VERSION "HNNBNNNYNNNNNNNNNNNNNNNNNNNNNNNNNNNNNNNNNN/4/%%%/4/'%**4NNN///"

NS_ :

BS_:

BU_: BAP_Tester Gateway_Max Getriebe_DQ Motor_konv Parksperre Schaltbetaetigung

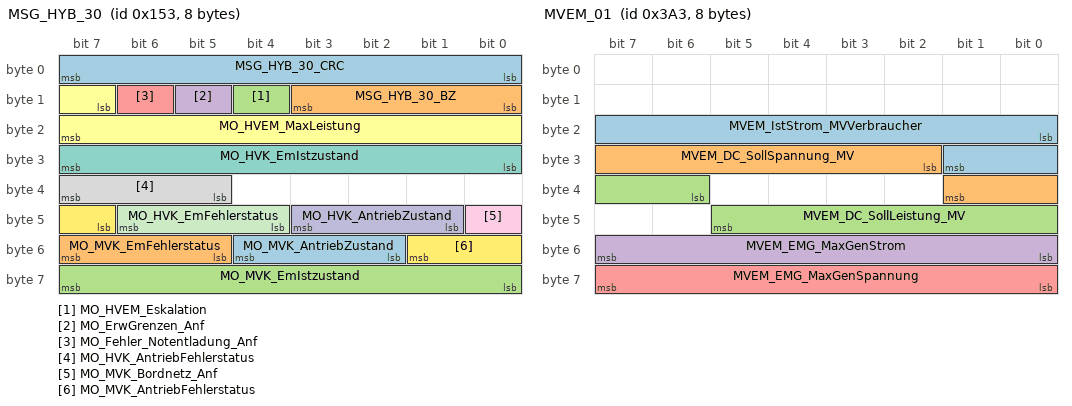
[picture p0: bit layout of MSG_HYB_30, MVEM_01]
BO_ 339 MSG_HYB_30: 8 Motor_konv
 SG_ MSG_HYB_30_CRC : 0|8@1+ (1,0) [0|255] ""  Gateway_Max
 SG_ MSG_HYB_30_BZ : 8|4@1+ (1,0) [0|15] ""  Gateway_Max
 SG_ MO_HVEM_Eskalation : 12|1@1+ (1.0,0.0) [0.0|1] ""  Gateway_Max
 SG_ MO_ErwGrenzen_Anf : 13|1@1+ (1.0,0.0) [0.0|1] ""  Gateway_Max
 SG_ MO_Fehler_Notentladung_Anf : 14|1@1+ (1.0,0.0) [0.0|1] ""  Gateway_Max
 SG_ MO_HVEM_MaxLeistung : 15|9@1+ (50,0) [0|25450] "Unit_Watt"  Gateway_Max
 SG_ MO_HVK_EmIstzustand : 24|8@1+ (1.0,0.0) [0.0|255] ""  Gateway_Max
 SG_ MO_HVK_AntriebFehlerstatus : 37|3@1+ (1.0,0.0) [0.0|7] ""  Gateway_Max
 SG_ MO_MVK_Bordnetz_Anf : 40|1@1+ (1.0,0.0) [0.0|1] ""  Gateway_Max
 SG_ MO_HVK_AntriebZustand : 41|3@1+ (1.0,0.0) [0.0|7] ""  Gateway_Max
 SG_ MO_HVK_EmFehlerstatus : 44|3@1+ (1.0,0.0) [0.0|7] ""  Gateway_Max
 SG_ MO_MVK_AntriebFehlerstatus : 47|3@1+ (1.0,0.0) [0.0|7] ""  Gateway_Max
 SG_ MO_MVK_AntriebZustand : 50|3@1+ (1.0,0.0) [0.0|7] ""  Gateway_Max
 SG_ MO_MVK_EmFehlerstatus : 53|3@1+ (1.0,0.0) [0.0|7] ""  Gateway_Max
 SG_ MO_MVK_EmIstzustand : 56|8@1+ (1.0,0.0) [0.0|255] ""  Gateway_Max

BO_ 931 MVEM_01: 8 Gateway_Max
 SG_ MVEM_IstStrom_MVVerbraucher : 16|10@1+ (1,-511) [-511|510] "Unit_Amper"  Motor_konv
 SG_ MVEM_DC_SollSpannung_MV : 26|8@1+ (0.25,0) [0.00|63.25] "Unit_Volt"  Vector__XXX
 SG_ MVEM_DC_SollLeistung_MV : 38|8@1+ (25,-6325) [-6325|0] "Unit_Watt"  Vector__XXX
 SG_ MVEM_EMG_MaxGenStrom : 48|8@1+ (2,0) [0|506] "Unit_Amper"  Vector__XXX
 SG_ MVEM_EMG_MaxGenSpannung : 56|8@1+ (0.25,0) [0.00|63.25] "Unit_Volt"  Vector__XXX

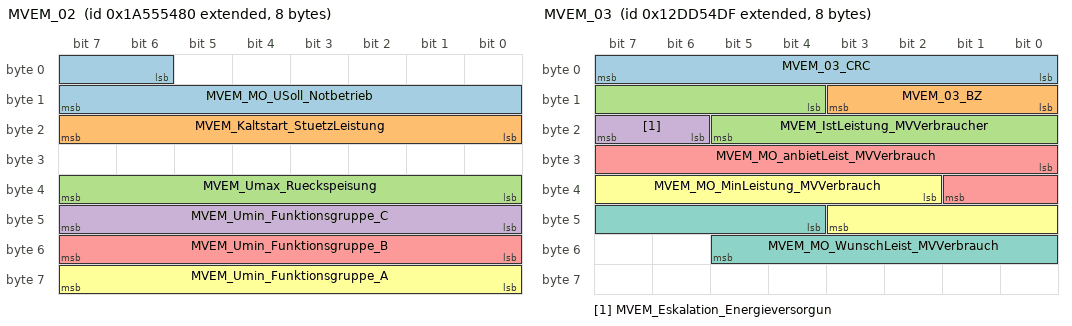
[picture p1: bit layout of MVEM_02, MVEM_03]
BO_ 2589283456 MVEM_02: 8 Gateway_Max
 SG_ MVEM_MO_USoll_Notbetrieb : 6|10@1+ (0.0625,0) [0.0000|63.8125] "Unit_Volt"  Motor_konv
 SG_ MVEM_Kaltstart_StuetzLeistung : 16|8@1+ (20,0) [0|5060] "Unit_Watt"  Vector__XXX
 SG_ MVEM_Umax_Rueckspeisung : 32|8@1+ (0.25,0) [0.00|63.25] "Unit_Volt"  Vector__XXX
 SG_ MVEM_Umin_Funktionsgruppe_C : 40|8@1+ (0.25,0) [0.00|63.25] "Unit_Volt"  Vector__XXX
 SG_ MVEM_Umin_Funktionsgruppe_B : 48|8@1+ (0.25,0) [0.00|63.25] "Unit_Volt"  Vector__XXX
 SG_ MVEM_Umin_Funktionsgruppe_A : 56|8@1+ (0.25,0) [0.00|63.25] "Unit_Volt"  Vector__XXX

BO_ 2463978719 MVEM_03: 8 Gateway_Max
 SG_ MVEM_03_CRC : 0|8@1+ (1,0) [0|255] ""  Motor_konv
 SG_ MVEM_03_BZ : 8|4@1+ (1,0) [0|15] ""  Motor_konv
 SG_ MVEM_IstLeistung_MVVerbraucher : 12|10@1+ (50,-10500) [-10500|40500] "Unit_Watt"  Motor_konv
 SG_ MVEM_Eskalation_Energieversorgun : 22|2@1+ (1.0,0.0) [0.0|3] ""  Motor_konv
 SG_ MVEM_MO_anbietLeist_MVVerbrauch : 24|10@1+ (50,-10500) [-10500|40500] "Unit_Watt"  Vector__XXX
 SG_ MVEM_MO_MinLeistung_MVVerbrauch : 34|10@1+ (50,-10500) [-10500|40500] "Unit_Watt"  Vector__XXX
 SG_ MVEM_MO_WunschLeist_MVVerbrauch : 44|10@1+ (50,-10500) [-10500|40500] "Unit_Watt"  Vector__XXX

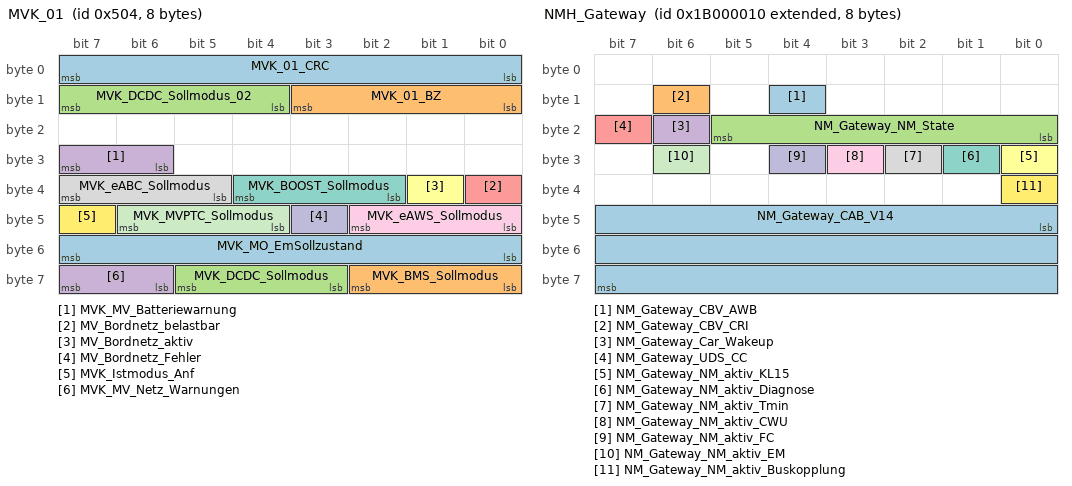
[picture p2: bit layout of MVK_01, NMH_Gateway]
BO_ 1284 MVK_01: 8 Gateway_Max
 SG_ MVK_01_CRC : 0|8@1+ (1,0) [0|255] ""  Vector__XXX
 SG_ MVK_01_BZ : 8|4@1+ (1,0) [0|15] ""  Vector__XXX
 SG_ MVK_DCDC_Sollmodus_02 : 12|4@1+ (1.0,0.0) [0.0|15] ""  Vector__XXX
 SG_ MVK_MV_Batteriewarnung : 30|2@1+ (1.0,0.0) [0.0|3] ""  Vector__XXX
 SG_ MV_Bordnetz_belastbar : 32|1@1+ (1.0,0.0) [0.0|1] ""  Vector__XXX
 SG_ MV_Bordnetz_aktiv : 33|1@1+ (1.0,0.0) [0.0|1] ""  Vector__XXX
 SG_ MVK_BOOST_Sollmodus : 34|3@1+ (1.0,0.0) [0.0|7] ""  Vector__XXX
 SG_ MVK_eABC_Sollmodus : 37|3@1+ (1.0,0.0) [0.0|7] ""  Vector__XXX
 SG_ MVK_eAWS_Sollmodus : 40|3@1+ (1.0,0.0) [0.0|7] ""  Vector__XXX
 SG_ MV_Bordnetz_Fehler : 43|1@1+ (1.0,0.0) [0.0|1] ""  Vector__XXX
 SG_ MVK_MVPTC_Sollmodus : 44|3@1+ (1.0,0.0) [0.0|7] ""  Vector__XXX
 SG_ MVK_Istmodus_Anf : 47|1@1+ (1.0,0.0) [0.0|1] ""  Vector__XXX
 SG_ MVK_MO_EmSollzustand : 48|8@1+ (1.0,0.0) [0.0|255] ""  Motor_konv
 SG_ MVK_BMS_Sollmodus : 56|3@1+ (1.0,0.0) [0.0|7] ""  Vector__XXX
 SG_ MVK_DCDC_Sollmodus : 59|3@1+ (1.0,0.0) [0.0|7] ""  Vector__XXX
 SG_ MVK_MV_Netz_Warnungen : 62|2@1+ (1.0,0.0) [0.0|3] ""  Vector__XXX

BO_ 2600468496 NMH_Gateway: 8 Gateway_Max
 SG_ NM_Gateway_CBV_AWB : 12|1@1+ (1.0,0.0) [0.0|1] ""  Vector__XXX
 SG_ NM_Gateway_CBV_CRI : 14|1@1+ (1.0,0.0) [0.0|1] ""  Vector__XXX
 SG_ NM_Gateway_NM_State : 16|6@1+ (1.0,0.0) [0.0|63] ""  Getriebe_DQ,Motor_konv,Parksperre,Schaltbetaetigung
 SG_ NM_Gateway_Car_Wakeup : 22|1@1+ (1.0,0.0) [0.0|1] ""  Vector__XXX
 SG_ NM_Gateway_UDS_CC : 23|1@1+ (1.0,0.0) [0.0|1] ""  Vector__XXX
 SG_ NM_Gateway_NM_aktiv_KL15 : 24|1@1+ (1.0,0.0) [0.0|1] ""  Vector__XXX
 SG_ NM_Gateway_NM_aktiv_Diagnose : 25|1@1+ (1.0,0.0) [0.0|1] ""  Vector__XXX
 SG_ NM_Gateway_NM_aktiv_Tmin : 26|1@1+ (1.0,0.0) [0.0|1] ""  Vector__XXX
 SG_ NM_Gateway_NM_aktiv_CWU : 27|1@1+ (1.0,0.0) [0.0|1] ""  Vector__XXX
 SG_ NM_Gateway_NM_aktiv_FC : 28|1@1+ (1.0,0.0) [0.0|1] ""  Vector__XXX
 SG_ NM_Gateway_NM_aktiv_EM : 30|1@1+ (1.0,0.0) [0.0|1] ""  Vector__XXX
 SG_ NM_Gateway_NM_aktiv_Buskopplung : 32|1@1+ (1.0,0.0) [0.0|1] ""  Vector__XXX
 SG_ NM_Gateway_CAB_V14 : 40|24@1+ (1.0,0.0) [0.0|16777215] ""  Vector__XXX

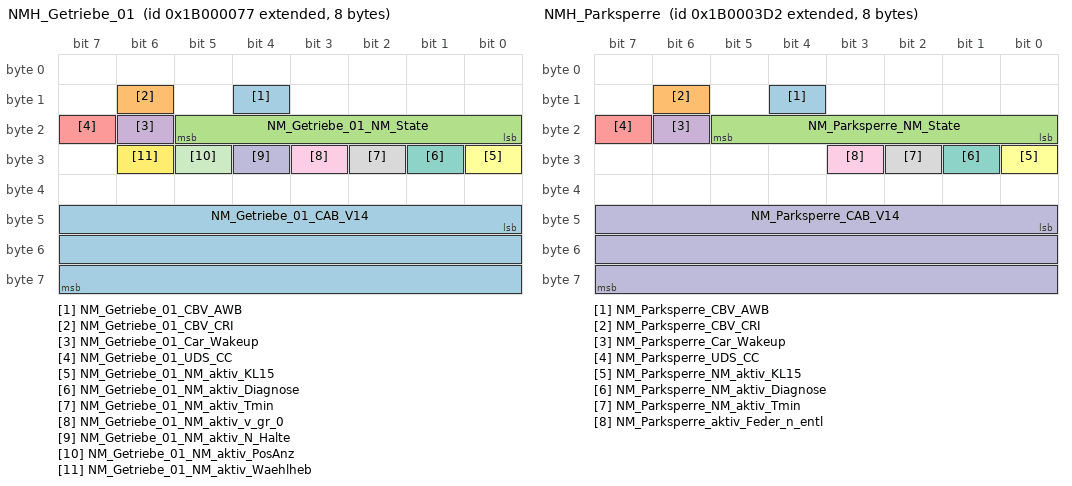
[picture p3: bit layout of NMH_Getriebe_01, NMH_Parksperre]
BO_ 2600468599 NMH_Getriebe_01: 8 Getriebe_DQ
 SG_ NM_Getriebe_01_CBV_AWB : 12|1@1+ (1.0,0.0) [0.0|1] ""  Gateway_Max
 SG_ NM_Getriebe_01_CBV_CRI : 14|1@1+ (1.0,0.0) [0.0|1] ""  Gateway_Max
 SG_ NM_Getriebe_01_NM_State : 16|6@1+ (1.0,0.0) [0.0|63] ""  Motor_konv,Parksperre,Schaltbetaetigung
 SG_ NM_Getriebe_01_Car_Wakeup : 22|1@1+ (1.0,0.0) [0.0|1] ""  Gateway_Max
 SG_ NM_Getriebe_01_UDS_CC : 23|1@1+ (1.0,0.0) [0.0|1] ""  Vector__XXX
 SG_ NM_Getriebe_01_NM_aktiv_KL15 : 24|1@1+ (1.0,0.0) [0.0|1] ""  Vector__XXX
 SG_ NM_Getriebe_01_NM_aktiv_Diagnose : 25|1@1+ (1.0,0.0) [0.0|1] ""  Vector__XXX
 SG_ NM_Getriebe_01_NM_aktiv_Tmin : 26|1@1+ (1.0,0.0) [0.0|1] ""  Vector__XXX
 SG_ NM_Getriebe_01_NM_aktiv_v_gr_0 : 27|1@1+ (1.0,0.0) [0.0|1] ""  Vector__XXX
 SG_ NM_Getriebe_01_NM_aktiv_N_Halte : 28|1@1+ (1.0,0.0) [0.0|1] ""  Vector__XXX
 SG_ NM_Getriebe_01_NM_aktiv_PosAnz : 29|1@1+ (1.0,0.0) [0.0|1] ""  Vector__XXX
 SG_ NM_Getriebe_01_NM_aktiv_Waehlheb : 30|1@1+ (1.0,0.0) [0.0|1] ""  Vector__XXX
 SG_ NM_Getriebe_01_CAB_V14 : 40|24@1+ (1.0,0.0) [0.0|16777215] ""  Gateway_Max

BO_ 2600468598 NMH_MO_01: 8 Motor_konv
 SG_ NM_MO_01_CBV_AWB : 12|1@1+ (1.0,0.0) [0.0|1] ""  Gateway_Max
 SG_ NM_MO_01_CBV_CRI : 14|1@1+ (1.0,0.0) [0.0|1] ""  Gateway_Max
 SG_ NM_MO_01_NM_State : 16|6@1+ (1.0,0.0) [0.0|63] ""  Getriebe_DQ,Parksperre,Schaltbetaetigung
 SG_ NM_MO_01_Car_Wakeup : 22|1@1+ (1.0,0.0) [0.0|1] ""  Gateway_Max
 SG_ NM_MO_01_UDS_CC : 23|1@1+ (1.0,0.0) [0.0|1] ""  Vector__XXX
 SG_ NM_MO_01_NM_aktiv_KL15 : 24|1@1+ (1.0,0.0) [0.0|1] ""  Vector__XXX
 SG_ NM_MO_01_NM_aktiv_Diagnose : 25|1@1+ (1.0,0.0) [0.0|1] ""  Vector__XXX
 SG_ NM_MO_01_NM_aktiv_Tmin : 26|1@1+ (1.0,0.0) [0.0|1] ""  Vector__XXX
 SG_ NM_MO_01_NM_aktiv_Betankung : 27|1@1+ (1.0,0.0) [0.0|1] ""  Vector__XXX
 SG_ NM_MO_01_NM_aktiv_Oelstandsmes : 28|1@1+ (1.0,0.0) [0.0|1] ""  Vector__XXX
 SG_ NM_MO_01_NM_aktiv_Waehlhebel : 30|1@1+ (1.0,0.0) [0.0|1] ""  Vector__XXX
 SG_ NM_MO_01_NM_aktiv_NOx_PM_SensDia : 32|1@1+ (1.0,0.0) [0.0|1] ""  Vector__XXX
 SG_ NM_MO_01_NM_aktiv_Anf_RSG : 34|1@1+ (1.0,0.0) [0.0|1] ""  Vector__XXX
 SG_ NM_MO_01_NM_aktiv_HV_Abschaltung : 35|1@1+ (1.0,0.0) [0.0|1] ""  Vector__XXX
 SG_ NM_MO_01_NM_aktiv_EKP_Vorlauf : 36|1@1+ (1.0,0.0) [0.0|1] ""  Vector__XXX
 SG_ NM_MO_01_NM_aktiv_STH_Betrieb : 37|1@1+ (1.0,0.0) [0.0|1] ""  Vector__XXX
 SG_ NM_MO_01_NM_aktiv_Hochvolt : 38|1@1+ (1.0,0.0) [0.0|1] ""  Vector__XXX
 SG_ NM_MO_01_NM_aktiv_AnzKLuefter : 39|1@1+ (1.0,0.0) [0.0|1] ""  Vector__XXX
 SG_ NM_MO_01_CAB_V14 : 40|24@1+ (1.0,0.0) [0.0|16777215] ""  Gateway_Max

BO_ 2600469458 NMH_Parksperre: 8 Parksperre
 SG_ NM_Parksperre_CBV_AWB : 12|1@1+ (1.0,0.0) [0.0|1] ""  Gateway_Max
 SG_ NM_Parksperre_CBV_CRI : 14|1@1+ (1.0,0.0) [0.0|1] ""  Gateway_Max
 SG_ NM_Parksperre_NM_State : 16|6@1+ (1.0,0.0) [0.0|63] ""  Getriebe_DQ,Motor_konv,Schaltbetaetigung
 SG_ NM_Parksperre_Car_Wakeup : 22|1@1+ (1.0,0.0) [0.0|1] ""  Gateway_Max
 SG_ NM_Parksperre_UDS_CC : 23|1@1+ (1.0,0.0) [0.0|1] ""  Vector__XXX
 SG_ NM_Parksperre_NM_aktiv_KL15 : 24|1@1+ (1.0,0.0) [0.0|1] ""  Vector__XXX
 SG_ NM_Parksperre_NM_aktiv_Diagnose : 25|1@1+ (1.0,0.0) [0.0|1] ""  Vector__XXX
 SG_ NM_Parksperre_NM_aktiv_Tmin : 26|1@1+ (1.0,0.0) [0.0|1] ""  Vector__XXX
 SG_ NM_Parksperre_aktiv_Feder_n_entl : 27|1@1+ (1.0,0.0) [0.0|1] ""  Vector__XXX
 SG_ NM_Parksperre_CAB_V14 : 40|24@1+ (1.0,0.0) [0.0|16777215] ""  Gateway_Max

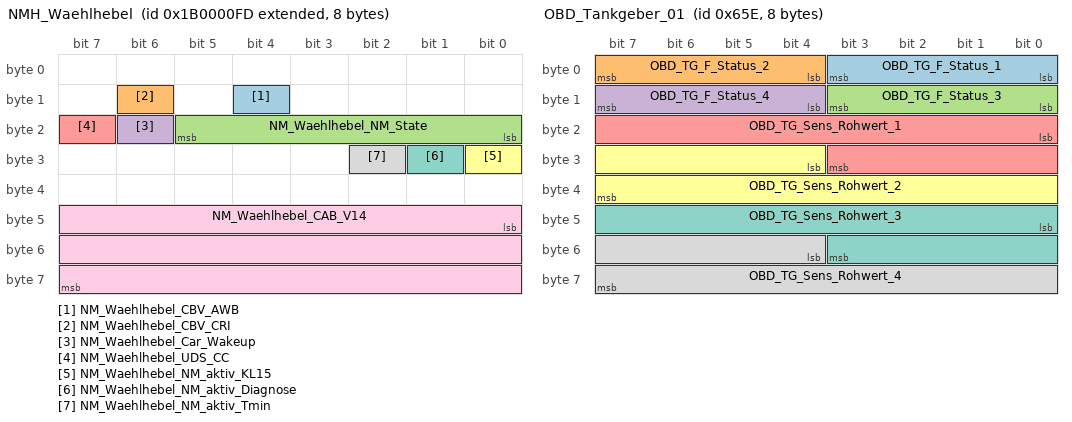
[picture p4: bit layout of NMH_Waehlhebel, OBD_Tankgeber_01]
BO_ 2600468733 NMH_Waehlhebel: 8 Schaltbetaetigung
 SG_ NM_Waehlhebel_CBV_AWB : 12|1@1+ (1.0,0.0) [0.0|1] ""  Gateway_Max
 SG_ NM_Waehlhebel_CBV_CRI : 14|1@1+ (1.0,0.0) [0.0|1] ""  Gateway_Max
 SG_ NM_Waehlhebel_NM_State : 16|6@1+ (1.0,0.0) [0.0|63] ""  Getriebe_DQ,Motor_konv,Parksperre
 SG_ NM_Waehlhebel_Car_Wakeup : 22|1@1+ (1.0,0.0) [0.0|1] ""  Gateway_Max
 SG_ NM_Waehlhebel_UDS_CC : 23|1@1+ (1.0,0.0) [0.0|1] ""  Vector__XXX
 SG_ NM_Waehlhebel_NM_aktiv_KL15 : 24|1@1+ (1.0,0.0) [0.0|1] ""  Vector__XXX
 SG_ NM_Waehlhebel_NM_aktiv_Diagnose : 25|1@1+ (1.0,0.0) [0.0|1] ""  Vector__XXX
 SG_ NM_Waehlhebel_NM_aktiv_Tmin : 26|1@1+ (1.0,0.0) [0.0|1] ""  Vector__XXX
 SG_ NM_Waehlhebel_CAB_V14 : 40|24@1+ (1.0,0.0) [0.0|16777215] ""  Gateway_Max

BO_ 1630 OBD_Tankgeber_01: 8 Gateway_Max
 SG_ OBD_TG_F_Status_1 : 0|4@1+ (1.0,0.0) [0.0|15] ""  Motor_konv
 SG_ OBD_TG_F_Status_2 : 4|4@1+ (1.0,0.0) [0.0|15] ""  Motor_konv
 SG_ OBD_TG_F_Status_3 : 8|4@1+ (1.0,0.0) [0.0|15] ""  Motor_konv
 SG_ OBD_TG_F_Status_4 : 12|4@1+ (1.0,0.0) [0.0|15] ""  Motor_konv
 SG_ OBD_TG_Sens_Rohwert_1 : 16|12@1+ (0.5,0) [0.0|2047.5] "Unit_Ohm"  Motor_konv
 SG_ OBD_TG_Sens_Rohwert_2 : 28|12@1+ (0.5,0) [0.0|2047.5] "Unit_Ohm"  Motor_konv
 SG_ OBD_TG_Sens_Rohwert_3 : 40|12@1+ (0.5,0) [0.0|2047.5] "Unit_Ohm"  Motor_konv
 SG_ OBD_TG_Sens_Rohwert_4 : 52|12@1+ (0.5,0) [0.0|2047.5] "Unit_Ohm"  Motor_konv

BO_ 2621440636 OBDC_EMotor_01_Req_FD: 64 Gateway_Max
 SG_ OBDC_EMotor_01_Req_FD_Data : 0|512@1+ (1.0,0.0) [0.0|13407807929942597099574024998205846127479365820592393377723561443721764030073546976801874298166903427690031858186486050853753882811946569946433649006084095] ""  Vector__XXX

BO_ 2621571708 OBDC_EMotor_01_Resp_FD: 64 Vector__XXX
 SG_ OBDC_EMotor_01_Resp_FD_Data : 0|512@1+ (1.0,0.0) [0.0|13407807929942597099574024998205846127479365820592393377723561443721764030073546976801874298166903427690031858186486050853753882811946569946433649006084095] ""  Gateway_Max

BO_ 2621440696 OBDC_EMotor_02_Req_FD: 64 Gateway_Max
 SG_ OBDC_EMotor_02_Req_FD_Data : 0|512@1+ (1.0,0.0) [0.0|13407807929942597099574024998205846127479365820592393377723561443721764030073546976801874298166903427690031858186486050853753882811946569946433649006084095] ""  Vector__XXX

BO_ 2621571768 OBDC_EMotor_02_Resp_FD: 64 Vector__XXX
 SG_ OBDC_EMotor_02_Resp_FD_Data : 0|512@1+ (1.0,0.0) [0.0|13407807929942597099574024998205846127479365820592393377723561443721764030073546976801874298166903427690031858186486050853753882811946569946433649006084095] ""  Gateway_Max

BO_ 2549940736 OBDC_Funktionaler_Req_All: 8 Gateway_Max
 SG_ OBDC_Funktionaler_Req_All_Data : 0|64@1+ (1.0,0.0) [0.0|18446744073709551615] ""  Vector__XXX

BO_ 2621506048 OBDC_Funktionaler_Req_All_FD: 64 Gateway_Max
 SG_ OBDC_Funktion_Req_All_FD_Data : 0|512@1+ (1.0,0.0) [0.0|13407807929942597099574024998205846127479365820592393377723561443721764030073546976801874298166903427690031858186486050853753882811946569946433649006084095] ""  Getriebe_DQ,Motor_konv

BO_ 2621440631 OBDC_Getriebe_01_Req_FD: 64 Gateway_Max
 SG_ OBDC_Getriebe_01_Req_FD_Data : 0|512@1+ (1.0,0.0) [0.0|13407807929942597099574024998205846127479365820592393377723561443721764030073546976801874298166903427690031858186486050853753882811946569946433649006084095] ""  Getriebe_DQ

BO_ 2621571703 OBDC_Getriebe_01_Resp_FD: 64 Getriebe_DQ
 SG_ OBDC_Getriebe_01_Resp_FD_Data : 0|512@1+ (1.0,0.0) [0.0|13407807929942597099574024998205846127479365820592393377723561443721764030073546976801874298166903427690031858186486050853753882811946569946433649006084095] ""  Gateway_Max

BO_ 2621702713 OBDC_LCU_SMH_Req_FD: 64 Gateway_Max
 SG_ OBDC_LCU_SMH_Req_FD_Data : 0|512@1+ (1.0,0.0) [0.0|13407807929942597099574024998205846127479365820592393377723561443721764030073546976801874298166903427690031858186486050853753882811946569946433649006084095] ""  Vector__XXX

BO_ 2621833785 OBDC_LCU_SMH_Resp_FD: 64 Vector__XXX
 SG_ OBDC_LCU_SMH_Resp_FD_Data : 0|512@1+ (1.0,0.0) [0.0|13407807929942597099574024998205846127479365820592393377723561443721764030073546976801874298166903427690031858186486050853753882811946569946433649006084095] ""  Gateway_Max

BO_ 2621440630 OBDC_MO_01_Req_FD: 64 Gateway_Max
 SG_ OBDC_MO_01_Req_FD_Data : 0|512@1+ (1.0,0.0) [0.0|13407807929942597099574024998205846127479365820592393377723561443721764030073546976801874298166903427690031858186486050853753882811946569946433649006084095] ""  Motor_konv

BO_ 2621571702 OBDC_MO_01_Resp_FD: 64 Motor_konv
 SG_ OBDC_MO_01_Resp_FD_Data : 0|512@1+ (1.0,0.0) [0.0|13407807929942597099574024998205846127479365820592393377723561443721764030073546976801874298166903427690031858186486050853753882811946569946433649006084095] ""  Gateway_Max

BO_ 2621440645 OBDC_RSG_Req_FD: 64 Gateway_Max
 SG_ OBDC_RSG_Req_FD_Data : 0|512@1+ (1.0,0.0) [0.0|13407807929942597099574024998205846127479365820592393377723561443721764030073546976801874298166903427690031858186486050853753882811946569946433649006084095] ""  Vector__XXX

BO_ 2621571717 OBDC_RSG_Resp_FD: 64 Vector__XXX
 SG_ OBDC_RSG_Resp_FD_Data : 0|512@1+ (1.0,0.0) [0.0|13407807929942597099574024998205846127479365820592393377723561443721764030073546976801874298166903427690031858186486050853753882811946569946433649006084095] ""  Gateway_Max

BO_ 2549875300 OBDC_Soundaktor2_Req: 8 Gateway_Max
 SG_ OBDC_Soundaktor2_Req_Data : 0|64@1+ (1.0,0.0) [0.0|18446744073709551615] ""  Vector__XXX

BO_ 2550006372 OBDC_Soundaktor2_Resp: 8 Vector__XXX
 SG_ OBDC_Soundaktor2_Resp_Data : 0|64@1+ (1.0,0.0) [0.0|18446744073709551615] ""  Gateway_Max

BO_ 2549875228 OBDC_Soundaktor_Req: 8 Gateway_Max
 SG_ OBDC_Soundaktor_Req_Data : 0|64@1+ (1.0,0.0) [0.0|18446744073709551615] ""  Vector__XXX

BO_ 2550006300 OBDC_Soundaktor_Resp: 8 Vector__XXX
 SG_ OBDC_Soundaktor_Resp_Data : 0|64@1+ (1.0,0.0) [0.0|18446744073709551615] ""  Gateway_Max

BO_ 2549903629 OBDC_SSN_eBooster_Req: 8 Gateway_Max
 SG_ OBDC_SSN_eBooster_Req_Data : 0|64@1+ (1.0,0.0) [0.0|18446744073709551615] ""  Vector__XXX

BO_ 2550034701 OBDC_SSN_eBooster_Resp: 8 Vector__XXX
 SG_ OBDC_SSN_eBooster_Resp_Data : 0|64@1+ (1.0,0.0) [0.0|18446744073709551615] ""  Gateway_Max

BO_ 2549903684 OBDC_SSN_EKAT_Req: 8 Gateway_Max
 SG_ OBDC_SSN_EKAT_Req_Data : 0|64@1+ (1.0,0.0) [0.0|18446744073709551615] ""  Vector__XXX

BO_ 2550034756 OBDC_SSN_EKAT_Resp: 8 Vector__XXX
 SG_ OBDC_SSN_EKAT_Resp_Data : 0|64@1+ (1.0,0.0) [0.0|18446744073709551615] ""  Gateway_Max

BO_ 2549903608 OBDC_SSN_MTFP_Req: 8 Gateway_Max
 SG_ OBDC_SSN_MTFP_Req_Data : 0|64@1+ (1.0,0.0) [0.0|18446744073709551615] ""  Vector__XXX

BO_ 2550034680 OBDC_SSN_MTFP_Resp: 8 Vector__XXX
 SG_ OBDC_SSN_MTFP_Resp_Data : 0|64@1+ (1.0,0.0) [0.0|18446744073709551615] ""  Gateway_Max

BO_ 2621468994 OBDC_SSN_Parksperre_Req_FD: 64 Gateway_Max
 SG_ OBDC_SSN_Parksperre_Req_FD_Data : 0|512@1+ (1.0,0.0) [0.0|13407807929942597099574024998205846127479365820592393377723561443721764030073546976801874298166903427690031858186486050853753882811946569946433649006084095] ""  Parksperre

BO_ 2621600066 OBDC_SSN_Parksperre_Resp_FD: 64 Parksperre
 SG_ OBDC_SSN_Parksperre_Resp_FD_Data : 0|512@1+ (1.0,0.0) [0.0|13407807929942597099574024998205846127479365820592393377723561443721764030073546976801874298166903427690031858186486050853753882811946569946433649006084095] ""  Gateway_Max

BO_ 2564502513 OBDx_allOBD_Req: 8 Gateway_Max
 SG_ OBDx_allOBD_Req_Data : 0|64@1+ (1.0,0.0) [0.0|18446744073709551615] ""  Getriebe_DQ,Motor_konv

BO_ 2564424433 OBDx_Getriebe_01_Req: 8 Gateway_Max
 SG_ OBDx_Getriebe_01_Req_Data : 0|64@1+ (1.0,0.0) [0.0|18446744073709551615] ""  Getriebe_DQ

BO_ 2564485378 OBDx_Getriebe_01_Resp: 8 Getriebe_DQ
 SG_ OBDx_Getriebe_01_Resp_Data : 0|64@1+ (1.0,0.0) [0.0|18446744073709551615] ""  Gateway_Max

BO_ 2564429809 OBDx_LCU_SMH_Req: 8 Gateway_Max
 SG_ OBDx_LCU_SMH_Req_Data : 0|64@1+ (1.0,0.0) [0.0|18446744073709551615] ""  Vector__XXX

BO_ 2564485399 OBDx_LCU_SMH_Resp: 8 Vector__XXX
 SG_ OBDx_LCU_SMH_Resp_Data : 0|64@1+ (1.0,0.0) [0.0|18446744073709551615] ""  Gateway_Max

BO_ 2564425457 OBDx_LE1_Req: 8 Gateway_Max
 SG_ OBDx_LE1_Req_Data : 0|64@1+ (1.0,0.0) [0.0|18446744073709551615] ""  Vector__XXX

BO_ 2564485382 OBDx_LE1_Resp: 8 Vector__XXX
 SG_ OBDx_LE1_Resp_Data : 0|64@1+ (1.0,0.0) [0.0|18446744073709551615] ""  Gateway_Max

BO_ 2564425713 OBDx_LE2_Req: 8 Gateway_Max
 SG_ OBDx_LE2_Req_Data : 0|64@1+ (1.0,0.0) [0.0|18446744073709551615] ""  Vector__XXX

BO_ 2564485383 OBDx_LE2_Resp: 8 Vector__XXX
 SG_ OBDx_LE2_Resp_Data : 0|64@1+ (1.0,0.0) [0.0|18446744073709551615] ""  Gateway_Max

BO_ 2564424177 OBDx_MO_01_Req: 8 Gateway_Max
 SG_ OBDx_MO_01_Req_Data : 0|64@1+ (1.0,0.0) [0.0|18446744073709551615] ""  Motor_konv

BO_ 2564485377 OBDx_MO_01_Resp: 8 Motor_konv
 SG_ OBDx_MO_01_Resp_Data : 0|64@1+ (1.0,0.0) [0.0|18446744073709551615] ""  Gateway_Max

BO_ 2564428017 OBDx_RSG_Req: 8 Gateway_Max
 SG_ OBDx_RSG_Req_Data : 0|64@1+ (1.0,0.0) [0.0|18446744073709551615] ""  Vector__XXX

BO_ 2564485392 OBDx_RSG_Resp: 8 Vector__XXX
 SG_ OBDx_RSG_Resp_Data : 0|64@1+ (1.0,0.0) [0.0|18446744073709551615] ""  Gateway_Max

BO_ 2463978776 OBG_01: 64 Gateway_Max
 SG_ OBG_01_CRC : 0|8@1+ (1,0) [0|255] ""  Vector__XXX
 SG_ OBG_01_BZ : 8|4@1+ (1,0) [0|15] ""  Vector__XXX
 SG_ HVLE_IstSpannung_HV : 12|10@1+ (1,0) [0|1021] "Unit_Volt"  Vector__XXX
 SG_ HVLE_Ist_Wirkungsgrad : 22|7@1+ (1,0) [0|100] "Unit_PerCent"  Vector__XXX
 SG_ HVLE_Netzfrequenz_EVU : 29|9@1+ (0.1,40) [40.0|80.0] "Unit_Hertz"  Vector__XXX
 SG_ HVLE_Energiemenge_Laden : 38|14@1+ (40,0) [0|654800] "Unit_WattHour"  Vector__XXX
 SG_ HVLE_I_istAC_Netz_L1 : 52|9@1+ (0.1,0) [0.0|50.8] "Unit_Amper"  Vector__XXX
 SG_ HVLE_I_istAC_Netz_L2 : 61|9@1+ (0.1,0) [0.0|50.8] "Unit_Amper"  Vector__XXX
 SG_ HVLE_I_istAC_Netz_L3 : 70|9@1+ (0.1,0) [0.0|50.8] "Unit_Amper"  Vector__XXX
 SG_ HVLE_U_istAC_Netz_L1 : 79|9@1+ (1,0) [0|508] "Unit_Volt"  Vector__XXX
 SG_ HVLE_U_istAC_Netz_L2 : 88|9@1+ (1,0) [0|508] "Unit_Volt"  Vector__XXX
 SG_ HVLE_U_istAC_Netz_L3 : 97|9@1+ (1,0) [0|508] "Unit_Volt"  Vector__XXX
 SG_ HVLE_OBG_DC_MaxStrom : 106|11@1+ (0.1,0) [0.0|204.5] "Unit_Amper"  Vector__XXX
 SG_ HVLE_OBG_DC_IstStrom : 117|11@1+ (0.1,0) [0.0|204.5] "Unit_Amper"  Vector__XXX
 SG_ HVLE_Netzmodus : 128|4@1+ (1.0,0.0) [0.0|15] ""  Vector__XXX
 SG_ HVLE_Derating_Temperatur : 132|1@1+ (1.0,0.0) [0.0|1] ""  Vector__XXX
 SG_ HVLE_OBG_IstModus : 133|3@1+ (1.0,0.0) [0.0|7] ""  Vector__XXX
 SG_ HVLE_OBG_Warnzustand : 136|4@1+ (1.0,0.0) [0.0|15] ""  Vector__XXX
 SG_ HVLE_OBG_Fehlerstatus : 140|1@1+ (1.0,0.0) [0.0|1] ""  Vector__XXX
 SG_ HVLE_OBG_Status_EoHVL : 141|2@1+ (1.0,0.0) [0.0|3] ""  Vector__XXX
 SG_ HVLE_OBG_Fehlerstrom : 143|1@1+ (1.0,0.0) [0.0|1] ""  Vector__XXX
 SG_ HVLE_OBG_ACDC_IstLeistung : 144|11@1+ (25,0) [0|45000] "Unit_Watt"  Vector__XXX
 SG_ HVLE_OBG_ACDC_MaxLeistung : 155|11@1+ (25,0) [0|45000] "Unit_Watt"  Vector__XXX
 SG_ HVLE_OBG_AC_maxStrom : 166|10@1+ (0.1,0) [0.0|100.0] "Unit_Amper"  Vector__XXX
 SG_ HVLE_OBG_AC_maxSpannung : 176|10@1+ (1,0) [0|1000] "Unit_Volt"  Vector__XXX
 SG_ HVLE_AnzahlVerwendeterPhasen : 186|2@1+ (1.0,0.0) [0.0|3] ""  Vector__XXX
 SG_ HVLE_AsymmetrischLadenMoeglich : 188|1@1+ (1.0,0.0) [0.0|1] ""  Vector__XXX
 SG_ HVLE_OBG_Typ_verbaut : 189|3@1+ (1.0,0.0) [0.0|7] ""  Vector__XXX
 SG_ HVLE_PE_Monitor : 192|3@1+ (1.0,0.0) [0.0|7] ""  Vector__XXX
 SG_ HVLE_OBG_Status_Spgfreiheit : 195|2@1+ (1.0,0.0) [0.0|3] ""  Vector__XXX
 SG_ HVLE_OBG_Kuehltemperatur : 197|8@1+ (1,-40) [-40|213] "Unit_DegreCelsi"  Vector__XXX
 SG_ SOK_OBG_01_Signatur : 480|32@1+ (1.0,0.0) [0.0|4294967295] ""  Vector__XXX

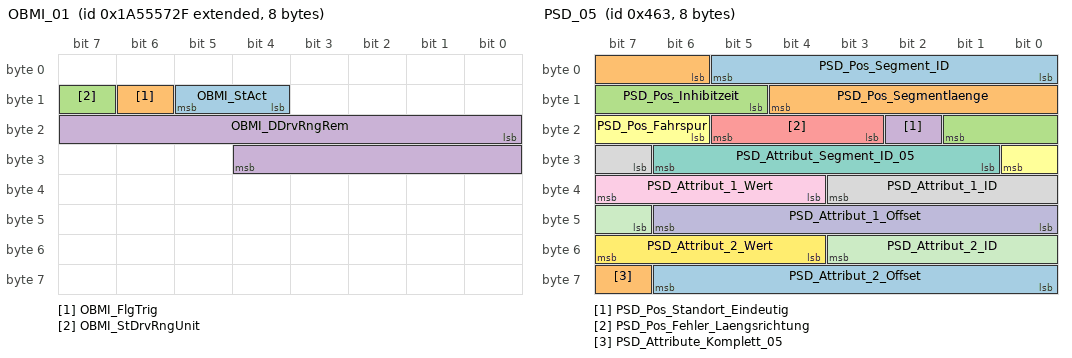
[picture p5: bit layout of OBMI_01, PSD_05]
BO_ 2589284143 OBMI_01: 8 Motor_konv
 SG_ OBMI_StAct : 12|2@1+ (1.0,0.0) [0.0|3] ""  Gateway_Max
 SG_ OBMI_FlgTrig : 14|1@1+ (1.0,0.0) [0.0|1] ""  Gateway_Max
 SG_ OBMI_StDrvRngUnit : 15|1@1+ (1.0,0.0) [0.0|1] ""  Gateway_Max
 SG_ OBMI_DDrvRngRem : 16|13@1+ (1,0) [0|8189] "Unit_None"  Gateway_Max

BO_ 2589283656 ORU_01: 8 Gateway_Max
 SG_ ORU_Warnung : 58|2@1+ (1.0,0.0) [0.0|3] ""  Vector__XXX
 SG_ ORU_Status : 61|3@1+ (1.0,0.0) [0.0|7] ""  Motor_konv

BO_ 518 Parken_01: 24 Gateway_Max
 SG_ Parken_01_CRC : 0|8@1+ (1,0) [0|255] ""  Motor_konv
 SG_ Parken_01_BZ : 8|4@1+ (1,0) [0|15] ""  Motor_konv
 SG_ Parken_BKD_Anf : 12|4@1+ (0.1,0) [0.0|1.3] "Unit_Secon"  Vector__XXX
 SG_ Parken_Verz_Anf : 16|7@1+ (0.1,-12.6) [-12.6|-0.1] "Unit_MeterPerSeconSquar"  Vector__XXX
 SG_ Parken_Prefill_Anf : 23|1@1+ (1.0,0.0) [0.0|1] ""  Vector__XXX
 SG_ Parken_Warnruck_Anf : 24|2@1+ (1.0,0.0) [0.0|3] ""  Vector__XXX
 SG_ Parken_Verz_Anf_ASIL : 26|2@1+ (1.0,0.0) [0.0|3] ""  Vector__XXX
 SG_ Parken_Warnruckeln_Anf : 28|2@1+ (1.0,0.0) [0.0|3] ""  Vector__XXX
 SG_ Parken_beibehalten : 30|2@1+ (1.0,0.0) [0.0|3] ""  Vector__XXX
 SG_ Parken_Anforderung_HMS : 32|3@1+ (1.0,0.0) [0.0|7] ""  Vector__XXX
 SG_ Parken_Fahrbereitschaft_Anf : 35|1@1+ (1.0,0.0) [0.0|1] ""  Motor_konv
 SG_ Parken_Motorlauf_Anf : 36|2@1+ (1.0,0.0) [0.0|3] ""  Motor_konv
 SG_ IPA_TPA_ausgerichtetes_Parken : 38|2@1+ (1.0,0.0) [0.0|3] ""  Vector__XXX
 SG_ Parken_Notstopp_Anf : 40|2@1+ (1.0,0.0) [0.0|3] ""  Vector__XXX
 SG_ Parken_Anhalteweg_Anf : 42|10@1+ (0.01,0) [0.00|10.21] "Unit_Meter"  Vector__XXX
 SG_ Parken_aktives_System : 52|4@1+ (1.0,0.0) [0.0|15] ""  Motor_konv
 SG_ Parken_max_Beschleunigung : 56|7@1+ (0.1,-6) [-5.9|6.1] "Unit_MeterPerSeconSquar"  Motor_konv
 SG_ Parken_QFK_KruemmSoll : 64|15@1+ (0.0000067,0) [0E-7|0.2195389] "Unit_MeterInver"  Vector__XXX
 SG_ Parken_QFK_KruemmSoll_VZ : 79|1@1+ (1.0,0.0) [0.0|1] ""  Vector__XXX
 SG_ Parken_QFK_Spuerb : 80|8@1+ (0.4,0) [0.0|100.0] "Unit_PerCent"  Vector__XXX
 SG_ Parken_QFK_AnfStat : 88|4@1+ (1.0,0.0) [0.0|15] ""  Vector__XXX
 SG_ Parken_QFK_Signal1 : 92|10@1+ (1,0) [0|1023] ""  Vector__XXX
 SG_ Parken_QFK_Art1 : 102|3@1+ (1,0) [0|7] ""  Vector__XXX
 SG_ Parken_QFK_Art2 : 105|3@1+ (1,0) [0|7] ""  Vector__XXX
 SG_ Parken_QFK_Signal2 : 108|10@1+ (1,0) [0|1023] ""  Vector__XXX
 SG_ Parken_Sollbeschleunigung : 118|9@1+ (0.01,-4.11) [-4.10|1.00] "Unit_MeterPerSeconSquar"  Motor_konv
 SG_ Parken_Status_IPA_TSK : 128|4@1+ (1.0,0.0) [0.0|15] ""  Getriebe_DQ,Motor_konv
 SG_ Parken_erhoehtes_Moment : 132|4@1+ (1.0,0.0) [0.0|15] ""  Motor_konv
 SG_ Parken_max_Geschwindigkeit : 136|8@1+ (0.1,0) [0.1|25.0] "Unit_KiloMeterPerHour"  Motor_konv
 SG_ Parken_Soll_Anhalteweg_Anf : 144|10@1+ (0.01,0) [0.00|10.21] "Unit_Meter"  Vector__XXX
 SG_ Parken_Fahrstufenwunsch : 154|3@1+ (1.0,0.0) [0.0|7] ""  Vector__XXX
 SG_ Parken_Schleichfahrt_Anf : 157|1@1+ (1.0,0.0) [0.0|1] ""  Vector__XXX
 SG_ Parken_Bordstein_Winkel : 158|7@1+ (1,-1) [0|90] "Unit_DegreOfArc"  Motor_konv
 SG_ IPA_TPA_Remote : 176|2@1+ (1.0,0.0) [0.0|3] ""  Vector__XXX
 SG_ IPA_TPA_Remote_Anf : 178|2@1+ (1.0,0.0) [0.0|3] ""  Vector__XXX
 SG_ IPA_TPA_Fehler : 180|4@1+ (1.0,0.0) [0.0|15] ""  Vector__XXX
 SG_ IPA_TPA_Abbruch : 184|4@1+ (1.0,0.0) [0.0|15] ""  Vector__XXX
 SG_ IPA_TPA_Status : 188|4@1+ (1.0,0.0) [0.0|15] ""  Vector__XXX

BO_ 1175 Parkhilfe_01: 8 Gateway_Max
 SG_ PH_Visualisierung : 0|3@1+ (1.0,0.0) [0.0|7] ""  Vector__XXX
 SG_ PDC_Tonausgabe_Front : 4|4@1+ (1.0,0.0) [0.0|15] ""  Vector__XXX
 SG_ PDC_Tonausgabe_Heck : 8|4@1+ (1.0,0.0) [0.0|15] ""  Vector__XXX
 SG_ PH_nachtr_Stopp_Anf : 12|1@1+ (1.0,0.0) [0.0|1] ""  Motor_konv
 SG_ PH_Abschaltursache : 13|3@1+ (1.0,0.0) [0.0|7] ""  Vector__XXX
 SG_ PH_Opt_Anzeige_V_ein : 16|1@1+ (1.0,0.0) [0.0|1] ""  Vector__XXX
 SG_ PH_Opt_Anzeige_H_ein : 17|1@1+ (1.0,0.0) [0.0|1] ""  Vector__XXX
 SG_ PH_Opt_Anz_V_Hindernis : 18|1@1+ (1.0,0.0) [0.0|1] ""  Vector__XXX
 SG_ PH_Opt_Anz_H_Hindernis : 19|1@1+ (1.0,0.0) [0.0|1] ""  Vector__XXX
 SG_ PH_Tongeber_V_aktiv : 20|1@1+ (1.0,0.0) [0.0|1] ""  Vector__XXX
 SG_ PH_Tongeber_H_aktiv : 21|1@1+ (1.0,0.0) [0.0|1] ""  Vector__XXX
 SG_ PH_Tongeber_mute : 22|1@1+ (1.0,0.0) [0.0|1] ""  Vector__XXX
 SG_ PH_Anf_Audioabsenkung : 23|1@1+ (1.0,0.0) [0.0|1] ""  Vector__XXX
 SG_ PH_Tongeber_H_verfuegbar : 24|1@1+ (1.0,0.0) [0.0|1] ""  Vector__XXX
 SG_ PLA_Anf_Aufschaltung_RVC : 25|1@1+ (1.0,0.0) [0.0|1] ""  Vector__XXX
 SG_ PH_Taster : 28|2@1+ (1.0,0.0) [0.0|3] ""  Vector__XXX
 SG_ PH_Anf_Verdeck : 30|2@1+ (1.0,0.0) [0.0|3] ""  Vector__XXX
 SG_ PH_Frequenz_hinten : 32|4@1+ (1,0) [0|15] ""  Vector__XXX
 SG_ PH_Lautstaerke_hinten : 36|4@1+ (1,0) [0|15] ""  Vector__XXX
 SG_ PH_Frequenz_vorn : 40|4@1+ (1,0) [0|15] ""  Vector__XXX
 SG_ PH_Lautstaerke_vorn : 44|4@1+ (1,0) [0|15] ""  Vector__XXX
 SG_ PH_StartStopp_Info : 49|2@1+ (1.0,0.0) [0.0|3] ""  Motor_konv
 SG_ PH_Stoermeldung : 52|4@1+ (1.0,0.0) [0.0|15] ""  Vector__XXX
 SG_ PH_defekt : 56|1@1+ (1.0,0.0) [0.0|1] ""  Vector__XXX
 SG_ PH_gestoert : 57|1@1+ (1.0,0.0) [0.0|1] ""  Vector__XXX
 SG_ PH_Systemzustand : 58|3@1+ (1.0,0.0) [0.0|7] ""  Vector__XXX
 SG_ PH_Display_Kundenwunsch : 61|2@1+ (1.0,0.0) [0.0|3] ""  Vector__XXX

BO_ 1122 PSD_04: 8 Gateway_Max
 SG_ PSD_Segment_ID : 0|6@1+ (1,0) [2|63] ""  Motor_konv
 SG_ PSD_Vorgaenger_Segment_ID : 6|6@1+ (1,0) [2|63] ""  Motor_konv
 SG_ PSD_Segmentlaenge : 12|7@1+ (2,0) [0|254] "Unit_Meter"  Motor_konv
 SG_ PSD_Strassenkategorie : 19|3@1+ (1.0,0.0) [0.0|7] ""  Motor_konv
 SG_ PSD_Endkruemmung : 22|8@1+ (1,0) [0|254] "Unit_None"  Motor_konv
 SG_ PSD_Endkruemmung_Vorz : 30|1@1+ (1.0,0.0) [0.0|1] ""  Motor_konv
 SG_ PSD_Idenditaets_ID : 31|6@1+ (1,0) [2|63] ""  Motor_konv
 SG_ PSD_ADAS_Qualitaet : 37|1@1+ (1.0,0.0) [0.0|1] ""  Motor_konv
 SG_ PSD_wahrscheinlichster_Pfad : 38|1@1+ (1.0,0.0) [0.0|1] ""  Motor_konv
 SG_ PSD_Geradester_Pfad : 39|1@1+ (1.0,0.0) [0.0|1] ""  Motor_konv
 SG_ PSD_Fahrspuren_Anzahl : 40|3@1+ (1.0,0.0) [0.0|7] ""  Motor_konv
 SG_ PSD_Bebauung : 43|1@1+ (1.0,0.0) [0.0|1] ""  Motor_konv
 SG_ PSD_Segment_Komplett : 44|1@1+ (1.0,0.0) [0.0|1] ""  Motor_konv
 SG_ PSD_Rampe : 45|2@1+ (1.0,0.0) [0.0|3] ""  Motor_konv
 SG_ PSD_Anfangskruemmung : 47|8@1+ (1,0) [0|254] ""  Motor_konv
 SG_ PSD_Anfangskruemmung_Vorz : 55|1@1+ (1.0,0.0) [0.0|1] ""  Motor_konv
 SG_ PSD_Abzweigerichtung : 56|1@1+ (1.0,0.0) [0.0|1] ""  Motor_konv
 SG_ PSD_Abzweigewinkel : 57|7@1+ (1.417323,0) [0.000000|180.000021] ""  Motor_konv

BO_ 1123 PSD_05: 8 Gateway_Max
 SG_ PSD_Pos_Segment_ID : 0|6@1+ (1,0) [2|63] ""  Motor_konv
 SG_ PSD_Pos_Segmentlaenge : 6|7@1+ (2,0) [0|254] "Unit_Meter"  Motor_konv
 SG_ PSD_Pos_Inhibitzeit : 13|5@1+ (10,0) [0|310] "Unit_MilliSecon"  Motor_konv
 SG_ PSD_Pos_Standort_Eindeutig : 18|1@1+ (1.0,0.0) [0.0|1] ""  Motor_konv
 SG_ PSD_Pos_Fehler_Laengsrichtung : 19|3@1+ (1.0,0.0) [0.0|7] ""  Motor_konv
 SG_ PSD_Pos_Fahrspur : 22|3@1+ (1.0,0.0) [0.0|7] ""  Motor_konv
 SG_ PSD_Attribut_Segment_ID_05 : 25|6@1+ (1,0) [2|63] ""  Motor_konv
 SG_ PSD_Attribut_1_ID : 31|5@1+ (1,0) [1|31] ""  Motor_konv
 SG_ PSD_Attribut_1_Wert : 36|4@1+ (1,0) [0|15] "Unit_None"  Motor_konv
 SG_ PSD_Attribut_1_Offset : 40|7@1+ (2,0) [0|254] "Unit_Meter"  Motor_konv
 SG_ PSD_Attribut_2_ID : 47|5@1+ (1,0) [1|31] ""  Motor_konv
 SG_ PSD_Attribut_2_Wert : 52|4@1+ (1,0) [0|15] "Unit_None"  Motor_konv
 SG_ PSD_Attribut_2_Offset : 56|7@1+ (2,0) [0|254] "Unit_Meter"  Motor_konv
 SG_ PSD_Attribute_Komplett_05 : 63|1@1+ (1.0,0.0) [0.0|1] ""  Motor_konv

BO_ 1124 PSD_06: 8 Gateway_Max
 SG_ PSD_06_Mux M  : 0|3@1+ (1.0,0.0) [0.0|7] ""  Motor_konv
 SG_ PSD_Sys_Segment_ID m0  : 3|6@1+ (1,0) [2|63] ""  Motor_konv
 SG_ PSD_Attribut_Segment_ID m1  : 3|6@1+ (1,0) [2|63] ""  Motor_konv
 SG_ PSD_Ges_Segment_ID m2  : 3|6@1+ (1,0) [2|63] ""  Motor_konv
 SG_ PSD_Baum_Laenge_VZ m3  : 3|1@1+ (1.0,0.0) [0.0|1] ""  Motor_konv
 SG_ PSD_Steigung_1_Segment_ID m4  : 3|6@1+ (1,0) [2|63] ""  Motor_konv
 SG_ PSD_Baum_Laenge m3  : 4|25@1+ (0.00001,0) [0.00000|180.00000] "Unit_DegreOfArc"  Motor_konv
 SG_ PSD_Sys_Laendercode m0  : 9|8@1+ (1,0) [0|255] "Unit_None"  Motor_konv
 SG_ PSD_Attribut_3_ID m1  : 9|5@1+ (1,0) [1|31] ""  Motor_konv
 SG_ PSD_Ges_Offset m2  : 9|7@1+ (2,0) [0|254] "Unit_Meter"  Motor_konv
 SG_ PSD_Steigung_1_A_Steigung m4  : 9|7@1+ (0.12,0) [0.00|15.00] "Unit_PerCent"  Motor_konv
 SG_ PSD_Attribut_3_Offset m1  : 14|7@1+ (2,0) [0|254] "Unit_Meter"  Motor_konv
 SG_ PSD_Ges_Geschwindigkeit m2  : 16|5@1+ (1.0,0.0) [0.0|31] ""  Motor_konv
 SG_ PSD_Steigung_1_A_Vorz m4  : 16|1@1+ (1.0,0.0) [0.0|1] ""  Motor_konv
 SG_ PSD_Sys_Geschwindigkeit_Einheit m0  : 17|1@1+ (1.0,0.0) [0.0|1] ""  Motor_konv
 SG_ PSD_Steigung_1_A_Offset m4  : 17|7@1+ (2,0) [0|254] "Unit_Meter"  Motor_konv
 SG_ PSD_Sys_Verkehrsrichtung m0  : 18|1@1+ (1.0,0.0) [0.0|1] ""  Motor_konv
 SG_ PSD_Sys_Geometrieguete m0  : 19|2@1+ (1.0,0.0) [0.0|3] ""  Motor_konv
 SG_ PSD_Sys_Mapmatchingguete m0  : 21|2@1+ (1.0,0.0) [0.0|3] ""  Motor_konv
 SG_ PSD_Attribut_3_Wert m1  : 21|4@1+ (1,0) [0|15] "Unit_None"  Motor_konv
 SG_ PSD_Ges_Typ m2  : 21|2@1+ (1.0,0.0) [0.0|3] ""  Motor_konv
 SG_ PSD_Sys_Alter_Karte m0  : 23|3@1+ (1.0,0.0) [0.0|7] ""  Motor_konv
 SG_ PSD_Ges_Spur_Geschw_Begrenzung m2  : 23|6@1+ (1.0,0.0) [0.0|63] ""  Motor_konv
 SG_ PSD_Steigung_1_B_Steigung m4  : 24|7@1+ (0.12,0) [0.00|15.00] "Unit_PerCent"  Motor_konv
 SG_ PSD_Attribut_4_ID m1  : 25|5@1+ (1,0) [1|31] ""  Motor_konv
 SG_ PSD_Sys_Zielfuehrung m0  : 26|1@1+ (1.0,0.0) [0.0|1] ""  Motor_konv
 SG_ PSD_Sys_US_State m0  : 27|6@1+ (1.0,0.0) [0.0|63] ""  Motor_konv
 SG_ PSD_Ges_Geschwindigkeit_Gespann m2  : 29|2@1+ (1.0,0.0) [0.0|3] ""  Motor_konv
 SG_ PSD_Baum_Breite_VZ m3  : 29|1@1+ (1.0,0.0) [0.0|1] ""  Motor_konv
 SG_ PSD_Attribut_4_Wert m1  : 30|4@1+ (1,0) [0|15] ""  Motor_konv
 SG_ PSD_Baum_Breite m3  : 30|24@1+ (0.00001,0) [0.00000|90.00000] "Unit_DegreOfArc"  Motor_konv
 SG_ PSD_Ges_Geschwindigkeit_Witter m2  : 31|2@1+ (1.0,0.0) [0.0|3] ""  Motor_konv
 SG_ PSD_Steigung_1_B_Vorz m4  : 31|1@1+ (1.0,0.0) [0.0|1] ""  Motor_konv
 SG_ PSD_Steigung_1_B_Offset m4  : 32|7@1+ (2,0) [0|254] "Unit_Meter"  Motor_konv
 SG_ PSD_Sys_Quali_Geometrien m0  : 33|3@1+ (1,0) [0|7] "Unit_None"  Motor_konv
 SG_ PSD_Ges_Geschwindigkeit_Tag_Anf m2  : 33|3@1+ (1.0,0.0) [0.0|7] ""  Motor_konv
 SG_ PSD_Attribut_4_Offset m1  : 34|7@1+ (2,0) [0|254] "Unit_Meter"  Motor_konv
 SG_ PSD_Sys_Quali_Ortsinfo m0  : 36|2@1+ (1,0) [0|3] "Unit_None"  Motor_konv
 SG_ PSD_Ges_Geschwindigkeit_Tag_Ende m2  : 36|3@1+ (1.0,0.0) [0.0|7] ""  Motor_konv
 SG_ PSD_Sys_Quali_verfuegbar m0  : 38|1@1+ (1.0,0.0) [0.0|1] ""  Motor_konv
 SG_ PSD_Sys_Zielfuehrung_geaendert m0  : 39|1@1+ (1.0,0.0) [0.0|1] ""  Motor_konv
 SG_ PSD_Ges_Geschwindigkeit_Std_Anf m2  : 39|5@1+ (1,0) [0|24] "Unit_Hours"  Motor_konv
 SG_ PSD_Steigung_1_Attribute_kompl m4  : 39|1@1+ (1.0,0.0) [0.0|1] ""  Motor_konv
 SG_ PSD_Sys_Geometrieguete_erweitert m0  : 40|8@1+ (1.0,0.0) [0.0|255] ""  Motor_konv
 SG_ PSD_Steigung_2_Segment_ID m4  : 40|6@1+ (1,0) [2|63] ""  Motor_konv
 SG_ PSD_Attribut_5_ID m1  : 41|5@1+ (1,0) [1|31] ""  Motor_konv
 SG_ PSD_Ges_Geschwindigkeit_Std_Ende m2  : 44|5@1+ (1,0) [0|24] "Unit_Hours"  Motor_konv
 SG_ PSD_Attribut_5_Offset m1  : 46|7@1+ (2,0) [0|254] "Unit_Meter"  Motor_konv
 SG_ PSD_Steigung_2_Steigung m4  : 46|7@1+ (0.12,0) [0.00|15.00] "Unit_PerCent"  Motor_konv
 SG_ PSD_Sys_Quali_sonstige_Attribute m0  : 48|3@1+ (1,0) [0|7] "Unit_None"  Motor_konv
 SG_ PSD_Ges_Ueberholverbot m2  : 49|2@1+ (1.0,0.0) [0.0|3] ""  Motor_konv
 SG_ PSD_Sys_Quali_Steigungen m0  : 51|3@1+ (1,0) [0|7] ""  Motor_konv
 SG_ PSD_Ges_Wechselverkehrszeichen m2  : 51|3@1+ (1.0,0.0) [0.0|7] ""  Motor_konv
 SG_ PSD_Attribut_5_Wert m1  : 53|4@1+ (1,0) [0|15] ""  Motor_konv
 SG_ PSD_Steigung_2_Vorz m4  : 53|1@1+ (1.0,0.0) [0.0|1] ""  Motor_konv
 SG_ PSD_Sys_Quali_Strassenkennz m0  : 54|3@1+ (1,0) [0|7] "Unit_None"  Motor_konv
 SG_ PSD_Wechselverkehrszeichen_Typ m2  : 54|2@1+ (1.0,0.0) [0.0|3] ""  Motor_konv
 SG_ PSD_Baum_Ausrichtung m3  : 54|10@1+ (0.3515625,0) [0E-7|359.6484375] "Unit_DegreOfArc"  Motor_konv
 SG_ PSD_Steigung_2_Offset m4  : 54|7@1+ (2,0) [0|254] "Unit_Meter"  Motor_konv
 SG_ PSD_Ges_Gesetzlich_Kategorie m2  : 56|3@1+ (1.0,0.0) [0.0|7] ""  Motor_konv
 SG_ PSD_Sys_Quali_Tempolimits m0  : 57|3@1+ (1,0) [0|7] "Unit_None"  Motor_konv
 SG_ PSD_Attribute_Komplett_06 m1  : 57|1@1+ (1.0,0.0) [0.0|1] ""  Motor_konv
 SG_ PSD_Ges_Gesetzlich_Zusatz m2  : 59|2@1+ (1.0,0.0) [0.0|3] ""  Motor_konv
 SG_ PSD_Sys_Quali_Vorfahrtsregelung m0  : 60|3@1+ (1,0) [0|7] "Unit_None"  Motor_konv
 SG_ PSD_Ges_Verkehrszeichen_Quelle m2  : 61|2@1+ (1.0,0.0) [0.0|3] ""  Motor_konv
 SG_ PSD_Steigung_2_Attribute_kompl m4  : 61|1@1+ (1.0,0.0) [0.0|1] ""  Motor_konv
 SG_ PSD_Ges_Attribute_Komplett m2  : 63|1@1+ (1.0,0.0) [0.0|1] ""  Motor_konv

BO_ 1125 PSD_LR_01: 8 Gateway_Max
 SG_ PSD_LR_Profil_Nummer : 0|2@1+ (1,0) [0|3] ""  Motor_konv
 SG_ PSD_LR_01_MUX M  : 2|2@1+ (1.0,0.0) [0.0|3] ""  Motor_konv
 SG_ PSD_LR_Profil_Laenge m0  : 4|14@1+ (0.25,0) [0.00|4095.75] "Unit_KiloMeter"  Motor_konv
 SG_ PSD_LR_Koeffizientensatz_Nr m1  : 4|6@1+ (1,0) [0|63] ""  Motor_konv
 SG_ PSD_LR_Attribut_1_Offset m2  : 4|12@1+ (0.0244140625,0) [0E-10|99.9755859375] "Unit_PerCent"  Motor_konv
 SG_ PSD_LR_Steigung_1_Offset m3  : 4|12@1+ (0.0244140625,0) [0E-10|99.9755859375] "Unit_PerCent"  Motor_konv
 SG_ PSD_LR_Koeff_1_Amp m1  : 10|9@1+ (0.01956947162,0) [0E-11|9.99999999782] "Unit_PerCent"  Vector__XXX
 SG_ PSD_LR_Attribut_1_Wert m2  : 16|8@1+ (1.0,0.0) [0.0|255] ""  Motor_konv
 SG_ PSD_LR_Steigung_1_Vorz m3  : 16|1@1+ (1.0,0.0) [0.0|1] ""  Motor_konv
 SG_ PSD_LR_Steigung_1_Wert m3  : 17|7@1+ (0.12,0) [0.00|15.24] "Unit_PerCent"  Motor_konv
 SG_ PSD_LR_Fahrzeug_Pos m0  : 18|14@1+ (0.006103888,0) [0E-9|99.999997104] "Unit_PerCent"  Motor_konv
 SG_ PSD_LR_Koeff_1_Phase m1  : 19|9@1+ (0.0122958616,0) [0E-10|6.2831852776] "Unit_DegreOfArc"  Vector__XXX
 SG_ PSD_LR_Attribut_2_Offset m2  : 24|12@1+ (0.0244140625,0) [0E-10|99.9755859375] "Unit_PerCent"  Motor_konv
 SG_ PSD_LR_Steigung_2_Offset m3  : 24|12@1+ (0.0244140625,0) [0E-10|99.9755859375] "Unit_PerCent"  Motor_konv
 SG_ PSD_LR_Koeff_2_Amp m1  : 28|9@1+ (0.01956947162,0) [0E-11|9.99999999782] "Unit_PerCent"  Vector__XXX
 SG_ PSD_LR_Globale_Steigung_Vorz m0  : 32|1@1+ (1.0,0.0) [0.0|1] ""  Motor_konv
 SG_ PSD_LR_Globale_Steigung m0  : 33|19@1+ (0.00002861028406197,0) [0E-17|14.99999999999806539] "Unit_PerCent"  Motor_konv
 SG_ PSD_LR_Attribut_2_Wert m2  : 36|8@1+ (1.0,0.0) [0.0|255] ""  Motor_konv
 SG_ PSD_LR_Steigung_2_Vorz m3  : 36|1@1+ (1.0,0.0) [0.0|1] ""  Motor_konv
 SG_ PSD_LR_Koeff_2_Phase m1  : 37|9@1+ (0.0122958616,0) [0E-10|6.2831852776] "Unit_DegreOfArc"  Vector__XXX
 SG_ PSD_LR_Steigung_2_Wert m3  : 37|7@1+ (0.12,0) [0.00|15.24] "Unit_PerCent"  Motor_konv
 SG_ PSD_LR_Attribut_3_Offset m2  : 44|12@1+ (0.0244140625,0) [0E-10|99.9755859375] "Unit_PerCent"  Motor_konv
 SG_ PSD_LR_Steigung_3_Offset m3  : 44|12@1+ (0.0244140625,0) [0E-10|99.9755859375] "Unit_PerCent"  Motor_konv
 SG_ PSD_LR_Koeff_3_Amp m1  : 46|9@1+ (0.01956947162,0) [0E-11|9.99999999782] "Unit_PerCent"  Vector__XXX
 SG_ PSD_LR_Max_Koeff_Amp m0  : 52|11@1+ (2,0) [0|4094] "Unit_Meter"  Motor_konv
 SG_ PSD_LR_Koeff_3_Phase m1  : 55|9@1+ (0.0122958616,0) [0E-10|6.2831852776] "Unit_DegreOfArc"  Vector__XXX
 SG_ PSD_LR_Attribut_3_Wert m2  : 56|8@1+ (1.0,0.0) [0.0|255] ""  Motor_konv
 SG_ PSD_LR_Steigung_3_Vorz m3  : 56|1@1+ (1.0,0.0) [0.0|1] ""  Motor_konv
 SG_ PSD_LR_Steigung_3_Wert m3  : 57|7@1+ (0.12,0) [0.00|15.24] "Unit_PerCent"  Motor_konv
 SG_ PSD_LR_Reset m0  : 63|1@1+ (1.0,0.0) [0.0|1] ""  Motor_konv

CM_ BO_ 339 "CAN-Botschaft";
CM_ BO_ 1630 "Tankgeberwerte für OBD-relevante Plausibilisierung im Motor-SG";
CM_ BO_ 2549940736 "VDC funktionaler Request auf CANHS";
CM_ BO_ 2621506048 "VDC funktionaler Request auf CANFD";
CM_ BO_ 2549903629 "DK2F Flash Diagnosezugriff";
CM_ BO_ 2550034701 "DK2F Flash Diagnosezugriff";
CM_ BO_ 2549903684 "DK2F Flash Diagnosezugriff";
CM_ BO_ 2550034756 "DK2F Flash Diagnosezugriff";
CM_ BO_ 1175 "neue Struktur ab MQB ohne KD-Fehler";

CM_ SG_ 339 MO_ErwGrenzen_Anf "temporäre Anforderung erweiterter Leistungsgrenzen
0 = normaler Betrieb angefordert
1 = erweiterte Leistungsgrenzen angefordert
BMS und EMS liefern ggf. erweiterte Leistungsgrenzen, um VKM-Start auch unter schwierigen Bedingungen gewährleisten zu könne";
CM_ SG_ 339 MO_Fehler_Notentladung_Anf "Aufforderung zur schnellstmöglichen Entladeung des HV-Zwischenkreises aufgrund Crash-Erkennung / Abriss Pilotlinie";
CM_ SG_ 339 MO_HVEM_Eskalation "Eskalationsbit, mit diesem zusammen darf MO_HVEM_MaxLeistung < der minimal angeforderten Leistung sein und ist durch das HVEM durch Ergreifung aller Eskalationsmaßnahmen umzusetzen (Bei neg. Ladebilanz z.B. im Leerlauf nötig, um die HVBatt vor Entladung e";
CM_ SG_ 339 MO_HVEM_MaxLeistung "Maximal zulässige Leistung, die das HVEM einzustellen hat. 
Ohne Eskalationsbit ist diese Anforderung >= der Minimal benötigten Leistung des HVEM

Hinweis: Ehemaliger Fehlerwert 0x1FF wird senderseitig nicht unterstützt. Diesen Wert aus Kompatibilitäts";
CM_ SG_ 339 MO_HVK_AntriebFehlerstatus "aktueller Fehlerstatus des Antriebs
0: Komponente IO (keine HVK relevanter Fehler)
1 - 5: reserve
6: Keine Komponentenfunktion (Aus)
7: Init";
CM_ SG_ 339 MO_HVK_AntriebZustand "Aktueller Zustand des Antriebs:
0 : Antrieb_AUS               
1 : Antrieb_Startphase        
2 : E-Fahren                  
3 : Hybrid-Fahren             
4 : reserve                   
5 : reserve                   
6 : Keine_Komponentenfunktion ";
CM_ SG_ 339 MO_HVK_EmFehlerstatus "aktueller Fehlerstatus des elektrischen Antriebes (E-Maschine und PWR)

0: Komponente IO (keine HVK relevanter Fehler)
1: Eingeschränkter Betrieb wg. Teilbetrieb
2: reserve
3: Eingeschr_KompFkt_Interlock
4 - 5: reserve
6: Keine Komponentenfunktion ";
CM_ SG_ 339 MO_HVK_EmIstzustand "Aktueller Istzustand der Elm_State
0 : HvOff              
1 : HvStbyReq          
2 : HvStbyOk         
3 : HvBattOnReq        
4 : HvBattOnOk       
10 : HvOnIdle          
18 : HvOnDrvReq        
19 : HvOnDrvOk       
20 : HvOnDrvRdy          ";
CM_ SG_ 339 MO_MVK_AntriebFehlerstatus "aktueller Fehlerstatus des Antriebs
0: Komponente IO (keine MVK relevanter Fehler)
1 - 5: reserve
6: Keine Komponentenfunktion (Aus)
7: Init";
CM_ SG_ 339 MO_MVK_AntriebZustand "Aktueller Zustand des Antriebs:
0 : Antrieb_AUS               
1 : Antrieb_Startphase        
2 : FreilaufMotorAus                  
3 : reserve             
4 : reserve                   
5 : reserve                   
6 : Keine_Komponentenfunktio";
CM_ SG_ 339 MO_MVK_Bordnetz_Anf "Explizite Anforderung des Motors zur Aktivierung bzw. Aufrechterhaltung des Mittelvolt-Bordnetzes für die Ausführung von Motorfunktionen";
CM_ SG_ 339 MO_MVK_EmFehlerstatus "aktueller Fehlerstatus der elektrischen Maschine (RSG)

0: Komponente IO (keine MVK relevanter Fehler)
1: Eingeschränkter Betrieb wg. Teilbetrieb
2: reserve
3 - 5: reserve
6: Keine Komponentenfunktion (Aus)
7: Init";
CM_ SG_ 339 MO_MVK_EmIstzustand "Aktueller Istzustand der Elm_State
0 : MvOff              
1 : MvStbyReq          
2 : MvStbyOk         
3 : MvBattOnReq        
4 : MvBattOnOk       
10 : MvOnIdle          
18 : MvOnDrvReq        
19 : MvOnDrvOk       
20 : MvOnDrv           
";
CM_ SG_ 339 MSG_HYB_30_BZ "BZ für die Botschaft MSG_HYB_30";
CM_ SG_ 339 MSG_HYB_30_CRC "CRC für die Botschaft MSG_HYB_30";

CM_ SG_ 931 MVEM_DC_SollLeistung_MV "Soll-Leistung des DC/DC-Wandlers Höherspannungsseitig (48V-seitig).

Hochsetzen - negativ";
CM_ SG_ 931 MVEM_DC_SollSpannung_MV "Soll-Ausgangspannung des DC/DC-Wandlers MV-Spannungssseitig (48V-seitig).";
CM_ SG_ 931 MVEM_EMG_MaxGenSpannung "max. Spannung des 48V-RSG im generatorischen Betrieb.";
CM_ SG_ 931 MVEM_EMG_MaxGenStrom "Maximaler Strom des RSGs im spannungsgeregeltem Betrieb. ";
CM_ SG_ 931 MVEM_IstStrom_MVVerbraucher "Iststrom-Aufnahme der 48V-Verbraucher (inkl 48V-DC/DC-Wandler) im 48V-Netz

Verbrauch - positiv
Rückspeisung - negativ";

CM_ SG_ 2589283456 MVEM_Kaltstart_StuetzLeistung "Maximal verfügbare Stützleistung für den folgenden Motorkaltstart (48V).";
CM_ SG_ 2589283456 MVEM_MO_USoll_Notbetrieb "Im eingeschränkten Betrieb des 48V Systems und Fehlerfälle der 48V Batterie.";
CM_ SG_ 2589283456 MVEM_Umax_Rueckspeisung "Systeme, die rückspeisefähig sind, müssen vor Erreichen der oberen Spannungsgrenze ihren Leistungsbedarf dynamisch abregeln.";
CM_ SG_ 2589283456 MVEM_Umin_Funktionsgruppe_A "Systeme der Funktionsgruppe A müssen bei Unterschreitung der Spannungsgrenze ihren Leistungsbedarf dynamisch abregeln.";
CM_ SG_ 2589283456 MVEM_Umin_Funktionsgruppe_B "Systeme der Funktionsgruppe B müssen bei Unterschreitung der Spannungsgrenze ihren Leistungsbedarf dynamisch abregeln.";
CM_ SG_ 2589283456 MVEM_Umin_Funktionsgruppe_C "Systeme der Funktionsgruppe C müssen bei Unterschreitung der Spannungsgrenze ihren Leistungsbedarf dynamisch abregeln.";

CM_ SG_ 2463978719 MVEM_03_BZ "4bit Botschaftszähler, wird mit jeder Sendebotschaft inkrementiert";
CM_ SG_ 2463978719 MVEM_03_CRC "Für MLB:
Berechnung siehe Lastenheft 'Kommunikationsabsicherung für FlexRay und CAN'
Ab MQB und MLBevo:
Berechnung siehe Lastenheft 'End-to-End Kommunikationsabsicherung'

Endwerte siehe Begleitdokument 'S-PDU Kennungsfolgen'";
CM_ SG_ 2463978719 MVEM_Eskalation_Energieversorgun "48V-Komponenten dürfen keine Energie aus dem BN48 aufnehmen.
Ausnahme: Sicherstellung Energieversorgung / sicherheitsrelevanter Funktionen";
CM_ SG_ 2463978719 MVEM_IstLeistung_MVVerbraucher "Leistungsaufnahme bzw. -abgabe der 48V-Verbraucher (inkl 48V-DC/DC-Wandler) im 48V-Netz.

Verbrauch - positiv
Rückspeisung - negativ";
CM_ SG_ 2463978719 MVEM_MO_anbietLeist_MVVerbrauch "Max. anbietbare Leistungsaufnahme bei Zuschaltung aller verfügbaren 48V-Verbraucher (inkl 48V-DC/DC-Wandler) im 48V-Netz";
CM_ SG_ 2463978719 MVEM_MO_MinLeistung_MVVerbrauch "Min. erforderliche Leistung der 48V-Verbraucher (inkl 48V-DC/DC-Wandler) im 48V-Netz für FuSi relevante Verbraucher.";
CM_ SG_ 2463978719 MVEM_MO_WunschLeist_MVVerbrauch "Erforderliche Leistung der 48V-Verbraucher (inkl 48V-DC/DC-Wandler) im 48V-Netz inkl. Komfortverbraucher";

CM_ SG_ 1284 MV_Bordnetz_aktiv "Signalisiert ein aktives MV-Bordnetz. MV-Schütze geschlossen.";
CM_ SG_ 1284 MV_Bordnetz_belastbar "Signalisierung vom MVEM das das 48V Bordnetz vollständig belastbar ist  >5 Watt";
CM_ SG_ 1284 MV_Bordnetz_Fehler "Status ob im  MV-Netz ein Fehler detektiert wurde.";
CM_ SG_ 1284 MVK_01_BZ "4bit Botschaftszähler, wird mit jeder Sendebotschaft inkrementiert";
CM_ SG_ 1284 MVK_01_CRC "Für MLB:
Berechnung siehe Lastenheft 'Kommunikationsabsicherung für FlexRay und CAN'
Ab MQB und MLBevo:
Berechnung siehe Lastenheft 'End-to-End Kommunikationsabsicherung'

Endwerte siehe Begleitdokument 'S-PDU Kennungsfolgen'";
CM_ SG_ 1284 MVK_BMS_Sollmodus "Angeforderter Sollmodus der MV-Batterie:
0 : MV_Off                                
1 : MV_On (HS geschlossen)                
2 : nicht belegbar                        
3 : nicht belegbar                        
4 : nicht belegbar 
5 : nicht belegb";
CM_ SG_ 1284 MVK_BOOST_Sollmodus "Sollmodus eBooster auf 48V
0 : keine Freigabe
1 : Freigabe
2 : nicht belegbar
3 : nicht belegbar
4 : nicht belegbar
5 : nicht belegbar
6 : nicht belegbar
7 : Init   (CAN-Initialisierung)   

Info: 'nicht belegbar' d.h. Sollmodus nicht relevant f";
CM_ SG_ 1284 MVK_DCDC_Sollmodus "angeforderte Soll-Betriebsart des 48V DC/DC-Wandlers: 
0: Standby; Kommunikation aktiv
1: MvOn (48V-Netz ist aktiv)
2: Tiefsetzen (48V --> BN 14,4V)
3: Hochsetzen (BN 14,4V --> 48V)
4: Startunterstuetzung_48V (Stützung des 48V-BN im Startvorgang)
5:";
CM_ SG_ 1284 MVK_DCDC_Sollmodus_02 "Angeforderte Soll-Betriebsart des 48V DC/DC-Wandlers: 
0: Standby; Kommunikation aktiv
1: MvOn (48V-Netz ist aktiv)
2: Tiefsetzen (48V --> BN12)
3: Hochsetzen (BN12 --> 48V)
4: Startunterstuetzung_48V (Stützung des 48V-BN im Startvorgang)
5: nicht v";
CM_ SG_ 1284 MVK_eABC_Sollmodus "Sollmodus eABC auf 48V
0 : keine Freigabe
1 : Freigabe
2 : nicht belegbar
3 : nicht belegbar
4 : nicht belegbar
5 : nicht belegbar
6 : nicht belegbar
7 : Init   (CAN-Initialisierung)   

Info: 'nicht belegbar' d.h. Sollmodus nicht relevant für M";
CM_ SG_ 1284 MVK_eAWS_Sollmodus "Sollmodus eAWS auf 48V
0 : keine Freigabe
1 : Freigabe
2 : nicht belegbar
3 : nicht belegbar
4 : nicht belegbar
5 : nicht belegbar
6 : nicht belegbar
7 : Init   (CAN-Initialisierung)   

Info: 'nicht belegbar' d.h. Sollmodus nicht relevant für M";
CM_ SG_ 1284 MVK_Istmodus_Anf "MVK-Anforderung an alle 48V-Komponenten deren Istmodus im schnellen Zyklus (Inhibitzeit) zu senden.";
CM_ SG_ 1284 MVK_MO_EmSollzustand "Anforderung vom MVK Sollzustand der Elm_State
0 = MvOff              
1 = MvStbyReq          
2 = MvStbyWait         
3 = MvBattOnReq        
4 = MvBattOnWait       
10 = MvOnIdle          
18 = MvOnDrvReq        
19 = MvOnDrvWait       
20 = MvO";
CM_ SG_ 1284 MVK_MV_Batteriewarnung "Kundenwarnung aufgrund eines Batteriefehlers";
CM_ SG_ 1284 MVK_MV_Netz_Warnungen "Anforderung Warnung/Fehler MV-System im Kombi
0: Keine Warnung/Init
1:Anforderung_Anzeige_Warnung_MV-Netz (gelbes Symbol)
2:Anforderung_Anzeige_Fehler_MV-Netz (rotes Symbol)
3:Anforderung_Anzeige_Warnung_Kein_Wiederstart_möglich";
CM_ SG_ 1284 MVK_MVPTC_Sollmodus "Sollmodus MV-PTC
0 : keine Freigabe
1 : Freigabe
2 : nicht belegbar
3 : nicht belegbar
4 : nicht belegbar
5 : nicht belegbar
6 : nicht belegbar
7 : Init   (CAN-Initialisierung)   

Info: 'nicht belegbar' d.h. Sollmodus nicht relevant für MVK";

CM_ SG_ 2600468496 NM_Gateway_CAB_V14 "CAB = Clusteraktivbits (V14)

Cluster CAB_01_Antrieb
-Innenraumklimatisierung starten
-Ladevorbedingung, Beginn des Ladens, Ende
-Lademodusänderung, Timer-Laden vs. Sofort Laden

Cluster CAB_02_Hybrid_Laden
-Laden an oder ausschalten
-Ladevorbedi";
CM_ SG_ 2600468496 NM_Gateway_Car_Wakeup "Car Wakeup (Subbusmaster wertet aus)

MQB: 
-Diagnose- oder Komponentenschutzmaster-Funktion weckt den schlafenden Subbus (z.B. MOST)

E3_Volumen:
- Diagnose aktiv -aktive Diagnosekommunikation am OBD-Stecker

MQBw_Baseline:
- Diagnose aktiv -akt";
CM_ SG_ 2600468496 NM_Gateway_CBV_AWB "Das Signal ist zu setzen, wenn das SG aktiv den Bus geweckt hat
0 = Passiver_WakeUp = SG hat das Netzwerk nicht aktiv geweckt
1 = Akitiver_WakeUp = SG hat das Netzwerk aktiv geweckt";
CM_ SG_ 2600468496 NM_Gateway_CBV_CRI "Das Signal ist dauerhaft gesetzt, wenn das NM-Layout Cluster- Anforderungen enthält";
CM_ SG_ 2600468496 NM_Gateway_NM_aktiv_Buskopplung "Nachlauf aufgrund Kopplung zweier Busse. z.B. K-CAN und K2-CAN";
CM_ SG_ 2600468496 NM_Gateway_NM_aktiv_CWU "Nachlauf aufgrund CWU Anforderung";
CM_ SG_ 2600468496 NM_Gateway_NM_aktiv_Diagnose "Diagnose befindet sich nach VW80124 in einer NonDefaultDiagnostic-Session, z.B. ExtendedDiagnostic-Session";
CM_ SG_ 2600468496 NM_Gateway_NM_aktiv_EM "Nachlauf aufgrund Energiemanagement";
CM_ SG_ 2600468496 NM_Gateway_NM_aktiv_FC "Nachlauf aufgrund Funktionscluster Anforderung";
CM_ SG_ 2600468496 NM_Gateway_NM_aktiv_KL15 "Steuergerät hat KL15-EIN erkannt";
CM_ SG_ 2600468496 NM_Gateway_NM_aktiv_Tmin "Mindestaktivzeit ist noch nicht abgelaufen (bei jedem Weckereignis wird die Mindestaktivzeit neu gestartet)";
CM_ SG_ 2600468496 NM_Gateway_NM_State "1 = Zustand Repeat Message (<-- Bus-Sleep Mode)
2 = Zustand Repeat Message (<-- Prepare Bus-Sleep Mode)
4 = Zustand Normal Operation (<-- Repeat Message)
8 = Zustand Normal Operation (<-- Ready Sleep)";
CM_ SG_ 2600468496 NM_Gateway_UDS_CC "Funktionseinschränkung aufgrund aktivem UDS-Communication Control, siehe VW80124";

CM_ SG_ 2600468599 NM_Getriebe_01_CAB_V14 "CAB = Clusteraktivbits (V14)

Cluster - CAB_03_Fahrwerk (ca. 10sec)
N-Haltephase beenden (V-Signal prüfen und Anzeige ansteuern, bevor P eingelegt wird

Cluster - CAB_06_Anzeige (ca. 10sec)
N-Haltephase beenden (V-Signal prüfen und Anzeige ansteuern";
CM_ SG_ 2600468599 NM_Getriebe_01_Car_Wakeup "Car Wakeup (Gateway wertet aus)

MLBevo:
- Ende N-Haltephase";
CM_ SG_ 2600468599 NM_Getriebe_01_CBV_AWB "Das Signal ist zu setzen, wenn das SG aktiv den Bus geweckt hat
0 = Passiver_WakeUp = SG hat das Netzwerk nicht aktiv geweckt
1 = Akitiver_WakeUp = SG hat das Netzwerk aktiv geweckt";
CM_ SG_ 2600468599 NM_Getriebe_01_CBV_CRI "Das Signal ist dauerhaft gesetzt, wenn das NM-Layout Cluster- Anforderungen enthält";
CM_ SG_ 2600468599 NM_Getriebe_01_NM_aktiv_Diagnose "Diagnose befindet sich nach VW80124 in einer NonDefaultDiagnostic-Session, z.B. ExtendedDiagnostic-Session";
CM_ SG_ 2600468599 NM_Getriebe_01_NM_aktiv_KL15 "Steuergerät hat KL15-EIN erkannt";
CM_ SG_ 2600468599 NM_Getriebe_01_NM_aktiv_N_Halte "Anzeige Ende N-Haltephase im Kombi";
CM_ SG_ 2600468599 NM_Getriebe_01_NM_aktiv_PosAnz "Bus gefordert Getriebe Positionsanzeige";
CM_ SG_ 2600468599 NM_Getriebe_01_NM_aktiv_Tmin "Mindestaktivzeit ist noch nicht abgelaufen (bei jedem Weckereignis wird die Mindestaktivzeit neu gestartet)";
CM_ SG_ 2600468599 NM_Getriebe_01_NM_aktiv_v_gr_0 "Bus gefordert bei Geschwindigkeit > 0";
CM_ SG_ 2600468599 NM_Getriebe_01_NM_aktiv_Waehlheb "Bus gefordert bei Wählhebelkommunikation";
CM_ SG_ 2600468599 NM_Getriebe_01_NM_State "1 = Zustand Repeat Message (<-- Bus-Sleep Mode)
2 = Zustand Repeat Message (<-- Prepare Bus-Sleep Mode)
4 = Zustand Normal Operation (<-- Repeat Message)
8 = Zustand Normal Operation (<-- Ready Sleep)";
CM_ SG_ 2600468599 NM_Getriebe_01_UDS_CC "Funktionseinschränkung aufgrund aktivem UDS-Communication Control, siehe VW80124";

CM_ SG_ 2600468598 NM_MO_01_CAB_V14 "CAB = Clusteraktivbits (V14)

Cluster - CAB_02_Hybrid (dauerhaft)
-Hochvoltnetz ist aktiv

CAB_06_Anzeige (<30sec)
- Drucktank-Anzeigen im Kombi notwendig (gestartet, entlüftet, Fehler)";
CM_ SG_ 2600468598 NM_MO_01_Car_Wakeup "Car Wakeup (Gateway wertet aus)
MQB:
- Betanken (Drucktank): gesetzt nur zum busübergreifenden Wachhalten (des BCM für Hybrid)
- Standklimatisierung (Vorhalt)
- Hybrid-Manager deaktiviert alle Hochvolt-Verbraucher für stromloses Öffnen der Batteriesch";
CM_ SG_ 2600468598 NM_MO_01_CBV_AWB "Das Signal ist zu setzen, wenn das SG aktiv den Bus geweckt hat
0 = Passiver_WakeUp = SG hat das Netzwerk nicht aktiv geweckt
1 = Akitiver_WakeUp = SG hat das Netzwerk aktiv geweckt";
CM_ SG_ 2600468598 NM_MO_01_CBV_CRI "Das Signal ist dauerhaft gesetzt, wenn das NM-Layout Cluster- Anforderungen enthält";
CM_ SG_ 2600468598 NM_MO_01_NM_aktiv_Anf_RSG "Kommunikation zum RSG aufgrund Funktion PerfectStartStop oder StallingHelp";
CM_ SG_ 2600468598 NM_MO_01_NM_aktiv_AnzKLuefter "Anzeige Kuehlerluefternachlauf (ca. 6s) durch Signal MO_Anz_Kuehlerluefter";
CM_ SG_ 2600468598 NM_MO_01_NM_aktiv_Betankung "Betankung Drucktank";
CM_ SG_ 2600468598 NM_MO_01_NM_aktiv_Diagnose "Diagnose befindet sich nach VW80124 in einer NonDefaultDiagnostic-Session, z.B. ExtendedDiagnostic-Session";
CM_ SG_ 2600468598 NM_MO_01_NM_aktiv_EKP_Vorlauf "EKP Vorlauf";
CM_ SG_ 2600468598 NM_MO_01_NM_aktiv_Hochvolt "Hochvolt aktiv";
CM_ SG_ 2600468598 NM_MO_01_NM_aktiv_HV_Abschaltung "Hybrid-Manager deaktiviert alle Hochvolt-Verbraucher für stromloses Öffnen der Batterieschütze";
CM_ SG_ 2600468598 NM_MO_01_NM_aktiv_KL15 "Steuergerät hat KL15-EIN erkannt";
CM_ SG_ 2600468598 NM_MO_01_NM_aktiv_NOx_PM_SensDia "Sensordiagnose aktiv";
CM_ SG_ 2600468598 NM_MO_01_NM_aktiv_Oelstandsmes "Das MSG konnte über mehrere DC's (Driving Cycle) hinweg keinen Ölstand ermitteln. 
Aber im globalen Bus-Nachlauf besteht, aufgrund der aktuellen Öltemperatur, diese Möglichkeit.
Daraufhin verlängert das MSG den globalen Bus-Nachlauf und kann somit plaus";
CM_ SG_ 2600468598 NM_MO_01_NM_aktiv_STH_Betrieb "Standheizungsbetrieb";
CM_ SG_ 2600468598 NM_MO_01_NM_aktiv_Tmin "Mindestaktivzeit ist noch nicht abgelaufen (bei jedem Weckereignis wird die Mindestaktivzeit neu gestartet)";
CM_ SG_ 2600468598 NM_MO_01_NM_aktiv_Waehlhebel "Der Waehlhebel MQB setzt wegen Forderung der Funktion 'Verlassenswarnung' NM-High um. Beim E-Fzg. ist der Master des Waehlhebels das Motor-SG.
Daher ist ein neuer Nachlaufgrund des Motors erforderlich, wenn die Wählhebelposition gefordert wird.";
CM_ SG_ 2600468598 NM_MO_01_NM_State "1 = Zustand Repeat Message (<-- Bus-Sleep Mode)
2 = Zustand Repeat Message (<-- Prepare Bus-Sleep Mode)
4 = Zustand Normal Operation (<-- Repeat Message)
8 = Zustand Normal Operation (<-- Ready Sleep)";
CM_ SG_ 2600468598 NM_MO_01_UDS_CC "Funktionseinschränkung aufgrund aktivem UDS-Communication Control, siehe VW80124";

CM_ SG_ 2600469458 NM_Parksperre_aktiv_Feder_n_entl "Dieser Bus wird wachgehalten, weil die Feder noch nicht entladen ist.";
CM_ SG_ 2600469458 NM_Parksperre_CAB_V14 "CAB = Clusteraktivbits (V14)";
CM_ SG_ 2600469458 NM_Parksperre_Car_Wakeup "Car Wakeup (Gateway wertet aus)";
CM_ SG_ 2600469458 NM_Parksperre_CBV_AWB "Das Signal ist zu setzen, wenn das SG aktiv den Bus geweckt hat";
CM_ SG_ 2600469458 NM_Parksperre_CBV_CRI "Das Signal ist dauerhaft gesetzt, wenn das NM-Layout dem neuen NM-Layout für Teilnetzbetrieb entspricht";
CM_ SG_ 2600469458 NM_Parksperre_NM_aktiv_Diagnose "Diagnose befindet sich nach VW80124 in einer NonDefaultDiagnostic-Session, z.B. ExtendedDiagnostic-Session";
CM_ SG_ 2600469458 NM_Parksperre_NM_aktiv_KL15 "Steuergerät hat KL15-EIN erkannt";
CM_ SG_ 2600469458 NM_Parksperre_NM_aktiv_Tmin "Mindestaktivzeit ist noch nicht abgelaufen (bei jedem Weckereignis wird die Mindestaktivzeit neu gestartet)";
CM_ SG_ 2600469458 NM_Parksperre_NM_State "1 = Zustand Repeat Message (<-- Bus-Sleep Mode)
2 = Zustand Repeat Message (<-- Prepare Bus-Sleep Mode)
4 = Zustand Normal Operation (<-- Repeat Message)
8 = Zustand Normal Operation (<-- Ready Sleep)";
CM_ SG_ 2600469458 NM_Parksperre_UDS_CC "Funktionseinschränkung aufgrund aktivem UDS-Communication Control; siehe VW80124";

CM_ SG_ 2600468733 NM_Waehlhebel_CAB_V14 "CAB = Clusteraktivbits (V14)";
CM_ SG_ 2600468733 NM_Waehlhebel_Car_Wakeup "Car Wakeup (Gateway wertet aus)

MLBevo: Fahrerwunsch_P";
CM_ SG_ 2600468733 NM_Waehlhebel_CBV_AWB "Das Signal ist zu setzen, wenn das SG aktiv den Bus geweckt hat
0 = Passiver_WakeUp = SG hat das Netzwerk nicht aktiv geweckt
1 = Akitiver_WakeUp = SG hat das Netzwerk aktiv geweckt";
CM_ SG_ 2600468733 NM_Waehlhebel_CBV_CRI "Das Signal ist dauerhaft gesetzt, wenn das NM-Layout Cluster- Anforderungen enthält";
CM_ SG_ 2600468733 NM_Waehlhebel_NM_aktiv_Diagnose "Diagnose befindet sich nach VW80124 in einer NonDefaultDiagnostic-Session, z.B. ExtendedDiagnostic-Session";
CM_ SG_ 2600468733 NM_Waehlhebel_NM_aktiv_KL15 "Steuergerät hat KL15-EIN erkannt";
CM_ SG_ 2600468733 NM_Waehlhebel_NM_aktiv_Tmin "Mindestaktivzeit ist noch nicht abgelaufen (bei jedem Weckereignis wird die Mindestaktivzeit neu gestartet)";
CM_ SG_ 2600468733 NM_Waehlhebel_NM_State "1 = Zustand Repeat Message (<-- Bus-Sleep Mode)
2 = Zustand Repeat Message (<-- Prepare Bus-Sleep Mode)
4 = Zustand Normal Operation (<-- Repeat Message)
8 = Zustand Normal Operation (<-- Ready Sleep)";
CM_ SG_ 2600468733 NM_Waehlhebel_UDS_CC "Funktionseinschränkung aufgrund aktivem UDS-Communication Control, siehe VW80124";

CM_ SG_ 1630 OBD_TG_F_Status_1 "Fehlerstatus Tankfüllstandsgeber (OBD relevanter Sensor für Tankleckdiagnose)";
CM_ SG_ 1630 OBD_TG_F_Status_2 "Fehlerstatus Tankfüllstandsgeber (OBD relevanter Sensor für Tankleckdiagnose)

0x00 = kein Fehler / Init / nicht verbaut
0x01 = KS-
0x02 = KS+ (B8: nicht bedient)
0x03 = OC (Leitungsunterbrechung) (B8: nicht bedient)
0x04 = OOR+ (out of range high) ";
CM_ SG_ 1630 OBD_TG_F_Status_3 "Fehlerstatus Tankfüllstandsgeber (OBD relevanter Sensor für Tankleckdiagnose)

0x00 = kein Fehler / Init / nicht verbaut
0x01 = KS-
0x02 = KS+ (B8: nicht bedient)
0x03 = OC (Leitungsunterbrechung) (B8: nicht bedient)
0x04 = OOR+ (out of range high) ";
CM_ SG_ 1630 OBD_TG_F_Status_4 "Fehlerstatus Tankfüllstandsgeber (OBD relevanter Sensor für Tankleckdiagnose)

0x00 = kein Fehler / Init / nicht verbaut
0x01 = KS-
0x02 = KS+ (B8: nicht bedient)
0x03 = OC (Leitungsunterbrechung) (B8: nicht bedient)
0x04 = OOR+ (out of range high) ";
CM_ SG_ 1630 OBD_TG_Sens_Rohwert_1 "Rohwert des Tankgebers, nur gefiltert (gleitender Mittelwert), Ausgabe im 500ms-Raster";
CM_ SG_ 1630 OBD_TG_Sens_Rohwert_2 "Rohwert des Tankgebers, nur gefiltert (gleitender Mittelwert), Ausgabe im 500ms-Raster";
CM_ SG_ 1630 OBD_TG_Sens_Rohwert_3 "Rohwert des Tankgebers, nur gefiltert (gleitender Mittelwert), Ausgabe im 500ms-Raster";
CM_ SG_ 1630 OBD_TG_Sens_Rohwert_4 "Rohwert des Tankgebers, nur gefiltert (gleitender Mittelwert), Ausgabe im 500ms-Raster";

CM_ SG_ 2621440636 OBDC_EMotor_01_Req_FD_Data "OnBoard Tester Diagnose Request FD EMotor_01.";

CM_ SG_ 2621571708 OBDC_EMotor_01_Resp_FD_Data "OnBoard Tester Diagnose Response FD EMotor_01.";

CM_ SG_ 2621440696 OBDC_EMotor_02_Req_FD_Data "OnBoard Tester Diagnose Request FD EMotor_02.";

CM_ SG_ 2621571768 OBDC_EMotor_02_Resp_FD_Data "OnBoard Tester Diagnose Response FD EMotor_02.";

CM_ SG_ 2549940736 OBDC_Funktionaler_Req_All_Data "VDC funktionaler Request auf CANHS";

CM_ SG_ 2621506048 OBDC_Funktion_Req_All_FD_Data "OnBoard Tester funktionaler Diagnose Request ALL";

CM_ SG_ 2621440631 OBDC_Getriebe_01_Req_FD_Data "OnBoard Tester Diagnose über ISO TP.";

CM_ SG_ 2621571703 OBDC_Getriebe_01_Resp_FD_Data "OnBoard Tester Diagnose über ISO TP.";

CM_ SG_ 2621702713 OBDC_LCU_SMH_Req_FD_Data "OnBoard Tester Diagnose Request LCU_SMH";

CM_ SG_ 2621833785 OBDC_LCU_SMH_Resp_FD_Data "OnBoard Tester Diagnose Response LCU_SMH";

CM_ SG_ 2621440630 OBDC_MO_01_Req_FD_Data "OnBoard Tester Diagnose Request FD MO_01.";

CM_ SG_ 2621571702 OBDC_MO_01_Resp_FD_Data "OnBoard Tester Diagnose Response FD MO_01.";

CM_ SG_ 2621440645 OBDC_RSG_Req_FD_Data "OnBoard Tester Diagnose Request RSG";

CM_ SG_ 2621571717 OBDC_RSG_Resp_FD_Data "OnBoard Tester Diagnose Response RSG";

CM_ SG_ 2549903629 OBDC_SSN_eBooster_Req_Data "Diagnose Request Flashen EKAT";

CM_ SG_ 2550034701 OBDC_SSN_eBooster_Resp_Data "Diagnose Response Flashen EKAT";

CM_ SG_ 2549903684 OBDC_SSN_EKAT_Req_Data "Diagnose Request Flashen EKAT";

CM_ SG_ 2550034756 OBDC_SSN_EKAT_Resp_Data "Diagnose Response Flashen EKAT";

CM_ SG_ 2549903608 OBDC_SSN_MTFP_Req_Data "Request FID- zu NA- Kommunikation zw. OnboardDiagnoseClient und DK2F Sub-System-Knoten";

CM_ SG_ 2550034680 OBDC_SSN_MTFP_Resp_Data "Response FID- zu NA- Kommunikation zw. OnboardDiagnoseClient und DK2F Sub-System-Knoten";

CM_ SG_ 2621468994 OBDC_SSN_Parksperre_Req_FD_Data "Request FID- zu NA- Kommunikation zw. OnboardDiagnoseClient und DK2F Sub-System";

CM_ SG_ 2621600066 OBDC_SSN_Parksperre_Resp_FD_Data "Response FID- zu NA- Kommunikation zw. OnboardDiagnoseClient und DK2F Sub-System";

CM_ SG_ 2564502513 OBDx_allOBD_Req_Data "Generic Scan Tool funktionaler Diagnose Request ALL OBD";

CM_ SG_ 2564424433 OBDx_Getriebe_01_Req_Data "Generic Scan Tool funktionaler Diagnose Request ALL OBD";

CM_ SG_ 2564485378 OBDx_Getriebe_01_Resp_Data "Generic Scan Tool funktionaler Diagnose Request ALL OBD";

CM_ SG_ 2564429809 OBDx_LCU_SMH_Req_Data "Generic Scan Tool funktionaler Diagnose Request ALL OBD";

CM_ SG_ 2564485399 OBDx_LCU_SMH_Resp_Data "Generic Scan Tool funktionaler Diagnose Request ALL OBD";

CM_ SG_ 2564425457 OBDx_LE1_Req_Data "Generic Scan Tool funktionaler Diagnose Request ALL OBD";

CM_ SG_ 2564485382 OBDx_LE1_Resp_Data "Generic Scan Tool funktionaler Diagnose Request ALL OBD";

CM_ SG_ 2564425713 OBDx_LE2_Req_Data "Generic Scan Tool funktionaler Diagnose Request ALL OBD";

CM_ SG_ 2564485383 OBDx_LE2_Resp_Data "Generic Scan Tool funktionaler Diagnose Request ALL OBD";

CM_ SG_ 2564424177 OBDx_MO_01_Req_Data "Generic Scan Tool funktionaler Diagnose Request für abgasrelevante Steuergeraete";

CM_ SG_ 2564485377 OBDx_MO_01_Resp_Data "Generic Scan Tool funktionaler Diagnose Request für abgasrelevante Steuergeraete";

CM_ SG_ 2564428017 OBDx_RSG_Req_Data "29bit OBD Diagnose";

CM_ SG_ 2564485392 OBDx_RSG_Resp_Data "Generic Scan Tool funktionaler Diagnose Request ALL OBD";

CM_ SG_ 2463978776 HVLE_AnzahlVerwendeterPhasen "Gibt die Anzahl der verwendeten Phasen für das AC Laden an";
CM_ SG_ 2463978776 HVLE_AsymmetrischLadenMoeglich "Information ob das Ladegerät ein asymetrisches Laden bauartbedingt unterstützt";
CM_ SG_ 2463978776 HVLE_Derating_Temperatur "Derating-Status aufgrund von Temperaturbegrenzungen des Ladegeraet";
CM_ SG_ 2463978776 HVLE_Energiemenge_Laden "Energiemenge, die von dem Ladegeraet ueber einen definierten Zeitraum an das Fahrzeug geliefert wurde";
CM_ SG_ 2463978776 HVLE_I_istAC_Netz_L1 "aktueller AC-Iststrom am Eingangskreis Phase 1 des Ladegeraet";
CM_ SG_ 2463978776 HVLE_I_istAC_Netz_L2 "aktueller AC-Iststrom am Eingangskreis Phase 2 des Ladegeraet";
CM_ SG_ 2463978776 HVLE_I_istAC_Netz_L3 "aktueller AC-Iststrom am Eingangskreis Phase 3 des Ladegeraet";
CM_ SG_ 2463978776 HVLE_Ist_Wirkungsgrad "aktueller Wirkungsgrad des Ladegeraet";
CM_ SG_ 2463978776 HVLE_IstSpannung_HV "aktuelle DC-Ausgangsspannung des Ladegeraet";
CM_ SG_ 2463978776 HVLE_Netzfrequenz_EVU "aktuelle AC-Netzfrequenz im Eingangskreis des Ladegeraet";
CM_ SG_ 2463978776 HVLE_Netzmodus "Das Ladegeraet signalisiert hier den aktuellen Netzmodus. (1-phasig, 2-phasig, 3phasig, usw.)";
CM_ SG_ 2463978776 HVLE_OBG_AC_maxSpannung "Bauteiltechnischer Grenzwert der maximalen nominellen Spannung gemessen zwischen Phase und Neutral.";
CM_ SG_ 2463978776 HVLE_OBG_AC_maxStrom "auteiltechnischer Grenzwert des maximalen Stroms pro Phase welches vom Ladegerät unterstützt wird.";
CM_ SG_ 2463978776 HVLE_OBG_ACDC_IstLeistung "Aktuelle Ist-Leistung des Onboardgleichrichters nach der AC-DC-Umwandlung inkl. Verluste des Wirkungsgrades";
CM_ SG_ 2463978776 HVLE_OBG_ACDC_MaxLeistung "Maximale mögliche Leistung des Onboardgleichrichters nach der AC-DC-Umwandlung inkl. Verluste des Wirkungsgrades";
CM_ SG_ 2463978776 HVLE_OBG_DC_IstStrom "aktueller Iststrom des OCC";
CM_ SG_ 2463978776 HVLE_OBG_DC_MaxStrom "maximaler Strom den das Ladegeraet bei der aktuellen Spannungslage und des vorgegebenen AC-Aufnahmenstrom stellen kann";
CM_ SG_ 2463978776 HVLE_OBG_Fehlerstatus "Gibt an, ob bei dem Ladegerät ein Fehler anliegt.";
CM_ SG_ 2463978776 HVLE_OBG_Fehlerstrom "Fehlerstrom der durch einen Isolationsfehler (z.B. schadhafte Isolierung, Berührung) vom Betriebsmittel zum Erdungssystem abfließt. Dies können hier AC- oder DC-Ströme sein.";
CM_ SG_ 2463978776 HVLE_OBG_IstModus "aktueller Funktionszustand des Ladegeraet";
CM_ SG_ 2463978776 HVLE_OBG_Kuehltemperatur "aktuelle Kuehlmitteltemperatur des OBGs";
CM_ SG_ 2463978776 HVLE_OBG_Status_EoHVL "Erkennung einer offenen HV-Leitung (EoHVL), bewertet anhand einer Spannungsgrenze";
CM_ SG_ 2463978776 HVLE_OBG_Status_Spgfreiheit "Status der Spannungsfreiheit für den Onboard Charge Client";
CM_ SG_ 2463978776 HVLE_OBG_Typ_verbaut "Typ des verbauten Onboard-Gleichrichters";
CM_ SG_ 2463978776 HVLE_OBG_Warnzustand "Zeigt an, ob eine Warnung für das Ladegerät aufgetreten ist.";
CM_ SG_ 2463978776 HVLE_PE_Monitor "Messung des PE-Leiters der Infrastruktur bei galvanisch nicht getrennten Onboard Gleichrichtern.";
CM_ SG_ 2463978776 HVLE_U_istAC_Netz_L1 "aktuelle AC-Istspannung am Eingangskreis Phase 1 des Ladegeraet";
CM_ SG_ 2463978776 HVLE_U_istAC_Netz_L2 "aktuelle AC-Istspannung am Eingangskreis Phase 2 des Ladegeraet";
CM_ SG_ 2463978776 HVLE_U_istAC_Netz_L3 "aktuelle AC-Istspannung am Eingangskreis Phase 3 des Ladegeraet";
CM_ SG_ 2463978776 OBG_01_BZ "4bit Botschaftszähler, wird mit jeder Sendebotschaft inkrementiert";
CM_ SG_ 2463978776 OBG_01_CRC "Für MLB:
Berechnung siehe Lastenheft 'Kommunikationsabsicherung für FlexRay und CAN'
Ab MQB und MLBevo:
Berechnung siehe Lastenheft 'End-to-End Kommunikationsabsicherung'

Endwerte siehe Begleitdokument 'S-PDU Kennungsfolgen'";
CM_ SG_ 2463978776 SOK_OBG_01_Signatur "Signatur im Rahmen des SOK.

Geschützte Funktion:	
Geschützte Signale:  	";

CM_ SG_ 2589284143 OBMI_DDrvRngRem "OBM Inducement System: der an das Kombi/MMI übermittelte Wert für die Restreichweite (einheitenlos) der OBM Inducement Fahrerinformation";
CM_ SG_ 2589284143 OBMI_FlgTrig "OBM Inducement System: der an das Kombi/MMI übermittelte Trigger zur Erneuerung der OBM Inducement Fahrerinformation";
CM_ SG_ 2589284143 OBMI_StAct "OBM Inducement System: der an das Kombi/MMI übermittelte Zustand der OBM Inducement Fahrerinformation";
CM_ SG_ 2589284143 OBMI_StDrvRngUnit "OBM Inducement System: die an das Kombi/MMI übermittelte Einheit für die Restreichweite (km oder mi) der OBM Inducement Fahrerinformation";

CM_ SG_ 2589283656 ORU_Status "Verteilung des internen ORU Zustandes";
CM_ SG_ 2589283656 ORU_Warnung "Wenn durch Störungen der Funktion Online Remote Update nicht sichergestellt ist, dass vor Kunde keine Funktionseinschränkungen auftreten, muss der Benutzer des Fahrzeugs entsprechend gewarnt werden.";

CM_ SG_ 518 IPA_TPA_Abbruch "Signalisierung eines durch IPA erkannten Abbruchs mit Angabe des Grundes";
CM_ SG_ 518 IPA_TPA_ausgerichtetes_Parken "signalisiert TPA, ob ausgerichtetes Einparken aktiv ist";
CM_ SG_ 518 IPA_TPA_Fehler "Signalisierung eines durch IPA erkannten Fehlers mit Angabe der Fehlerart";
CM_ SG_ 518 IPA_TPA_Remote "Status hinsichtlich Umschaltung auf fernbedienten Parkvorgang";
CM_ SG_ 518 IPA_TPA_Remote_Anf "Anforderung für bzw. bei fernbedienten Parkvorgang";
CM_ SG_ 518 IPA_TPA_Status "Status der Funktion IPA gegenüber der Funktion TPA";
CM_ SG_ 518 Parken_01_BZ "4bit Botschaftszähler, wird mit jeder Sendebotschaft inkrementiert";
CM_ SG_ 518 Parken_01_CRC "Für MLB:
Berechnung siehe Lastenheft 'Kommunikationsabsicherung für FlexRay und CAN'
Ab MQB und MLBevo:
Berechnung siehe Lastenheft 'End-to-End Kommunikationsabsicherung'

Endwerte siehe Begleitdokument 'S-PDU Kennungsfolgen'";
CM_ SG_ 518 Parken_aktives_System "Das Signal zeigt an, welches der Parksysteme auf dem zFAS gerade aktiv ist.";
CM_ SG_ 518 Parken_Anforderung_HMS "Anforderung der Dienste des HMS durch die Parkplattform";
CM_ SG_ 518 Parken_Anhalteweg_Anf "Zeigt eine Anhalteweg Anforderung an";
CM_ SG_ 518 Parken_beibehalten "Fordert das Parken beim HMS an";
CM_ SG_ 518 Parken_BKD_Anf "Anforderung der Systemtotzeitoptimierung ans VZM";
CM_ SG_ 518 Parken_Bordstein_Winkel "Winkel zwischen Bordstein und Fahrzeug.";
CM_ SG_ 518 Parken_erhoehtes_Moment "Anforderung einer spezifizierten Motormomenten-Rampe seitens IPA/PiloPa für das Überfahren einer Schwelle oder eines Bordsteins.";
CM_ SG_ 518 Parken_Fahrbereitschaft_Anf "Anforderung seitens iPA/pilotiertes Parken, die Fahrbereitschaft aufrecht zu erhalten und das Verlassenskonzept im MSG beim „automatischen Parkvorgang“ zu deaktivieren.";
CM_ SG_ 518 Parken_Fahrstufenwunsch "Fahrstufenwunsch von IPAe/RPAe an das Getriebe";
CM_ SG_ 518 Parken_max_Beschleunigung "Maximale zulässige Beschleunigung der Parkfunktion";
CM_ SG_ 518 Parken_max_Geschwindigkeit "Maximale zulässige Geschwindigkeit der Parkfunktion";
CM_ SG_ 518 Parken_Motorlauf_Anf "Anforderung Motorlauf seitens PiloPa";
CM_ SG_ 518 Parken_Notstopp_Anf "Anforderung Notstopp der Parkplattform";
CM_ SG_ 518 Parken_Prefill_Anf "Anforderung Prefill am VZM";
CM_ SG_ 518 Parken_QFK_AnfStat "Statusinformationen des Anforderers";
CM_ SG_ 518 Parken_QFK_Art1 "Auswahlsignal für Parken_QFK_Signal1";
CM_ SG_ 518 Parken_QFK_Art2 "Auswahlsignal für Parken_QFK_Signal2";
CM_ SG_ 518 Parken_QFK_KruemmSoll "Krümmungsanforderung";
CM_ SG_ 518 Parken_QFK_KruemmSoll_VZ "Vorzeichen für die Krümmungsanforderung";
CM_ SG_ 518 Parken_QFK_Signal1 "Inhalt PLA_QFK_Signal1 wird durch das Signal PLA_QFK_Art1 gesteuert.
Nähere Informationen im LAH Querführungskoordinator.";
CM_ SG_ 518 Parken_QFK_Signal2 "Inhalt Parken_QFK_Signal2 wird durch das Signal Parken_QFK_Art2 gesteuert.
Nähere Informationen im LAH Querführungskoordinator.";
CM_ SG_ 518 Parken_QFK_Spuerb "Spürbarkeitsanforderung. Legt fest, mit welchem Handmoment die angeforderte Krümmung überlenkt werden muss.";
CM_ SG_ 518 Parken_Schleichfahrt_Anf "Anforderungen des Schleichfahrtmodus.";
CM_ SG_ 518 Parken_Soll_Anhalteweg_Anf "Anforderung des Soll Anhalteweges der PPF beim VZM";
CM_ SG_ 518 Parken_Sollbeschleunigung "Anforderung einer Parkenfunktion an den TSK, das Fahrzeug zu beschleunigen.";
CM_ SG_ 518 Parken_Status_IPA_TSK "Statusinformation vom IPA für Handshakemechanismus mit TSK";
CM_ SG_ 518 Parken_Verz_Anf "Zeigt die die angeforderte Verzögerung an";
CM_ SG_ 518 Parken_Verz_Anf_ASIL "Angabe des ASIL Levels der aktuell aktiven Funtkion auf der Parkplattform";
CM_ SG_ 518 Parken_Warnruck_Anf "Signal zur Anforderung Warnruck beim VZM";
CM_ SG_ 518 Parken_Warnruckeln_Anf "Anforderung Warnruckeln beim VZM";

CM_ SG_ 1175 PDC_Tonausgabe_Front "In Abhängigkeit der Systemaktivitäten werden unterschiedliche Tonwarnungen ausgegeben. 
Kombi spielt entsprechende WAV.-Datei über internen Audiomaster ab.

0 = kein Ton
1 = Intervallton 1
2 = Intervallton 2
3 = Intervallton 3
4 = Intervallton 4
5";
CM_ SG_ 1175 PDC_Tonausgabe_Heck "In Abhängigkeit der Systemaktivitäten werden unterschiedliche Tonwarnungen ausgegeben. 
Kombi spielt entsprechende WAV.-Datei über internen Audiomaster ab.

0 = kein Ton
1 = Intervallton 1
2 = Intervallton 2
3 = Intervallton 3
4 = Intervallton 4
5";
CM_ SG_ 1175 PH_Abschaltursache "Abschaltursache bleibt bis zur nächsten Aktivierung bzw. bis KL15 aus gesetzt
Im Fehlerfall (blinkende LED) wird '7' gesendet obwohl das System noch aktiv ist, bei 'geheiltem' Fehler wird sofort wieder der Zustand '0' gesendet";
CM_ SG_ 1175 PH_Anf_Audioabsenkung "Es gibt zwei unterschiedliche Nachlauftimer für dieses Bit:
1. normale Funktion
2. Demotonausgabe";
CM_ SG_ 1175 PH_Anf_Verdeck "Anforderung an ein Verdeck-System, die vom Fahrer angeforderte Öffnung/Schließung zu verhindern";
CM_ SG_ 1175 PH_defekt "Zeigt an das sich die Parkhilfe im Fehlerzustand befindet. Signal bleibt bis zur nächsten 'Gut-Aktivierung' gesetzt.
Spezialfall: Sensordefekt hinten bei Anhängerbetrieb. Anhänger wird abgesteckt Fehler wird gesetzt. Fehlerfall bleibt bis Behebung des De";
CM_ SG_ 1175 PH_Display_Kundenwunsch "Anzeige der bei Aktivierung verwendeten Parameter bzgl. Kundenwunsch Displayanziege. Änderungen werden erst bei erneuter Aktivierung aktualisiert.";
CM_ SG_ 1175 PH_Frequenz_hinten "Uebertragung der aktuell im APS Steuergeraet gespeicherten Werte fuer Tongeber Frequenz hinten
Anzeige der aktuell verwendeten Parameter (nicht zwingend die abgespeicherten - da Werte erst 2s nach der letzten Änderung gespeichert werden!)";
CM_ SG_ 1175 PH_Frequenz_vorn "Uebertragung der aktuell im APS Steuergeraet gespeicherten Werte fuer Tongeber Frequenz vorne
Anzeige der aktuell verwendeten Parameter (nicht zwingend die abgespeicherten - da Werte erst 2s nach der letzten Änderung gespeichert werden!)";
CM_ SG_ 1175 PH_gestoert "Eine Störung ist aufgetreten, der die Parkhilfe in einen 'gestört-Zustand' versetzt, z.B. massiver Fremdultraschall, Vereisung, Schnee.Derzeit nur für Störschall benutzt, da keinerlei andere Erkennung implementiert.";
CM_ SG_ 1175 PH_Lautstaerke_hinten "Uebertragung der aktuell im APS Steuergeraet gespeicherten Werte fuer Tongeber Lautstaerke hinten
Anzeige der aktuell verwendeten Parameter (nicht zwingend die abgespeicherten - da Werte erst 2s nach der letzten Änderung gespeichert werden!)";
CM_ SG_ 1175 PH_Lautstaerke_vorn "Uebertragung der aktuell im APS Steuergeraet gespeicherten Werte fuer Tongeber Lautstaerke vorn.
Anzeige der aktuell verwendeten Parameter (nicht zwingend die abgespeicherten - da Werte erst 2s nach der letzten Änderung gespeichert werden!)";
CM_ SG_ 1175 PH_nachtr_Stopp_Anf "Dieses Signal dient dem Motor als Trigger, dass ein nachträglicher Motorstopp eingeleitet werden kann, wenn es die Bedingungen des StSt Koordinators dies zulassen. ";
CM_ SG_ 1175 PH_Opt_Anz_H_Hindernis "mindestens 1 Segment wird für den hinteren Detekionsbereich dargestellt, also ein Hindernis ist im Detektionsbereich. Funktion nur bei gesicherter Rückmeldung vom ASG gegeben.";
CM_ SG_ 1175 PH_Opt_Anz_V_Hindernis "mindestens 1 Segment wird für den vorderen Detekionsbereich dargestellt, also ein Hindernis ist im Detektionsbereich. Funktion nur bei gesicherter Rückmeldung vom ASG gegeben.";
CM_ SG_ 1175 PH_Opt_Anzeige_H_ein "OPS hinten ist im Display aktiv bzw. Anzeigemodule hinten sind eingeschaltet. Funktion nur bei gesicherter Rückmeldung vom ASG gegeben.";
CM_ SG_ 1175 PH_Opt_Anzeige_V_ein "OPS vorne ist im Display aktiv bzw. Anzeigemodule vorne sind eingeschaltet. Funktion nur bei gesicherter Rückmeldung vom ASG gegeben.";
CM_ SG_ 1175 PH_StartStopp_Info "Stopp-Freigabe und Start-Anforderung an den Start-Stopp-Koordinator";
CM_ SG_ 1175 PH_Stoermeldung "Meldung einer Störung der PDC an das Kombi";
CM_ SG_ 1175 PH_Systemzustand "Aktivierungsursache wird für die Dauer der Aktivierung gemeldet.
Im Fehlerfall bei atkviem System wechselt das Signal auf '7'
(siehe auch 'Abschaltursache')";
CM_ SG_ 1175 PH_Taster "Taster Status (für RVC/TopView)";
CM_ SG_ 1175 PH_Tongeber_H_aktiv "Rohsignal für 'Tongeber hinten wird angesteuert', verlängerbar mit Nachlauftimer.
Bit wird nicht während des Stellgliedtests angesteuert.";
CM_ SG_ 1175 PH_Tongeber_H_verfuegbar "Tongeber ist für die Tonausgabe für externe Funktionen verfügbar. PDC ist aktiv und Tongeber ist nicht gestört.";
CM_ SG_ 1175 PH_Tongeber_mute "Die Akustikausgabe des Systems wird unterdrückt, z.B. Wählhebel in 'P', Parlbremse geschlossen (8-Kanal-System)";
CM_ SG_ 1175 PH_Tongeber_V_aktiv "Rohsignal für 'Tongeber vorne wird angesteuert', verlängerbar mit Nachlauftimer.
Bit wird nicht während des Stellgliedtests angesteuert.";
CM_ SG_ 1175 PH_Visualisierung "Signal zeigt den Partnersteuergeräten RearView/TopView/ARA/... den aktuellen Status der Visualisierung des OPS. Die Partnersteuergeräte können dadurch auch ihre Aufschaltung an dieses Signal koppeln.";
CM_ SG_ 1175 PLA_Anf_Aufschaltung_RVC "Anforderung der Aufschaltung RVC durch PLA";

CM_ SG_ 1122 PSD_Abzweigerichtung "Richtung, in der die Abzweigung von der Hauptroute abzweigt
";
CM_ SG_ 1122 PSD_Abzweigewinkel "Winkel, unter dem die Abzweigung von der Hauptroute abzweigt.
";
CM_ SG_ 1122 PSD_ADAS_Qualitaet "ADAS Qualtität des Streckensegments.";
CM_ SG_ 1122 PSD_Anfangskruemmung "Startkrümmung der Klothoide des übermittelten abzweigenden Streckensegments. 
1/(1+0.155 * x^2) {1/m}'
";
CM_ SG_ 1122 PSD_Anfangskruemmung_Vorz "Vorzeichen für die Startkrümmung bei Abzweigungen
";
CM_ SG_ 1122 PSD_Bebauung "Segement befindet sich innerhalb bebauten Gebietes";
CM_ SG_ 1122 PSD_Endkruemmung "'Endkrümmung der Klotoide des übermittelten Streckensegments. Die Anfangskrümmung des folgenden Streckensegments entspricht der Endkrümmung dieses Segments. Krümmung = 1/(1+0.155 * x²) [1/m]

";
CM_ SG_ 1122 PSD_Fahrspuren_Anzahl "Anzahl der Fahrspuren in Fahrtrichtung
";
CM_ SG_ 1122 PSD_Geradester_Pfad "Segment ist Teil des geradesten Pfades";
CM_ SG_ 1122 PSD_Idenditaets_ID "Identifier auf ein Streckensegment, dass mit dem aktuell übertragenen geometrisch identisch ist.";
CM_ SG_ 1122 PSD_Segment_ID "Identifier des prädiktiven Streckensegments
";
CM_ SG_ 1122 PSD_Segment_Komplett "Zeigt, ob alle Attribute für das Segment übertragen worden sind
";
CM_ SG_ 1122 PSD_Segmentlaenge "Gesamtlänge des prädiktiven Streckensegments";
CM_ SG_ 1122 PSD_Strassenkategorie "Klassifizierung der Straße des beschriebenen Segments
";
CM_ SG_ 1122 PSD_Vorgaenger_Segment_ID "An dem Streckensegment mit diesem Identifier schließt sich das neue Segment mit der ID 'PSD_01_Segment_ID' an.
";
CM_ SG_ 1122 PSD_wahrscheinlichster_Pfad "Identifiziert den vom Navigationssystem berechneten wahrscheinlichsten Pfad des Fahrzeuges. ";

CM_ SG_ 1123 PSD_Attribut_1_ID "Identifier des ersten Attributes";
CM_ SG_ 1123 PSD_Attribut_1_Offset "Positionsoffset im Segment für die Position des Attributs";
CM_ SG_ 1123 PSD_Attribut_1_Wert "Wert des ersten Attributes";
CM_ SG_ 1123 PSD_Attribut_2_ID "Identifier des zweiten Attributes";
CM_ SG_ 1123 PSD_Attribut_2_Offset "Positionsoffset im Segment für die Position des Attributs";
CM_ SG_ 1123 PSD_Attribut_2_Wert "Wert des zweiten Attributes";
CM_ SG_ 1123 PSD_Attribut_Segment_ID_05 "Identifier des Streckensegments, für das die weiteren Attribute in der Botschaft gültig sind";
CM_ SG_ 1123 PSD_Attribute_Komplett_05 "Zeigt, ob alle Attribute für das Segment übertragen worden sind";
CM_ SG_ 1123 PSD_Pos_Fahrspur "Spur, auf der sich das Fahrzeug aktuell befindet";
CM_ SG_ 1123 PSD_Pos_Fehler_Laengsrichtung "Laengsfehler der Positionierung";
CM_ SG_ 1123 PSD_Pos_Inhibitzeit "Zeitspanne zwischen Generierung der PSD Daten im Navigationssystem und Versand der Daten auf den Most
";
CM_ SG_ 1123 PSD_Pos_Segment_ID "Identifier des Streckensegments, auf dem sich das Fahrzeug aktuell befindet
";
CM_ SG_ 1123 PSD_Pos_Segmentlaenge "Verbleibende Länge des Streckensegments, auf dem sich das Fahrzeug aktuell befindet
";
CM_ SG_ 1123 PSD_Pos_Standort_Eindeutig "Ist die Position des Fahrzeugs eindeutig dem aktuelle Segment zugeordnet, oder gibt es fahrbare alternative Segmente, die bei akteller GPS-Position ebenfalls als aktuelles Segment möglich wären.";

CM_ SG_ 1124 PSD_06_Mux "Multiplex Zähler für die PSD_06-Botschaft.
Die unterschiedlichen Muxe folgen keiner festen Reihenfolge. Je nach Inhalt des PSD-Protokolls an der aktuellen Position werden jeweils die notwendigen PSD6-Botschaften gesendet.";
CM_ SG_ 1124 PSD_Attribut_3_ID "Identifier des dritten Attributes";
CM_ SG_ 1124 PSD_Attribut_3_Offset "Positionsoffset im Segment für die Position des Attributs";
CM_ SG_ 1124 PSD_Attribut_3_Wert "Wert des dritten Attributes";
CM_ SG_ 1124 PSD_Attribut_4_ID "Typ von Attribut 4";
CM_ SG_ 1124 PSD_Attribut_4_Offset "Offset von Attribut 4";
CM_ SG_ 1124 PSD_Attribut_4_Wert "Wert von Attribut 4";
CM_ SG_ 1124 PSD_Attribut_5_ID "Typ von Attribut 5";
CM_ SG_ 1124 PSD_Attribut_5_Offset "Offset von Attribut 5";
CM_ SG_ 1124 PSD_Attribut_5_Wert "Wert von Attribut 5";
CM_ SG_ 1124 PSD_Attribut_Segment_ID "Identifier des Streckensegments,für das die weiteren Attribute in der Botschaft gültig sind";
CM_ SG_ 1124 PSD_Attribute_Komplett_06 "Zeigt, ob alle Attribute für das Segment übertragen worden sind
";
CM_ SG_ 1124 PSD_Baum_Ausrichtung "Ausrichtung des Fahrzeugsegments zu Nord";
CM_ SG_ 1124 PSD_Baum_Breite "WGS84 Breite des Fahrzeugsegments";
CM_ SG_ 1124 PSD_Baum_Breite_VZ "Vorzeichen WGS84 Breite des Fahrzeugsegments";
CM_ SG_ 1124 PSD_Baum_Laenge "WGS84 Laenge des Fahrzeugsegments";
CM_ SG_ 1124 PSD_Baum_Laenge_VZ "Vorzeichen WGS84 Laenge des Fahrzeugsegments";
CM_ SG_ 1124 PSD_Ges_Attribute_Komplett "Zeigt, ob alle Attribute für das Segment übertragen worden sind";
CM_ SG_ 1124 PSD_Ges_Geschwindigkeit_Gespann "Gilt diese Einschränkung der Geschwindigkeit für alle Fahrzeuge oder ausschließlich für PKW mit Gespann oder für LKW, Buss, etc.";
CM_ SG_ 1124 PSD_Ges_Geschwindigkeit_Std_Anf "Stunde, zu der die stündliche Geschwindigkeitsbegrenzung beginnt
0h.. 24h";
CM_ SG_ 1124 PSD_Ges_Geschwindigkeit_Std_Ende "Stunde, an der die stündliche Geschwindigkeitsbegrenzung endet
0h.. 24h";
CM_ SG_ 1124 PSD_Ges_Geschwindigkeit_Tag_Anf "Wochentag, an dem die tägliche Geschwindigkeitsbegrenzung beginnt";
CM_ SG_ 1124 PSD_Ges_Geschwindigkeit_Tag_Ende "Wochentag, an dem die tägliche Geschwindigkeitsbegrenzung endet";
CM_ SG_ 1124 PSD_Ges_Geschwindigkeit_Witter "Witterungsabhängigkeit der Geschwindigkeitsbegrenzung";
CM_ SG_ 1124 PSD_Ges_Gesetzlich_Kategorie "Kategorie für das legale Gebot";
CM_ SG_ 1124 PSD_Ges_Gesetzlich_Zusatz "Zusatz für das legale Gebot";
CM_ SG_ 1124 PSD_Ges_Offset "Positionsoffset im Segment für die Position des Attributs";
CM_ SG_ 1124 PSD_Ges_Segment_ID "Identifier des prädiktiven Streckensegments ab dem die Geschwindigkeitsbegrenzungen und mögliche Einschränkungen gelten.
";
CM_ SG_ 1124 PSD_Ges_Spur_Geschw_Begrenzung "Definition der Spuren, für die das übertragene Gebot gilt";
CM_ SG_ 1124 PSD_Ges_Typ "Typ der Geschwindigkeitsbegrenzung
";
CM_ SG_ 1124 PSD_Ges_Verkehrszeichen_Quelle "Quelle der Verkehrszeicheninformation";
CM_ SG_ 1124 PSD_Ges_Wechselverkehrszeichen "Am Beginn des Segments ist ein Wechselverkehrszeichen angebracht.";
CM_ SG_ 1124 PSD_Steigung_1_A_Offset "Positionsoffset im Segment für die Position der Steigung 1 A";
CM_ SG_ 1124 PSD_Steigung_1_A_Steigung "Steigung des Segments ab Offset 1A";
CM_ SG_ 1124 PSD_Steigung_1_A_Vorz "Vorzeichen für Steigung 1 A";
CM_ SG_ 1124 PSD_Steigung_1_Attribute_kompl "Alle Steigungsdaten für dieses Segment gesendet";
CM_ SG_ 1124 PSD_Steigung_1_B_Offset "Positionsoffset im Segment für die Position der Steigung 1 B";
CM_ SG_ 1124 PSD_Steigung_1_B_Steigung "Steigung des Segments ab Offset 1B";
CM_ SG_ 1124 PSD_Steigung_1_B_Vorz "Vorzeichen für Steigung 1 B";
CM_ SG_ 1124 PSD_Steigung_1_Segment_ID "Identifier des prädiktiven Streckensegments, zu dem die  ersten beiden Steigungswerte dieser Botschaft gehören";
CM_ SG_ 1124 PSD_Steigung_2_Attribute_kompl "Alle Steigungsdaten für dieses Segment gesendet";
CM_ SG_ 1124 PSD_Steigung_2_Offset "Positionsoffset im Segment für die Position der Steigung 2";
CM_ SG_ 1124 PSD_Steigung_2_Segment_ID "Identifier des prädiktiven Streckensegments, zu dem der dritte Steigungswert dieser Botschaft gehört";
CM_ SG_ 1124 PSD_Steigung_2_Steigung "Steigung des Segments ab Offset 2";
CM_ SG_ 1124 PSD_Steigung_2_Vorz "Vorzeichen für Steigung 2";
CM_ SG_ 1124 PSD_Sys_Alter_Karte "Alter der Karte";
CM_ SG_ 1124 PSD_Sys_Geometrieguete "Maß für die Güte der Klothoidengeometrie.";
CM_ SG_ 1124 PSD_Sys_Geometrieguete_erweitert "Güte der Kurvenrepräsentation der Klothoiden";
CM_ SG_ 1124 PSD_Sys_Geschwindigkeit_Einheit "Unterscheidung zwischen km/h und miles/h";
CM_ SG_ 1124 PSD_Sys_Laendercode "Ländercode";
CM_ SG_ 1124 PSD_Sys_Mapmatchingguete "Güte des Mapmatchings";
CM_ SG_ 1124 PSD_Sys_Quali_Geometrien "Qualität der Geometrien in dieser Region";
CM_ SG_ 1124 PSD_Sys_Quali_Ortsinfo "Qualität Ortsinformationen (Bebauung, Ortsschild) dieser Region";
CM_ SG_ 1124 PSD_Sys_Quali_sonstige_Attribute "Qualität sonstiger Attribute dieser Region";
CM_ SG_ 1124 PSD_Sys_Quali_Steigungen "Qualität der Steigungen dieser Region";
CM_ SG_ 1124 PSD_Sys_Quali_Strassenkennz "Qualität Straßenkennzeichnungen dieser Region";
CM_ SG_ 1124 PSD_Sys_Quali_Tempolimits "Qualität Tempolimits dieser Region";
CM_ SG_ 1124 PSD_Sys_Quali_verfuegbar "Karte enthält gültige Qualitätskriterien";
CM_ SG_ 1124 PSD_Sys_Quali_Vorfahrtsregelung "Qualität Vorfahrtsregelungen dieser Region";
CM_ SG_ 1124 PSD_Sys_Segment_ID "Identifier des prädiktiven Streckensegments ab dem die Systeminformationen gültig sind.
";
CM_ SG_ 1124 PSD_Sys_US_State "Name des USA-State";
CM_ SG_ 1124 PSD_Sys_Verkehrsrichtung "Unterscheidung zwischen Linksverkehr und Rechtsverkehr";
CM_ SG_ 1124 PSD_Sys_Zielfuehrung "Zielfuehrung im Navigationssystem. Damit lässt sich der wahrscheinlichste Pfad des Fahrzeuges zuverlässig angeben.";
CM_ SG_ 1124 PSD_Sys_Zielfuehrung_geaendert "Die Zielführung (Route) hat sich geändert hat ohne dass der Fahrer eine neue Zielführung gestartet hat";
CM_ SG_ 1124 PSD_Wechselverkehrszeichen_Typ "Typ des Wechselverkehrszeichen";

CM_ SG_ 1125 PSD_LR_01_MUX "Fehlende Beschreibung (Import)";
CM_ SG_ 1125 PSD_LR_Attribut_1_Offset "Relative Position für Attribut 1 im Profil.
Signal wird nur bei aktiver PSD-Funktion zyklisch gesendet.";
CM_ SG_ 1125 PSD_LR_Attribut_1_Wert "Wert von Attribut 1 (Definition siehe PSD Spec)
Signal wird nur bei aktiver PSD-Funktion zyklisch gesendet.";
CM_ SG_ 1125 PSD_LR_Attribut_2_Offset "Relative Position für Attribut 2 im Profil
Signal wird nur bei aktiver PSD-Funktion zyklisch gesendet.";
CM_ SG_ 1125 PSD_LR_Attribut_2_Wert "Wert von Attribut 2 (Definition siehe PSD Spec)
Signal wird nur bei aktiver PSD-Funktion zyklisch gesendet.";
CM_ SG_ 1125 PSD_LR_Attribut_3_Offset "Relative Position für Attribut 3 im Profil
Signal wird nur bei aktiver PSD-Funktion zyklisch gesendet.";
CM_ SG_ 1125 PSD_LR_Attribut_3_Wert "Wert von Attribut 3 (Definition siehe PSD Spec)
Signal wird nur bei aktiver PSD-Funktion zyklisch gesendet.";
CM_ SG_ 1125 PSD_LR_Fahrzeug_Pos "Position des Fahrzeug in % relativ zur Gesamtlaenge des Profils.
Signal wird nur bei aktiver PSD-Funktion zyklisch gesendet.";
CM_ SG_ 1125 PSD_LR_Globale_Steigung "Gesamtsteigung der in diesem  Profil übertragenen Strecke.
Signal wird nur bei aktiver PSD-Funktion zyklisch gesendet.";
CM_ SG_ 1125 PSD_LR_Globale_Steigung_Vorz "Vorzeichen für globale Steigung des Profils.
Signal wird nur bei aktiver PSD-Funktion zyklisch gesendet.";
CM_ SG_ 1125 PSD_LR_Koeff_1_Amp "Fehlende Beschreibung (Import)";
CM_ SG_ 1125 PSD_LR_Koeff_1_Phase "Phasenwert des ersten FFT-Koeffizienten.
Signal wird nur bei aktiver PSD-Funktion zyklisch gesendet.";
CM_ SG_ 1125 PSD_LR_Koeff_2_Amp "Fehlende Beschreibung (Import)";
CM_ SG_ 1125 PSD_LR_Koeff_2_Phase "Phasenwert des zweiten FFT-Koeffizienten.
Signal wird nur bei aktiver PSD-Funktion zyklisch gesendet.";
CM_ SG_ 1125 PSD_LR_Koeff_3_Amp "Fehlende Beschreibung (Import)";
CM_ SG_ 1125 PSD_LR_Koeff_3_Phase "Phasenwert des dritten FFT-Koeffizienten.
Signal wird nur bei aktiver PSD-Funktion zyklisch gesendet.";
CM_ SG_ 1125 PSD_LR_Koeffizientensatz_Nr "Nummer des aktuell übertragenen Koeffizientansatzes.
Signal wird nur bei aktiver PSD-Funktion zyklisch gesendet.";
CM_ SG_ 1125 PSD_LR_Max_Koeff_Amp "Maximale Höhe der übertragenen Amplitudenwerte.
Signal wird nur bei aktiver PSD-Funktion zyklisch gesendet.";
CM_ SG_ 1125 PSD_LR_Profil_Laenge "Gesamtlänge des übertragenen Profils.
Signal wird nur bei aktiver PSD-Funktion zyklisch gesendet.";
CM_ SG_ 1125 PSD_LR_Profil_Nummer "Nummer des aktuell übertragenen Profils";
CM_ SG_ 1125 PSD_LR_Reset "Reset-Signal, wenn der PSD-LR-Baum ungültig wird.
Signal wird nur bei aktiver PSD-Funktion zyklisch gesendet.";
CM_ SG_ 1125 PSD_LR_Steigung_1_Offset "Relative Position für die Steigung 1 im Profil.
Signal wird nur bei aktiver PSD-Funktion zyklisch gesendet.";
CM_ SG_ 1125 PSD_LR_Steigung_1_Vorz "Vorzeichen für Steigung 1.
Signal wird nur bei aktiver PSD-Funktion zyklisch gesendet.";
CM_ SG_ 1125 PSD_LR_Steigung_1_Wert "Mittlere Steigung zwischen dem Offset 1 und dem letzten Steigungswert.
Signal wird nur bei aktiver PSD-Funktion zyklisch gesendet.";
CM_ SG_ 1125 PSD_LR_Steigung_2_Offset "Relative Position für die Steigung 2 im Profil.
Signal wird nur bei aktiver PSD-Funktion zyklisch gesendet.";
CM_ SG_ 1125 PSD_LR_Steigung_2_Vorz "Vorzeichen für Steigung 2.
Signal wird nur bei aktiver PSD-Funktion zyklisch gesendet.";
CM_ SG_ 1125 PSD_LR_Steigung_2_Wert "Mittlere Steigung zwischen dem Offset 2 und dem letzten Steigungswert.
Signal wird nur bei aktiver PSD-Funktion zyklisch gesendet.";
CM_ SG_ 1125 PSD_LR_Steigung_3_Offset "Relative Position für die Steigung 3 im Profil.
Signal wird nur bei aktiver PSD-Funktion zyklisch gesendet.";
CM_ SG_ 1125 PSD_LR_Steigung_3_Vorz "Vorzeichen für Steigung 3.
Signal wird nur bei aktiver PSD-Funktion zyklisch gesendet.";
CM_ SG_ 1125 PSD_LR_Steigung_3_Wert "Mittlere Steigung zwischen dem Offset 3 und dem letzten Steigungswert.
Signal wird nur bei aktiver PSD-Funktion zyklisch gesendet.";
BA_DEF_REL_ BU_SG_REL_  "GenSigTimeoutTime" INT 0 65535;
BA_DEF_ BO_  "DiagRequest" ENUM "No", "Yes";
BA_DEF_ BO_  "DiagResponse" ENUM "No", "Yes";
BA_DEF_ BO_  "DiagState" ENUM "No", "Yes";
BA_DEF_ BO_  "GenMsgChkConstant" HEX 0 4095;
BA_DEF_ BO_  "GenMsgCycleTime" INT 0 65535;
BA_DEF_ BO_  "GenMsgCycleTimeFast" INT 0 65535;
BA_DEF_ BO_  "GenMsgDelayTime" INT 0 100000;
BA_DEF_ BO_  "GenMsgILSupport" ENUM "No", "Yes";
BA_DEF_ BO_  "GenMsgNrOfRepetition" INT 0 100;
BA_DEF_ BO_  "GenMsgPDUConstants" STRING;
BA_DEF_ BO_  "GenMsgSendType" ENUM "Cyclic", "not_used", "not_used", "not_used", "not_used", "not_used", "not_used", "IfActive", "NoMsgSendType";
BA_DEF_ BO_  "GenMsgStartDelayTime" INT 0 100000;
BA_DEF_ BO_  "NmMessage" ENUM "No", "Yes";
BA_DEF_ BO_  "NmhMessage" ENUM "No", "Yes";
BA_DEF_ BO_  "MsgType" ENUM "Application", "NM ", "NMH", "TP2.0", "ISO-TP ", "BAP", "EID", "KS", "XCP_PRE_CONFIGURED", "XCP_RUNTIME_CONFIGURED";
BA_DEF_ BO_  "VAGTP20_API" HEX 0 255;
BA_DEF_ BO_  "VAGTP20_DynConnection" ENUM "No", "Yes";
BA_DEF_ BO_  "VAGTP20_DynSetup" ENUM "No", "Yes";
BA_DEF_ BO_  "VAGTP20_StatConnection" ENUM "No", "Yes";
BA_DEF_ BO_  "CANFD_BRS" ENUM "0", "1";
BA_DEF_ BO_  "VFrameFormat" ENUM "StandardCAN", "ExtendedCAN", "reserved", "reserved", "reserved", "reserved", "reserved", "reserved", "reserved", "reserved", "reserved", "reserved", "reserved", "reserved", "StandardCAN_FD", "ExtendedCAN_FD";
BA_DEF_ SG_  "GenSigActiveRepetitions" INT -2147483648 2147483647;
BA_DEF_ SG_  "GenSigInactiveValue" INT -2147483648 2147483647;
BA_DEF_ SG_  "GenSigSendType" ENUM "Cyclic", "OnWrite", "OnWriteWithRepetition", "OnChange", "OnChangeWithRepetition", "IfActive", "IfActiveWithRepetition", "NoSigSendType", "OnChangeAndIfActive", "OnChangeAndIfActiveWithRepetition";
BA_DEF_ SG_  "GenSigStartValue" INT -2147483648 2147483647;
BA_DEF_ SG_  "NWM-WakeupAllowed" ENUM "No", "Yes";
BA_DEF_ SG_  "GenSigFuncType" ENUM "NoFunction", "MsgCounter", "CRC-8", "XOR", "XOR-2", "DatedBit", "SW-Kl15", "CHK", "Constant", "Protocol", "CRC-8-SAE_J1850", "CRC-32", "DataLength", "DataID", "MsgCounter16", "SOK-Signatur", "Cluster";
BA_DEF_ SG_  "GenSigSwitchedByIgnition" ENUM "No", "Yes";
BA_DEF_ SG_  "Fehlerwert" HEX 0 2147483647;
BA_DEF_ SG_  "GenSigMissingSourceValue" HEX 0 2147483647;
BA_DEF_DEF_REL_  "GenSigTimeoutTime" 0;
BA_DEF_DEF_  "DiagRequest" "No";
BA_DEF_DEF_  "DiagResponse" "No";
BA_DEF_DEF_  "DiagState" "No";
BA_DEF_DEF_  "GenMsgChkConstant" 0;
BA_DEF_DEF_  "GenMsgCycleTime" 0;
BA_DEF_DEF_  "GenMsgCycleTimeFast" 0;
BA_DEF_DEF_  "GenMsgDelayTime" 0;
BA_DEF_DEF_  "GenMsgILSupport" "No";
BA_DEF_DEF_  "GenMsgNrOfRepetition" 0;
BA_DEF_DEF_  "GenMsgPDUConstants" "";
BA_DEF_DEF_  "GenMsgSendType" "NoMsgSendType";
BA_DEF_DEF_  "GenMsgStartDelayTime" 0;
BA_DEF_DEF_  "NmMessage" "No";
BA_DEF_DEF_  "NmhMessage" "No";
BA_DEF_DEF_  "MsgType" "Application";
BA_DEF_DEF_  "VAGTP20_API" 0;
BA_DEF_DEF_  "VAGTP20_DynConnection" "No";
BA_DEF_DEF_  "VAGTP20_DynSetup" "No";
BA_DEF_DEF_  "VAGTP20_StatConnection" "No";
BA_DEF_DEF_  "CANFD_BRS" "1";
BA_DEF_DEF_  "VFrameFormat" "StandardCAN";
BA_DEF_DEF_  "GenSigActiveRepetitions" 0;
BA_DEF_DEF_  "GenSigInactiveValue" 0;
BA_DEF_DEF_  "GenSigSendType" "NoSigSendType";
BA_DEF_DEF_  "GenSigStartValue" 0;
BA_DEF_DEF_  "NWM-WakeupAllowed" "No";
BA_DEF_DEF_  "GenSigFuncType" "NoFunction";
BA_DEF_DEF_  "GenSigSwitchedByIgnition" "Yes";
BA_DEF_DEF_  "Fehlerwert" 0;
BA_DEF_DEF_  "GenSigMissingSourceValue" 0;
BA_ "GenMsgCycleTime" BO_ 339 200;
BA_ "GenMsgDelayTime" BO_ 339 10;
BA_ "GenMsgILSupport" BO_ 339 1;
BA_ "GenMsgPDUConstants" BO_ 339 "0x03,0x13,0x23,0x7a,0x40,0x51,0x68,0xba,0xa8,0xbe,0x55,0x02,0x11,0x31,0x76,0xec";
BA_ "GenMsgSendType" BO_ 339 0;
BA_ "VFrameFormat" BO_ 339 14;
BA_ "GenMsgCycleTime" BO_ 931 100;
BA_ "GenMsgILSupport" BO_ 931 1;
BA_ "GenMsgSendType" BO_ 931 0;
BA_ "VFrameFormat" BO_ 931 14;
BA_ "GenMsgCycleTime" BO_ 2589283456 500;
BA_ "GenMsgILSupport" BO_ 2589283456 1;
BA_ "GenMsgSendType" BO_ 2589283456 0;
BA_ "VFrameFormat" BO_ 2589283456 15;
BA_ "GenMsgCycleTime" BO_ 2463978719 100;
BA_ "GenMsgDelayTime" BO_ 2463978719 10;
BA_ "GenMsgILSupport" BO_ 2463978719 1;
BA_ "GenMsgPDUConstants" BO_ 2463978719 "0x2e,0x98,0x7f,0xf5,0xa7,0xb6,0x4b,0x47,0xae,0x83,0x04,0x26,0x40,0x45,0x8c,0x9a";
BA_ "GenMsgSendType" BO_ 2463978719 0;
BA_ "VFrameFormat" BO_ 2463978719 15;
BA_ "GenMsgCycleTime" BO_ 1284 100;
BA_ "GenMsgDelayTime" BO_ 1284 10;
BA_ "GenMsgILSupport" BO_ 1284 1;
BA_ "GenMsgPDUConstants" BO_ 1284 "0x03,0x63,0x3e,0x04,0xf9,0xb4,0x4f,0x32,0x25,0x56,0x1e,0xc1,0x83,0xfa,0x31,0x97";
BA_ "GenMsgSendType" BO_ 1284 0;
BA_ "VFrameFormat" BO_ 1284 14;
BA_ "GenMsgCycleTime" BO_ 2600468496 200;
BA_ "GenMsgCycleTimeFast" BO_ 2600468496 10;
BA_ "NmhMessage" BO_ 2600468496 1;
BA_ "MsgType" BO_ 2600468496 2;
BA_ "CANFD_BRS" BO_ 2600468496 0;
BA_ "VFrameFormat" BO_ 2600468496 1;
BA_ "GenMsgCycleTime" BO_ 2600468599 200;
BA_ "GenMsgCycleTimeFast" BO_ 2600468599 10;
BA_ "NmhMessage" BO_ 2600468599 1;
BA_ "MsgType" BO_ 2600468599 2;
BA_ "CANFD_BRS" BO_ 2600468599 0;
BA_ "VFrameFormat" BO_ 2600468599 1;
BA_ "GenMsgCycleTime" BO_ 2600468598 200;
BA_ "GenMsgCycleTimeFast" BO_ 2600468598 10;
BA_ "NmhMessage" BO_ 2600468598 1;
BA_ "MsgType" BO_ 2600468598 2;
BA_ "CANFD_BRS" BO_ 2600468598 0;
BA_ "VFrameFormat" BO_ 2600468598 1;
BA_ "GenMsgCycleTime" BO_ 2600469458 200;
BA_ "GenMsgCycleTimeFast" BO_ 2600469458 10;
BA_ "NmhMessage" BO_ 2600469458 1;
BA_ "MsgType" BO_ 2600469458 2;
BA_ "CANFD_BRS" BO_ 2600469458 0;
BA_ "VFrameFormat" BO_ 2600469458 1;
BA_ "GenMsgCycleTime" BO_ 2600468733 200;
BA_ "GenMsgCycleTimeFast" BO_ 2600468733 10;
BA_ "NmhMessage" BO_ 2600468733 1;
BA_ "MsgType" BO_ 2600468733 2;
BA_ "CANFD_BRS" BO_ 2600468733 0;
BA_ "VFrameFormat" BO_ 2600468733 1;
BA_ "GenMsgCycleTime" BO_ 1630 500;
BA_ "GenMsgILSupport" BO_ 1630 1;
BA_ "GenMsgSendType" BO_ 1630 0;
BA_ "VFrameFormat" BO_ 1630 14;
BA_ "DiagRequest" BO_ 2621440636 1;
BA_ "MsgType" BO_ 2621440636 4;
BA_ "VFrameFormat" BO_ 2621440636 15;
BA_ "DiagResponse" BO_ 2621571708 1;
BA_ "MsgType" BO_ 2621571708 4;
BA_ "VFrameFormat" BO_ 2621571708 15;
BA_ "DiagRequest" BO_ 2621440696 1;
BA_ "MsgType" BO_ 2621440696 4;
BA_ "VFrameFormat" BO_ 2621440696 15;
BA_ "DiagResponse" BO_ 2621571768 1;
BA_ "MsgType" BO_ 2621571768 4;
BA_ "VFrameFormat" BO_ 2621571768 15;
BA_ "DiagState" BO_ 2549940736 1;
BA_ "MsgType" BO_ 2549940736 4;
BA_ "VFrameFormat" BO_ 2549940736 15;
BA_ "DiagState" BO_ 2621506048 1;
BA_ "MsgType" BO_ 2621506048 4;
BA_ "VFrameFormat" BO_ 2621506048 15;
BA_ "DiagRequest" BO_ 2621440631 1;
BA_ "MsgType" BO_ 2621440631 4;
BA_ "VFrameFormat" BO_ 2621440631 15;
BA_ "DiagResponse" BO_ 2621571703 1;
BA_ "MsgType" BO_ 2621571703 4;
BA_ "VFrameFormat" BO_ 2621571703 15;
BA_ "DiagRequest" BO_ 2621702713 1;
BA_ "MsgType" BO_ 2621702713 4;
BA_ "VFrameFormat" BO_ 2621702713 15;
BA_ "DiagResponse" BO_ 2621833785 1;
BA_ "MsgType" BO_ 2621833785 4;
BA_ "VFrameFormat" BO_ 2621833785 15;
BA_ "DiagRequest" BO_ 2621440630 1;
BA_ "MsgType" BO_ 2621440630 4;
BA_ "VFrameFormat" BO_ 2621440630 15;
BA_ "DiagResponse" BO_ 2621571702 1;
BA_ "MsgType" BO_ 2621571702 4;
BA_ "VFrameFormat" BO_ 2621571702 15;
BA_ "DiagRequest" BO_ 2621440645 1;
BA_ "MsgType" BO_ 2621440645 4;
BA_ "VFrameFormat" BO_ 2621440645 15;
BA_ "DiagResponse" BO_ 2621571717 1;
BA_ "MsgType" BO_ 2621571717 4;
BA_ "VFrameFormat" BO_ 2621571717 15;
BA_ "DiagRequest" BO_ 2549875300 1;
BA_ "MsgType" BO_ 2549875300 4;
BA_ "VFrameFormat" BO_ 2549875300 15;
BA_ "DiagResponse" BO_ 2550006372 1;
BA_ "MsgType" BO_ 2550006372 4;
BA_ "VFrameFormat" BO_ 2550006372 15;
BA_ "DiagRequest" BO_ 2549875228 1;
BA_ "MsgType" BO_ 2549875228 4;
BA_ "VFrameFormat" BO_ 2549875228 15;
BA_ "DiagResponse" BO_ 2550006300 1;
BA_ "MsgType" BO_ 2550006300 4;
BA_ "VFrameFormat" BO_ 2550006300 15;
BA_ "DiagRequest" BO_ 2549903629 1;
BA_ "MsgType" BO_ 2549903629 4;
BA_ "VFrameFormat" BO_ 2549903629 15;
BA_ "DiagResponse" BO_ 2550034701 1;
BA_ "MsgType" BO_ 2550034701 4;
BA_ "VFrameFormat" BO_ 2550034701 15;
BA_ "DiagRequest" BO_ 2549903684 1;
BA_ "MsgType" BO_ 2549903684 4;
BA_ "VFrameFormat" BO_ 2549903684 15;
BA_ "DiagResponse" BO_ 2550034756 1;
BA_ "MsgType" BO_ 2550034756 4;
BA_ "VFrameFormat" BO_ 2550034756 15;
BA_ "DiagRequest" BO_ 2549903608 1;
BA_ "MsgType" BO_ 2549903608 4;
BA_ "VFrameFormat" BO_ 2549903608 15;
BA_ "DiagResponse" BO_ 2550034680 1;
BA_ "MsgType" BO_ 2550034680 4;
BA_ "VFrameFormat" BO_ 2550034680 15;
BA_ "DiagRequest" BO_ 2621468994 1;
BA_ "MsgType" BO_ 2621468994 4;
BA_ "VFrameFormat" BO_ 2621468994 15;
BA_ "DiagResponse" BO_ 2621600066 1;
BA_ "MsgType" BO_ 2621600066 4;
BA_ "VFrameFormat" BO_ 2621600066 15;
BA_ "DiagState" BO_ 2564502513 1;
BA_ "MsgType" BO_ 2564502513 4;
BA_ "VFrameFormat" BO_ 2564502513 15;
BA_ "DiagRequest" BO_ 2564424433 1;
BA_ "MsgType" BO_ 2564424433 4;
BA_ "VFrameFormat" BO_ 2564424433 15;
BA_ "DiagResponse" BO_ 2564485378 1;
BA_ "MsgType" BO_ 2564485378 4;
BA_ "VFrameFormat" BO_ 2564485378 15;
BA_ "DiagRequest" BO_ 2564429809 1;
BA_ "MsgType" BO_ 2564429809 4;
BA_ "VFrameFormat" BO_ 2564429809 15;
BA_ "DiagResponse" BO_ 2564485399 1;
BA_ "MsgType" BO_ 2564485399 4;
BA_ "VFrameFormat" BO_ 2564485399 15;
BA_ "DiagRequest" BO_ 2564425457 1;
BA_ "MsgType" BO_ 2564425457 4;
BA_ "VFrameFormat" BO_ 2564425457 15;
BA_ "DiagResponse" BO_ 2564485382 1;
BA_ "MsgType" BO_ 2564485382 4;
BA_ "VFrameFormat" BO_ 2564485382 15;
BA_ "DiagRequest" BO_ 2564425713 1;
BA_ "MsgType" BO_ 2564425713 4;
BA_ "VFrameFormat" BO_ 2564425713 15;
BA_ "DiagResponse" BO_ 2564485383 1;
BA_ "MsgType" BO_ 2564485383 4;
BA_ "VFrameFormat" BO_ 2564485383 15;
BA_ "DiagRequest" BO_ 2564424177 1;
BA_ "MsgType" BO_ 2564424177 4;
BA_ "VFrameFormat" BO_ 2564424177 15;
BA_ "DiagResponse" BO_ 2564485377 1;
BA_ "MsgType" BO_ 2564485377 4;
BA_ "VFrameFormat" BO_ 2564485377 15;
BA_ "DiagRequest" BO_ 2564428017 1;
BA_ "MsgType" BO_ 2564428017 4;
BA_ "VFrameFormat" BO_ 2564428017 15;
BA_ "DiagResponse" BO_ 2564485392 1;
BA_ "MsgType" BO_ 2564485392 4;
BA_ "VFrameFormat" BO_ 2564485392 15;
BA_ "GenMsgCycleTime" BO_ 2463978776 100;
BA_ "GenMsgILSupport" BO_ 2463978776 1;
BA_ "GenMsgPDUConstants" BO_ 2463978776 "0xec,0x0e,0x83,0xa2,0x3c,0xbc,0xd7,0xc6,0x90,0x54,0xdb,0x6d,0x73,0x12,0xcf,0x40";
BA_ "GenMsgSendType" BO_ 2463978776 0;
BA_ "VFrameFormat" BO_ 2463978776 15;
BA_ "GenMsgCycleTime" BO_ 2589284143 1000;
BA_ "GenMsgILSupport" BO_ 2589284143 1;
BA_ "GenMsgSendType" BO_ 2589284143 0;
BA_ "VFrameFormat" BO_ 2589284143 15;
BA_ "GenMsgCycleTime" BO_ 2589283656 500;
BA_ "GenMsgDelayTime" BO_ 2589283656 100;
BA_ "GenMsgILSupport" BO_ 2589283656 1;
BA_ "GenMsgSendType" BO_ 2589283656 0;
BA_ "VFrameFormat" BO_ 2589283656 15;
BA_ "GenMsgCycleTime" BO_ 518 20;
BA_ "GenMsgILSupport" BO_ 518 1;
BA_ "GenMsgPDUConstants" BO_ 518 "0x09,0xfa,0xca,0x8e,0x62,0xd5,0xd1,0xf0,0x31,0xa0,0xaf,0xda,0x4d,0x1a,0x0a,0x97";
BA_ "GenMsgSendType" BO_ 518 0;
BA_ "VFrameFormat" BO_ 518 14;
BA_ "GenMsgCycleTime" BO_ 1175 100;
BA_ "GenMsgDelayTime" BO_ 1175 50;
BA_ "GenMsgILSupport" BO_ 1175 1;
BA_ "GenMsgSendType" BO_ 1175 0;
BA_ "VFrameFormat" BO_ 1175 14;
BA_ "GenMsgCycleTime" BO_ 1122 150;
BA_ "GenMsgILSupport" BO_ 1122 1;
BA_ "GenMsgSendType" BO_ 1122 0;
BA_ "VFrameFormat" BO_ 1122 14;
BA_ "GenMsgCycleTime" BO_ 1123 150;
BA_ "GenMsgILSupport" BO_ 1123 1;
BA_ "GenMsgSendType" BO_ 1123 0;
BA_ "VFrameFormat" BO_ 1123 14;
BA_ "GenMsgCycleTime" BO_ 1124 150;
BA_ "GenMsgILSupport" BO_ 1124 1;
BA_ "GenMsgSendType" BO_ 1124 0;
BA_ "VFrameFormat" BO_ 1124 14;
BA_ "GenMsgCycleTime" BO_ 1125 450;
BA_ "GenMsgILSupport" BO_ 1125 1;
BA_ "GenMsgSendType" BO_ 1125 0;
BA_ "VFrameFormat" BO_ 1125 14;
BA_ "GenSigSendType" SG_ 339 MO_ErwGrenzen_Anf 3;
BA_ "GenSigSwitchedByIgnition" SG_ 339 MO_ErwGrenzen_Anf 0;
BA_ "GenSigSendType" SG_ 339 MO_Fehler_Notentladung_Anf 3;
BA_ "GenSigSwitchedByIgnition" SG_ 339 MO_Fehler_Notentladung_Anf 0;
BA_ "GenSigSendType" SG_ 339 MO_HVEM_Eskalation 3;
BA_ "GenSigSwitchedByIgnition" SG_ 339 MO_HVEM_Eskalation 0;
BA_ "GenSigSendType" SG_ 339 MO_HVEM_MaxLeistung 0;
BA_ "GenSigStartValue" SG_ 339 MO_HVEM_MaxLeistung 510;
BA_ "GenSigSwitchedByIgnition" SG_ 339 MO_HVEM_MaxLeistung 0;
BA_ "GenSigSendType" SG_ 339 MO_HVK_AntriebFehlerstatus 3;
BA_ "GenSigStartValue" SG_ 339 MO_HVK_AntriebFehlerstatus 7;
BA_ "GenSigSwitchedByIgnition" SG_ 339 MO_HVK_AntriebFehlerstatus 0;
BA_ "GenSigSendType" SG_ 339 MO_HVK_AntriebZustand 3;
BA_ "GenSigStartValue" SG_ 339 MO_HVK_AntriebZustand 7;
BA_ "GenSigSwitchedByIgnition" SG_ 339 MO_HVK_AntriebZustand 0;
BA_ "GenSigSendType" SG_ 339 MO_HVK_EmFehlerstatus 3;
BA_ "GenSigStartValue" SG_ 339 MO_HVK_EmFehlerstatus 7;
BA_ "GenSigSwitchedByIgnition" SG_ 339 MO_HVK_EmFehlerstatus 0;
BA_ "GenSigSendType" SG_ 339 MO_HVK_EmIstzustand 3;
BA_ "GenSigStartValue" SG_ 339 MO_HVK_EmIstzustand 255;
BA_ "GenSigSwitchedByIgnition" SG_ 339 MO_HVK_EmIstzustand 0;
BA_ "GenSigSendType" SG_ 339 MO_MVK_AntriebFehlerstatus 3;
BA_ "GenSigStartValue" SG_ 339 MO_MVK_AntriebFehlerstatus 7;
BA_ "GenSigSwitchedByIgnition" SG_ 339 MO_MVK_AntriebFehlerstatus 0;
BA_ "GenSigSendType" SG_ 339 MO_MVK_AntriebZustand 3;
BA_ "GenSigStartValue" SG_ 339 MO_MVK_AntriebZustand 7;
BA_ "GenSigSwitchedByIgnition" SG_ 339 MO_MVK_AntriebZustand 0;
BA_ "GenSigSendType" SG_ 339 MO_MVK_Bordnetz_Anf 3;
BA_ "GenSigSwitchedByIgnition" SG_ 339 MO_MVK_Bordnetz_Anf 0;
BA_ "GenSigSendType" SG_ 339 MO_MVK_EmFehlerstatus 3;
BA_ "GenSigStartValue" SG_ 339 MO_MVK_EmFehlerstatus 7;
BA_ "GenSigSwitchedByIgnition" SG_ 339 MO_MVK_EmFehlerstatus 0;
BA_ "GenSigSendType" SG_ 339 MO_MVK_EmIstzustand 3;
BA_ "GenSigStartValue" SG_ 339 MO_MVK_EmIstzustand 255;
BA_ "GenSigSwitchedByIgnition" SG_ 339 MO_MVK_EmIstzustand 0;
BA_ "GenSigSendType" SG_ 339 MSG_HYB_30_BZ 0;
BA_ "GenSigFuncType" SG_ 339 MSG_HYB_30_BZ 1;
BA_ "GenSigSwitchedByIgnition" SG_ 339 MSG_HYB_30_BZ 0;
BA_ "GenSigSendType" SG_ 339 MSG_HYB_30_CRC 0;
BA_ "GenSigFuncType" SG_ 339 MSG_HYB_30_CRC 2;
BA_ "GenSigSwitchedByIgnition" SG_ 339 MSG_HYB_30_CRC 0;
BA_ "GenSigSendType" SG_ 931 MVEM_DC_SollLeistung_MV 0;
BA_ "GenSigStartValue" SG_ 931 MVEM_DC_SollLeistung_MV 254;
BA_ "GenSigSwitchedByIgnition" SG_ 931 MVEM_DC_SollLeistung_MV 0;
BA_ "Fehlerwert" SG_ 931 MVEM_DC_SollLeistung_MV 255;
BA_ "GenSigSendType" SG_ 931 MVEM_DC_SollSpannung_MV 0;
BA_ "GenSigStartValue" SG_ 931 MVEM_DC_SollSpannung_MV 254;
BA_ "GenSigSwitchedByIgnition" SG_ 931 MVEM_DC_SollSpannung_MV 0;
BA_ "Fehlerwert" SG_ 931 MVEM_DC_SollSpannung_MV 255;
BA_ "GenSigSendType" SG_ 931 MVEM_EMG_MaxGenSpannung 0;
BA_ "GenSigStartValue" SG_ 931 MVEM_EMG_MaxGenSpannung 254;
BA_ "GenSigSwitchedByIgnition" SG_ 931 MVEM_EMG_MaxGenSpannung 0;
BA_ "Fehlerwert" SG_ 931 MVEM_EMG_MaxGenSpannung 255;
BA_ "GenSigSendType" SG_ 931 MVEM_EMG_MaxGenStrom 0;
BA_ "GenSigStartValue" SG_ 931 MVEM_EMG_MaxGenStrom 254;
BA_ "GenSigSwitchedByIgnition" SG_ 931 MVEM_EMG_MaxGenStrom 0;
BA_ "Fehlerwert" SG_ 931 MVEM_EMG_MaxGenStrom 255;
BA_ "GenSigSendType" SG_ 931 MVEM_IstStrom_MVVerbraucher 0;
BA_ "GenSigStartValue" SG_ 931 MVEM_IstStrom_MVVerbraucher 1022;
BA_ "GenSigSwitchedByIgnition" SG_ 931 MVEM_IstStrom_MVVerbraucher 0;
BA_ "Fehlerwert" SG_ 931 MVEM_IstStrom_MVVerbraucher 1023;
BA_ "GenSigSendType" SG_ 2589283456 MVEM_Kaltstart_StuetzLeistung 0;
BA_ "GenSigStartValue" SG_ 2589283456 MVEM_Kaltstart_StuetzLeistung 254;
BA_ "GenSigSwitchedByIgnition" SG_ 2589283456 MVEM_Kaltstart_StuetzLeistung 0;
BA_ "Fehlerwert" SG_ 2589283456 MVEM_Kaltstart_StuetzLeistung 255;
BA_ "GenSigSendType" SG_ 2589283456 MVEM_MO_USoll_Notbetrieb 0;
BA_ "GenSigStartValue" SG_ 2589283456 MVEM_MO_USoll_Notbetrieb 1022;
BA_ "GenSigSwitchedByIgnition" SG_ 2589283456 MVEM_MO_USoll_Notbetrieb 0;
BA_ "Fehlerwert" SG_ 2589283456 MVEM_MO_USoll_Notbetrieb 1023;
BA_ "GenSigSendType" SG_ 2589283456 MVEM_Umax_Rueckspeisung 0;
BA_ "GenSigStartValue" SG_ 2589283456 MVEM_Umax_Rueckspeisung 254;
BA_ "GenSigSwitchedByIgnition" SG_ 2589283456 MVEM_Umax_Rueckspeisung 0;
BA_ "Fehlerwert" SG_ 2589283456 MVEM_Umax_Rueckspeisung 255;
BA_ "GenSigSendType" SG_ 2589283456 MVEM_Umin_Funktionsgruppe_A 0;
BA_ "GenSigStartValue" SG_ 2589283456 MVEM_Umin_Funktionsgruppe_A 254;
BA_ "GenSigSwitchedByIgnition" SG_ 2589283456 MVEM_Umin_Funktionsgruppe_A 0;
BA_ "Fehlerwert" SG_ 2589283456 MVEM_Umin_Funktionsgruppe_A 255;
BA_ "GenSigSendType" SG_ 2589283456 MVEM_Umin_Funktionsgruppe_B 0;
BA_ "GenSigStartValue" SG_ 2589283456 MVEM_Umin_Funktionsgruppe_B 254;
BA_ "GenSigSwitchedByIgnition" SG_ 2589283456 MVEM_Umin_Funktionsgruppe_B 0;
BA_ "Fehlerwert" SG_ 2589283456 MVEM_Umin_Funktionsgruppe_B 255;
BA_ "GenSigSendType" SG_ 2589283456 MVEM_Umin_Funktionsgruppe_C 0;
BA_ "GenSigStartValue" SG_ 2589283456 MVEM_Umin_Funktionsgruppe_C 254;
BA_ "GenSigSwitchedByIgnition" SG_ 2589283456 MVEM_Umin_Funktionsgruppe_C 0;
BA_ "Fehlerwert" SG_ 2589283456 MVEM_Umin_Funktionsgruppe_C 255;
BA_ "GenSigSendType" SG_ 2463978719 MVEM_03_BZ 0;
BA_ "GenSigFuncType" SG_ 2463978719 MVEM_03_BZ 1;
BA_ "GenSigSwitchedByIgnition" SG_ 2463978719 MVEM_03_BZ 0;
BA_ "GenSigSendType" SG_ 2463978719 MVEM_03_CRC 0;
BA_ "GenSigFuncType" SG_ 2463978719 MVEM_03_CRC 2;
BA_ "GenSigSwitchedByIgnition" SG_ 2463978719 MVEM_03_CRC 0;
BA_ "GenSigSendType" SG_ 2463978719 MVEM_Eskalation_Energieversorgun 3;
BA_ "GenSigSwitchedByIgnition" SG_ 2463978719 MVEM_Eskalation_Energieversorgun 0;
BA_ "GenSigSendType" SG_ 2463978719 MVEM_IstLeistung_MVVerbraucher 0;
BA_ "GenSigStartValue" SG_ 2463978719 MVEM_IstLeistung_MVVerbraucher 1022;
BA_ "GenSigSwitchedByIgnition" SG_ 2463978719 MVEM_IstLeistung_MVVerbraucher 0;
BA_ "Fehlerwert" SG_ 2463978719 MVEM_IstLeistung_MVVerbraucher 1023;
BA_ "GenSigSendType" SG_ 2463978719 MVEM_MO_anbietLeist_MVVerbrauch 0;
BA_ "GenSigStartValue" SG_ 2463978719 MVEM_MO_anbietLeist_MVVerbrauch 1022;
BA_ "GenSigSwitchedByIgnition" SG_ 2463978719 MVEM_MO_anbietLeist_MVVerbrauch 0;
BA_ "Fehlerwert" SG_ 2463978719 MVEM_MO_anbietLeist_MVVerbrauch 1023;
BA_ "GenSigSendType" SG_ 2463978719 MVEM_MO_MinLeistung_MVVerbrauch 0;
BA_ "GenSigStartValue" SG_ 2463978719 MVEM_MO_MinLeistung_MVVerbrauch 1022;
BA_ "GenSigSwitchedByIgnition" SG_ 2463978719 MVEM_MO_MinLeistung_MVVerbrauch 0;
BA_ "Fehlerwert" SG_ 2463978719 MVEM_MO_MinLeistung_MVVerbrauch 1023;
BA_ "GenSigSendType" SG_ 2463978719 MVEM_MO_WunschLeist_MVVerbrauch 0;
BA_ "GenSigStartValue" SG_ 2463978719 MVEM_MO_WunschLeist_MVVerbrauch 1022;
BA_ "GenSigSwitchedByIgnition" SG_ 2463978719 MVEM_MO_WunschLeist_MVVerbrauch 0;
BA_ "Fehlerwert" SG_ 2463978719 MVEM_MO_WunschLeist_MVVerbrauch 1023;
BA_ "GenSigSendType" SG_ 1284 MV_Bordnetz_aktiv 0;
BA_ "GenSigSwitchedByIgnition" SG_ 1284 MV_Bordnetz_aktiv 0;
BA_ "GenSigSendType" SG_ 1284 MV_Bordnetz_belastbar 3;
BA_ "GenSigSwitchedByIgnition" SG_ 1284 MV_Bordnetz_belastbar 0;
BA_ "GenSigSendType" SG_ 1284 MV_Bordnetz_Fehler 3;
BA_ "GenSigSwitchedByIgnition" SG_ 1284 MV_Bordnetz_Fehler 0;
BA_ "Fehlerwert" SG_ 1284 MV_Bordnetz_Fehler 1;
BA_ "GenSigSendType" SG_ 1284 MVK_01_BZ 0;
BA_ "GenSigFuncType" SG_ 1284 MVK_01_BZ 1;
BA_ "GenSigSwitchedByIgnition" SG_ 1284 MVK_01_BZ 0;
BA_ "GenSigSendType" SG_ 1284 MVK_01_CRC 0;
BA_ "GenSigFuncType" SG_ 1284 MVK_01_CRC 2;
BA_ "GenSigSwitchedByIgnition" SG_ 1284 MVK_01_CRC 0;
BA_ "GenSigSendType" SG_ 1284 MVK_BMS_Sollmodus 3;
BA_ "GenSigStartValue" SG_ 1284 MVK_BMS_Sollmodus 7;
BA_ "GenSigSwitchedByIgnition" SG_ 1284 MVK_BMS_Sollmodus 0;
BA_ "GenSigSendType" SG_ 1284 MVK_BOOST_Sollmodus 3;
BA_ "GenSigStartValue" SG_ 1284 MVK_BOOST_Sollmodus 7;
BA_ "GenSigSwitchedByIgnition" SG_ 1284 MVK_BOOST_Sollmodus 0;
BA_ "GenSigSendType" SG_ 1284 MVK_DCDC_Sollmodus 3;
BA_ "GenSigStartValue" SG_ 1284 MVK_DCDC_Sollmodus 7;
BA_ "GenSigSwitchedByIgnition" SG_ 1284 MVK_DCDC_Sollmodus 0;
BA_ "GenSigSendType" SG_ 1284 MVK_DCDC_Sollmodus_02 3;
BA_ "GenSigStartValue" SG_ 1284 MVK_DCDC_Sollmodus_02 7;
BA_ "GenSigSwitchedByIgnition" SG_ 1284 MVK_DCDC_Sollmodus_02 0;
BA_ "GenSigSendType" SG_ 1284 MVK_eABC_Sollmodus 3;
BA_ "GenSigStartValue" SG_ 1284 MVK_eABC_Sollmodus 7;
BA_ "GenSigSwitchedByIgnition" SG_ 1284 MVK_eABC_Sollmodus 0;
BA_ "GenSigSendType" SG_ 1284 MVK_eAWS_Sollmodus 3;
BA_ "GenSigStartValue" SG_ 1284 MVK_eAWS_Sollmodus 7;
BA_ "GenSigSwitchedByIgnition" SG_ 1284 MVK_eAWS_Sollmodus 0;
BA_ "GenSigSendType" SG_ 1284 MVK_Istmodus_Anf 3;
BA_ "GenSigSwitchedByIgnition" SG_ 1284 MVK_Istmodus_Anf 0;
BA_ "GenSigSendType" SG_ 1284 MVK_MO_EmSollzustand 3;
BA_ "GenSigStartValue" SG_ 1284 MVK_MO_EmSollzustand 255;
BA_ "GenSigSwitchedByIgnition" SG_ 1284 MVK_MO_EmSollzustand 0;
BA_ "GenSigSendType" SG_ 1284 MVK_MV_Batteriewarnung 3;
BA_ "GenSigSwitchedByIgnition" SG_ 1284 MVK_MV_Batteriewarnung 0;
BA_ "GenSigSendType" SG_ 1284 MVK_MV_Netz_Warnungen 3;
BA_ "GenSigSwitchedByIgnition" SG_ 1284 MVK_MV_Netz_Warnungen 0;
BA_ "GenSigSendType" SG_ 1284 MVK_MVPTC_Sollmodus 3;
BA_ "GenSigStartValue" SG_ 1284 MVK_MVPTC_Sollmodus 7;
BA_ "GenSigSwitchedByIgnition" SG_ 1284 MVK_MVPTC_Sollmodus 0;
BA_ "GenSigFuncType" SG_ 2600468496 NM_Gateway_CAB_V14 16;
BA_ "GenSigSwitchedByIgnition" SG_ 2600468496 NM_Gateway_CAB_V14 0;
BA_ "GenSigSwitchedByIgnition" SG_ 2600468496 NM_Gateway_Car_Wakeup 0;
BA_ "GenSigSwitchedByIgnition" SG_ 2600468496 NM_Gateway_CBV_AWB 0;
BA_ "GenSigSwitchedByIgnition" SG_ 2600468496 NM_Gateway_CBV_CRI 0;
BA_ "GenSigSwitchedByIgnition" SG_ 2600468496 NM_Gateway_NM_aktiv_Buskopplung 0;
BA_ "GenSigSwitchedByIgnition" SG_ 2600468496 NM_Gateway_NM_aktiv_CWU 0;
BA_ "GenSigSwitchedByIgnition" SG_ 2600468496 NM_Gateway_NM_aktiv_Diagnose 0;
BA_ "GenSigSwitchedByIgnition" SG_ 2600468496 NM_Gateway_NM_aktiv_EM 0;
BA_ "GenSigSwitchedByIgnition" SG_ 2600468496 NM_Gateway_NM_aktiv_FC 0;
BA_ "GenSigSwitchedByIgnition" SG_ 2600468496 NM_Gateway_NM_aktiv_KL15 0;
BA_ "GenSigSwitchedByIgnition" SG_ 2600468496 NM_Gateway_NM_aktiv_Tmin 0;
BA_ "GenSigSwitchedByIgnition" SG_ 2600468496 NM_Gateway_NM_State 0;
BA_ "GenSigSwitchedByIgnition" SG_ 2600468496 NM_Gateway_UDS_CC 0;
BA_ "GenSigFuncType" SG_ 2600468599 NM_Getriebe_01_CAB_V14 16;
BA_ "GenSigSwitchedByIgnition" SG_ 2600468599 NM_Getriebe_01_CAB_V14 0;
BA_ "GenSigSwitchedByIgnition" SG_ 2600468599 NM_Getriebe_01_Car_Wakeup 0;
BA_ "GenSigSwitchedByIgnition" SG_ 2600468599 NM_Getriebe_01_CBV_AWB 0;
BA_ "GenSigSwitchedByIgnition" SG_ 2600468599 NM_Getriebe_01_CBV_CRI 0;
BA_ "GenSigSwitchedByIgnition" SG_ 2600468599 NM_Getriebe_01_NM_aktiv_Diagnose 0;
BA_ "GenSigSwitchedByIgnition" SG_ 2600468599 NM_Getriebe_01_NM_aktiv_KL15 0;
BA_ "GenSigSwitchedByIgnition" SG_ 2600468599 NM_Getriebe_01_NM_aktiv_N_Halte 0;
BA_ "GenSigSwitchedByIgnition" SG_ 2600468599 NM_Getriebe_01_NM_aktiv_PosAnz 0;
BA_ "GenSigSwitchedByIgnition" SG_ 2600468599 NM_Getriebe_01_NM_aktiv_Tmin 0;
BA_ "GenSigSwitchedByIgnition" SG_ 2600468599 NM_Getriebe_01_NM_aktiv_v_gr_0 0;
BA_ "GenSigSwitchedByIgnition" SG_ 2600468599 NM_Getriebe_01_NM_aktiv_Waehlheb 0;
BA_ "GenSigSwitchedByIgnition" SG_ 2600468599 NM_Getriebe_01_NM_State 0;
BA_ "GenSigSwitchedByIgnition" SG_ 2600468599 NM_Getriebe_01_UDS_CC 0;
BA_ "GenSigFuncType" SG_ 2600468598 NM_MO_01_CAB_V14 16;
BA_ "GenSigSwitchedByIgnition" SG_ 2600468598 NM_MO_01_CAB_V14 0;
BA_ "GenSigSwitchedByIgnition" SG_ 2600468598 NM_MO_01_Car_Wakeup 0;
BA_ "GenSigSwitchedByIgnition" SG_ 2600468598 NM_MO_01_CBV_AWB 0;
BA_ "GenSigSwitchedByIgnition" SG_ 2600468598 NM_MO_01_CBV_CRI 0;
BA_ "GenSigSwitchedByIgnition" SG_ 2600468598 NM_MO_01_NM_aktiv_Anf_RSG 0;
BA_ "GenSigSwitchedByIgnition" SG_ 2600468598 NM_MO_01_NM_aktiv_AnzKLuefter 0;
BA_ "GenSigSwitchedByIgnition" SG_ 2600468598 NM_MO_01_NM_aktiv_Betankung 0;
BA_ "GenSigSwitchedByIgnition" SG_ 2600468598 NM_MO_01_NM_aktiv_Diagnose 0;
BA_ "GenSigSwitchedByIgnition" SG_ 2600468598 NM_MO_01_NM_aktiv_EKP_Vorlauf 0;
BA_ "GenSigSwitchedByIgnition" SG_ 2600468598 NM_MO_01_NM_aktiv_Hochvolt 0;
BA_ "GenSigSwitchedByIgnition" SG_ 2600468598 NM_MO_01_NM_aktiv_HV_Abschaltung 0;
BA_ "GenSigSwitchedByIgnition" SG_ 2600468598 NM_MO_01_NM_aktiv_KL15 0;
BA_ "GenSigSwitchedByIgnition" SG_ 2600468598 NM_MO_01_NM_aktiv_NOx_PM_SensDia 0;
BA_ "GenSigSwitchedByIgnition" SG_ 2600468598 NM_MO_01_NM_aktiv_Oelstandsmes 0;
BA_ "GenSigSwitchedByIgnition" SG_ 2600468598 NM_MO_01_NM_aktiv_STH_Betrieb 0;
BA_ "GenSigSwitchedByIgnition" SG_ 2600468598 NM_MO_01_NM_aktiv_Tmin 0;
BA_ "GenSigSwitchedByIgnition" SG_ 2600468598 NM_MO_01_NM_aktiv_Waehlhebel 0;
BA_ "GenSigSwitchedByIgnition" SG_ 2600468598 NM_MO_01_NM_State 0;
BA_ "GenSigSwitchedByIgnition" SG_ 2600468598 NM_MO_01_UDS_CC 0;
BA_ "GenSigSwitchedByIgnition" SG_ 2600469458 NM_Parksperre_aktiv_Feder_n_entl 0;
BA_ "GenSigFuncType" SG_ 2600469458 NM_Parksperre_CAB_V14 16;
BA_ "GenSigSwitchedByIgnition" SG_ 2600469458 NM_Parksperre_CAB_V14 0;
BA_ "GenSigSwitchedByIgnition" SG_ 2600469458 NM_Parksperre_Car_Wakeup 0;
BA_ "GenSigSwitchedByIgnition" SG_ 2600469458 NM_Parksperre_CBV_AWB 0;
BA_ "GenSigSwitchedByIgnition" SG_ 2600469458 NM_Parksperre_CBV_CRI 0;
BA_ "GenSigSwitchedByIgnition" SG_ 2600469458 NM_Parksperre_NM_aktiv_Diagnose 0;
BA_ "GenSigSwitchedByIgnition" SG_ 2600469458 NM_Parksperre_NM_aktiv_KL15 0;
BA_ "GenSigSwitchedByIgnition" SG_ 2600469458 NM_Parksperre_NM_aktiv_Tmin 0;
BA_ "GenSigSwitchedByIgnition" SG_ 2600469458 NM_Parksperre_NM_State 0;
BA_ "GenSigSwitchedByIgnition" SG_ 2600469458 NM_Parksperre_UDS_CC 0;
BA_ "GenSigFuncType" SG_ 2600468733 NM_Waehlhebel_CAB_V14 16;
BA_ "GenSigSwitchedByIgnition" SG_ 2600468733 NM_Waehlhebel_CAB_V14 0;
BA_ "GenSigSwitchedByIgnition" SG_ 2600468733 NM_Waehlhebel_Car_Wakeup 0;
BA_ "GenSigSwitchedByIgnition" SG_ 2600468733 NM_Waehlhebel_CBV_AWB 0;
BA_ "GenSigSwitchedByIgnition" SG_ 2600468733 NM_Waehlhebel_CBV_CRI 0;
BA_ "GenSigSwitchedByIgnition" SG_ 2600468733 NM_Waehlhebel_NM_aktiv_Diagnose 0;
BA_ "GenSigSwitchedByIgnition" SG_ 2600468733 NM_Waehlhebel_NM_aktiv_KL15 0;
BA_ "GenSigSwitchedByIgnition" SG_ 2600468733 NM_Waehlhebel_NM_aktiv_Tmin 0;
BA_ "GenSigSwitchedByIgnition" SG_ 2600468733 NM_Waehlhebel_NM_State 0;
BA_ "GenSigSwitchedByIgnition" SG_ 2600468733 NM_Waehlhebel_UDS_CC 0;
BA_ "GenSigSendType" SG_ 1630 OBD_TG_F_Status_1 0;
BA_ "GenSigSwitchedByIgnition" SG_ 1630 OBD_TG_F_Status_1 0;
BA_ "GenSigSendType" SG_ 1630 OBD_TG_F_Status_2 0;
BA_ "GenSigSwitchedByIgnition" SG_ 1630 OBD_TG_F_Status_2 0;
BA_ "GenSigSendType" SG_ 1630 OBD_TG_F_Status_3 0;
BA_ "GenSigSwitchedByIgnition" SG_ 1630 OBD_TG_F_Status_3 0;
BA_ "GenSigSendType" SG_ 1630 OBD_TG_F_Status_4 0;
BA_ "GenSigSwitchedByIgnition" SG_ 1630 OBD_TG_F_Status_4 0;
BA_ "GenSigSendType" SG_ 1630 OBD_TG_Sens_Rohwert_1 0;
BA_ "GenSigSwitchedByIgnition" SG_ 1630 OBD_TG_Sens_Rohwert_1 0;
BA_ "GenSigSendType" SG_ 1630 OBD_TG_Sens_Rohwert_2 0;
BA_ "GenSigSwitchedByIgnition" SG_ 1630 OBD_TG_Sens_Rohwert_2 0;
BA_ "GenSigSendType" SG_ 1630 OBD_TG_Sens_Rohwert_3 0;
BA_ "GenSigSwitchedByIgnition" SG_ 1630 OBD_TG_Sens_Rohwert_3 0;
BA_ "GenSigSendType" SG_ 1630 OBD_TG_Sens_Rohwert_4 0;
BA_ "GenSigSwitchedByIgnition" SG_ 1630 OBD_TG_Sens_Rohwert_4 0;
BA_ "GenSigSendType" SG_ 2621440636 OBDC_EMotor_01_Req_FD_Data 3;
BA_ "GenSigFuncType" SG_ 2621440636 OBDC_EMotor_01_Req_FD_Data 9;
BA_ "GenSigSwitchedByIgnition" SG_ 2621440636 OBDC_EMotor_01_Req_FD_Data 0;
BA_ "GenSigSendType" SG_ 2621571708 OBDC_EMotor_01_Resp_FD_Data 3;
BA_ "GenSigFuncType" SG_ 2621571708 OBDC_EMotor_01_Resp_FD_Data 9;
BA_ "GenSigSwitchedByIgnition" SG_ 2621571708 OBDC_EMotor_01_Resp_FD_Data 0;
BA_ "GenSigSendType" SG_ 2621440696 OBDC_EMotor_02_Req_FD_Data 3;
BA_ "GenSigFuncType" SG_ 2621440696 OBDC_EMotor_02_Req_FD_Data 9;
BA_ "GenSigSwitchedByIgnition" SG_ 2621440696 OBDC_EMotor_02_Req_FD_Data 0;
BA_ "GenSigSendType" SG_ 2621571768 OBDC_EMotor_02_Resp_FD_Data 3;
BA_ "GenSigFuncType" SG_ 2621571768 OBDC_EMotor_02_Resp_FD_Data 9;
BA_ "GenSigSwitchedByIgnition" SG_ 2621571768 OBDC_EMotor_02_Resp_FD_Data 0;
BA_ "GenSigSendType" SG_ 2549940736 OBDC_Funktionaler_Req_All_Data 3;
BA_ "GenSigFuncType" SG_ 2549940736 OBDC_Funktionaler_Req_All_Data 9;
BA_ "GenSigSwitchedByIgnition" SG_ 2549940736 OBDC_Funktionaler_Req_All_Data 0;
BA_ "GenSigSendType" SG_ 2621506048 OBDC_Funktion_Req_All_FD_Data 3;
BA_ "GenSigFuncType" SG_ 2621506048 OBDC_Funktion_Req_All_FD_Data 9;
BA_ "GenSigSwitchedByIgnition" SG_ 2621506048 OBDC_Funktion_Req_All_FD_Data 0;
BA_ "GenSigSendType" SG_ 2621440631 OBDC_Getriebe_01_Req_FD_Data 3;
BA_ "GenSigFuncType" SG_ 2621440631 OBDC_Getriebe_01_Req_FD_Data 9;
BA_ "GenSigSwitchedByIgnition" SG_ 2621440631 OBDC_Getriebe_01_Req_FD_Data 0;
BA_ "GenSigSendType" SG_ 2621571703 OBDC_Getriebe_01_Resp_FD_Data 3;
BA_ "GenSigFuncType" SG_ 2621571703 OBDC_Getriebe_01_Resp_FD_Data 9;
BA_ "GenSigSwitchedByIgnition" SG_ 2621571703 OBDC_Getriebe_01_Resp_FD_Data 0;
BA_ "GenSigSendType" SG_ 2621702713 OBDC_LCU_SMH_Req_FD_Data 3;
BA_ "GenSigFuncType" SG_ 2621702713 OBDC_LCU_SMH_Req_FD_Data 9;
BA_ "GenSigSwitchedByIgnition" SG_ 2621702713 OBDC_LCU_SMH_Req_FD_Data 0;
BA_ "GenSigSendType" SG_ 2621833785 OBDC_LCU_SMH_Resp_FD_Data 3;
BA_ "GenSigFuncType" SG_ 2621833785 OBDC_LCU_SMH_Resp_FD_Data 9;
BA_ "GenSigSwitchedByIgnition" SG_ 2621833785 OBDC_LCU_SMH_Resp_FD_Data 0;
BA_ "GenSigSendType" SG_ 2621440630 OBDC_MO_01_Req_FD_Data 3;
BA_ "GenSigFuncType" SG_ 2621440630 OBDC_MO_01_Req_FD_Data 9;
BA_ "GenSigSwitchedByIgnition" SG_ 2621440630 OBDC_MO_01_Req_FD_Data 0;
BA_ "GenSigSendType" SG_ 2621571702 OBDC_MO_01_Resp_FD_Data 3;
BA_ "GenSigFuncType" SG_ 2621571702 OBDC_MO_01_Resp_FD_Data 9;
BA_ "GenSigSwitchedByIgnition" SG_ 2621571702 OBDC_MO_01_Resp_FD_Data 0;
BA_ "GenSigSendType" SG_ 2621440645 OBDC_RSG_Req_FD_Data 3;
BA_ "GenSigFuncType" SG_ 2621440645 OBDC_RSG_Req_FD_Data 9;
BA_ "GenSigSwitchedByIgnition" SG_ 2621440645 OBDC_RSG_Req_FD_Data 0;
BA_ "GenSigSendType" SG_ 2621571717 OBDC_RSG_Resp_FD_Data 3;
BA_ "GenSigFuncType" SG_ 2621571717 OBDC_RSG_Resp_FD_Data 9;
BA_ "GenSigSwitchedByIgnition" SG_ 2621571717 OBDC_RSG_Resp_FD_Data 0;
BA_ "GenSigSendType" SG_ 2549875300 OBDC_Soundaktor2_Req_Data 3;
BA_ "GenSigFuncType" SG_ 2549875300 OBDC_Soundaktor2_Req_Data 9;
BA_ "GenSigSwitchedByIgnition" SG_ 2549875300 OBDC_Soundaktor2_Req_Data 0;
BA_ "GenSigSendType" SG_ 2550006372 OBDC_Soundaktor2_Resp_Data 3;
BA_ "GenSigFuncType" SG_ 2550006372 OBDC_Soundaktor2_Resp_Data 9;
BA_ "GenSigSwitchedByIgnition" SG_ 2550006372 OBDC_Soundaktor2_Resp_Data 0;
BA_ "GenSigSendType" SG_ 2549875228 OBDC_Soundaktor_Req_Data 3;
BA_ "GenSigFuncType" SG_ 2549875228 OBDC_Soundaktor_Req_Data 9;
BA_ "GenSigSwitchedByIgnition" SG_ 2549875228 OBDC_Soundaktor_Req_Data 0;
BA_ "GenSigSendType" SG_ 2550006300 OBDC_Soundaktor_Resp_Data 3;
BA_ "GenSigFuncType" SG_ 2550006300 OBDC_Soundaktor_Resp_Data 9;
BA_ "GenSigSwitchedByIgnition" SG_ 2550006300 OBDC_Soundaktor_Resp_Data 0;
BA_ "GenSigSendType" SG_ 2549903629 OBDC_SSN_eBooster_Req_Data 3;
BA_ "GenSigFuncType" SG_ 2549903629 OBDC_SSN_eBooster_Req_Data 9;
BA_ "GenSigSwitchedByIgnition" SG_ 2549903629 OBDC_SSN_eBooster_Req_Data 0;
BA_ "GenSigSendType" SG_ 2550034701 OBDC_SSN_eBooster_Resp_Data 3;
BA_ "GenSigFuncType" SG_ 2550034701 OBDC_SSN_eBooster_Resp_Data 9;
BA_ "GenSigSwitchedByIgnition" SG_ 2550034701 OBDC_SSN_eBooster_Resp_Data 0;
BA_ "GenSigSendType" SG_ 2549903684 OBDC_SSN_EKAT_Req_Data 3;
BA_ "GenSigFuncType" SG_ 2549903684 OBDC_SSN_EKAT_Req_Data 9;
BA_ "GenSigSwitchedByIgnition" SG_ 2549903684 OBDC_SSN_EKAT_Req_Data 0;
BA_ "GenSigSendType" SG_ 2550034756 OBDC_SSN_EKAT_Resp_Data 3;
BA_ "GenSigFuncType" SG_ 2550034756 OBDC_SSN_EKAT_Resp_Data 9;
BA_ "GenSigSwitchedByIgnition" SG_ 2550034756 OBDC_SSN_EKAT_Resp_Data 0;
BA_ "GenSigSendType" SG_ 2549903608 OBDC_SSN_MTFP_Req_Data 3;
BA_ "GenSigFuncType" SG_ 2549903608 OBDC_SSN_MTFP_Req_Data 9;
BA_ "GenSigSwitchedByIgnition" SG_ 2549903608 OBDC_SSN_MTFP_Req_Data 0;
BA_ "GenSigSendType" SG_ 2550034680 OBDC_SSN_MTFP_Resp_Data 3;
BA_ "GenSigFuncType" SG_ 2550034680 OBDC_SSN_MTFP_Resp_Data 9;
BA_ "GenSigSwitchedByIgnition" SG_ 2550034680 OBDC_SSN_MTFP_Resp_Data 0;
BA_ "GenSigSendType" SG_ 2621468994 OBDC_SSN_Parksperre_Req_FD_Data 3;
BA_ "GenSigFuncType" SG_ 2621468994 OBDC_SSN_Parksperre_Req_FD_Data 9;
BA_ "GenSigSwitchedByIgnition" SG_ 2621468994 OBDC_SSN_Parksperre_Req_FD_Data 0;
BA_ "GenSigSendType" SG_ 2621600066 OBDC_SSN_Parksperre_Resp_FD_Data 3;
BA_ "GenSigFuncType" SG_ 2621600066 OBDC_SSN_Parksperre_Resp_FD_Data 9;
BA_ "GenSigSwitchedByIgnition" SG_ 2621600066 OBDC_SSN_Parksperre_Resp_FD_Data 0;
BA_ "GenSigSendType" SG_ 2564502513 OBDx_allOBD_Req_Data 3;
BA_ "GenSigFuncType" SG_ 2564502513 OBDx_allOBD_Req_Data 9;
BA_ "GenSigSwitchedByIgnition" SG_ 2564502513 OBDx_allOBD_Req_Data 0;
BA_ "GenSigSendType" SG_ 2564424433 OBDx_Getriebe_01_Req_Data 3;
BA_ "GenSigFuncType" SG_ 2564424433 OBDx_Getriebe_01_Req_Data 9;
BA_ "GenSigSwitchedByIgnition" SG_ 2564424433 OBDx_Getriebe_01_Req_Data 0;
BA_ "GenSigSendType" SG_ 2564485378 OBDx_Getriebe_01_Resp_Data 3;
BA_ "GenSigFuncType" SG_ 2564485378 OBDx_Getriebe_01_Resp_Data 9;
BA_ "GenSigSwitchedByIgnition" SG_ 2564485378 OBDx_Getriebe_01_Resp_Data 0;
BA_ "GenSigSendType" SG_ 2564429809 OBDx_LCU_SMH_Req_Data 3;
BA_ "GenSigFuncType" SG_ 2564429809 OBDx_LCU_SMH_Req_Data 9;
BA_ "GenSigSwitchedByIgnition" SG_ 2564429809 OBDx_LCU_SMH_Req_Data 0;
BA_ "GenSigSendType" SG_ 2564485399 OBDx_LCU_SMH_Resp_Data 3;
BA_ "GenSigFuncType" SG_ 2564485399 OBDx_LCU_SMH_Resp_Data 9;
BA_ "GenSigSwitchedByIgnition" SG_ 2564485399 OBDx_LCU_SMH_Resp_Data 0;
BA_ "GenSigSendType" SG_ 2564425457 OBDx_LE1_Req_Data 3;
BA_ "GenSigFuncType" SG_ 2564425457 OBDx_LE1_Req_Data 9;
BA_ "GenSigSwitchedByIgnition" SG_ 2564425457 OBDx_LE1_Req_Data 0;
BA_ "GenSigSendType" SG_ 2564485382 OBDx_LE1_Resp_Data 3;
BA_ "GenSigFuncType" SG_ 2564485382 OBDx_LE1_Resp_Data 9;
BA_ "GenSigSwitchedByIgnition" SG_ 2564485382 OBDx_LE1_Resp_Data 0;
BA_ "GenSigSendType" SG_ 2564425713 OBDx_LE2_Req_Data 3;
BA_ "GenSigFuncType" SG_ 2564425713 OBDx_LE2_Req_Data 9;
BA_ "GenSigSwitchedByIgnition" SG_ 2564425713 OBDx_LE2_Req_Data 0;
BA_ "GenSigSendType" SG_ 2564485383 OBDx_LE2_Resp_Data 3;
BA_ "GenSigFuncType" SG_ 2564485383 OBDx_LE2_Resp_Data 9;
BA_ "GenSigSwitchedByIgnition" SG_ 2564485383 OBDx_LE2_Resp_Data 0;
BA_ "GenSigSendType" SG_ 2564424177 OBDx_MO_01_Req_Data 3;
BA_ "GenSigFuncType" SG_ 2564424177 OBDx_MO_01_Req_Data 9;
BA_ "GenSigSwitchedByIgnition" SG_ 2564424177 OBDx_MO_01_Req_Data 0;
BA_ "GenSigSendType" SG_ 2564485377 OBDx_MO_01_Resp_Data 3;
BA_ "GenSigFuncType" SG_ 2564485377 OBDx_MO_01_Resp_Data 9;
BA_ "GenSigSwitchedByIgnition" SG_ 2564485377 OBDx_MO_01_Resp_Data 0;
BA_ "GenSigSendType" SG_ 2564428017 OBDx_RSG_Req_Data 3;
BA_ "GenSigFuncType" SG_ 2564428017 OBDx_RSG_Req_Data 9;
BA_ "GenSigSwitchedByIgnition" SG_ 2564428017 OBDx_RSG_Req_Data 0;
BA_ "GenSigSendType" SG_ 2564485392 OBDx_RSG_Resp_Data 3;
BA_ "GenSigFuncType" SG_ 2564485392 OBDx_RSG_Resp_Data 9;
BA_ "GenSigSwitchedByIgnition" SG_ 2564485392 OBDx_RSG_Resp_Data 0;
BA_ "GenSigSendType" SG_ 2463978776 HVLE_AnzahlVerwendeterPhasen 0;
BA_ "GenSigSwitchedByIgnition" SG_ 2463978776 HVLE_AnzahlVerwendeterPhasen 0;
BA_ "Fehlerwert" SG_ 2463978776 HVLE_AnzahlVerwendeterPhasen 3;
BA_ "GenSigSendType" SG_ 2463978776 HVLE_AsymmetrischLadenMoeglich 0;
BA_ "GenSigSwitchedByIgnition" SG_ 2463978776 HVLE_AsymmetrischLadenMoeglich 0;
BA_ "GenSigSendType" SG_ 2463978776 HVLE_Derating_Temperatur 0;
BA_ "GenSigSwitchedByIgnition" SG_ 2463978776 HVLE_Derating_Temperatur 0;
BA_ "GenSigSendType" SG_ 2463978776 HVLE_Energiemenge_Laden 0;
BA_ "GenSigSwitchedByIgnition" SG_ 2463978776 HVLE_Energiemenge_Laden 0;
BA_ "GenSigSendType" SG_ 2463978776 HVLE_I_istAC_Netz_L1 0;
BA_ "GenSigStartValue" SG_ 2463978776 HVLE_I_istAC_Netz_L1 510;
BA_ "GenSigSwitchedByIgnition" SG_ 2463978776 HVLE_I_istAC_Netz_L1 0;
BA_ "Fehlerwert" SG_ 2463978776 HVLE_I_istAC_Netz_L1 511;
BA_ "GenSigSendType" SG_ 2463978776 HVLE_I_istAC_Netz_L2 0;
BA_ "GenSigStartValue" SG_ 2463978776 HVLE_I_istAC_Netz_L2 510;
BA_ "GenSigSwitchedByIgnition" SG_ 2463978776 HVLE_I_istAC_Netz_L2 0;
BA_ "Fehlerwert" SG_ 2463978776 HVLE_I_istAC_Netz_L2 511;
BA_ "GenSigSendType" SG_ 2463978776 HVLE_I_istAC_Netz_L3 0;
BA_ "GenSigStartValue" SG_ 2463978776 HVLE_I_istAC_Netz_L3 510;
BA_ "GenSigSwitchedByIgnition" SG_ 2463978776 HVLE_I_istAC_Netz_L3 0;
BA_ "Fehlerwert" SG_ 2463978776 HVLE_I_istAC_Netz_L3 511;
BA_ "GenSigSendType" SG_ 2463978776 HVLE_Ist_Wirkungsgrad 0;
BA_ "GenSigStartValue" SG_ 2463978776 HVLE_Ist_Wirkungsgrad 126;
BA_ "GenSigSwitchedByIgnition" SG_ 2463978776 HVLE_Ist_Wirkungsgrad 0;
BA_ "Fehlerwert" SG_ 2463978776 HVLE_Ist_Wirkungsgrad 127;
BA_ "GenSigSendType" SG_ 2463978776 HVLE_IstSpannung_HV 0;
BA_ "GenSigStartValue" SG_ 2463978776 HVLE_IstSpannung_HV 1022;
BA_ "GenSigSwitchedByIgnition" SG_ 2463978776 HVLE_IstSpannung_HV 0;
BA_ "Fehlerwert" SG_ 2463978776 HVLE_IstSpannung_HV 1023;
BA_ "GenSigSendType" SG_ 2463978776 HVLE_Netzfrequenz_EVU 0;
BA_ "GenSigStartValue" SG_ 2463978776 HVLE_Netzfrequenz_EVU 510;
BA_ "GenSigSwitchedByIgnition" SG_ 2463978776 HVLE_Netzfrequenz_EVU 0;
BA_ "Fehlerwert" SG_ 2463978776 HVLE_Netzfrequenz_EVU 511;
BA_ "GenSigSendType" SG_ 2463978776 HVLE_Netzmodus 0;
BA_ "GenSigSwitchedByIgnition" SG_ 2463978776 HVLE_Netzmodus 0;
BA_ "Fehlerwert" SG_ 2463978776 HVLE_Netzmodus 15;
BA_ "GenSigSendType" SG_ 2463978776 HVLE_OBG_AC_maxSpannung 0;
BA_ "GenSigStartValue" SG_ 2463978776 HVLE_OBG_AC_maxSpannung 1022;
BA_ "GenSigSwitchedByIgnition" SG_ 2463978776 HVLE_OBG_AC_maxSpannung 0;
BA_ "Fehlerwert" SG_ 2463978776 HVLE_OBG_AC_maxSpannung 1023;
BA_ "GenSigSendType" SG_ 2463978776 HVLE_OBG_AC_maxStrom 0;
BA_ "GenSigStartValue" SG_ 2463978776 HVLE_OBG_AC_maxStrom 1022;
BA_ "GenSigSwitchedByIgnition" SG_ 2463978776 HVLE_OBG_AC_maxStrom 0;
BA_ "Fehlerwert" SG_ 2463978776 HVLE_OBG_AC_maxStrom 1023;
BA_ "GenSigSendType" SG_ 2463978776 HVLE_OBG_ACDC_IstLeistung 0;
BA_ "GenSigStartValue" SG_ 2463978776 HVLE_OBG_ACDC_IstLeistung 2046;
BA_ "GenSigSwitchedByIgnition" SG_ 2463978776 HVLE_OBG_ACDC_IstLeistung 0;
BA_ "Fehlerwert" SG_ 2463978776 HVLE_OBG_ACDC_IstLeistung 2047;
BA_ "GenSigSendType" SG_ 2463978776 HVLE_OBG_ACDC_MaxLeistung 0;
BA_ "GenSigStartValue" SG_ 2463978776 HVLE_OBG_ACDC_MaxLeistung 2046;
BA_ "GenSigSwitchedByIgnition" SG_ 2463978776 HVLE_OBG_ACDC_MaxLeistung 0;
BA_ "Fehlerwert" SG_ 2463978776 HVLE_OBG_ACDC_MaxLeistung 2047;
BA_ "GenSigSendType" SG_ 2463978776 HVLE_OBG_DC_IstStrom 0;
BA_ "GenSigStartValue" SG_ 2463978776 HVLE_OBG_DC_IstStrom 2046;
BA_ "GenSigSwitchedByIgnition" SG_ 2463978776 HVLE_OBG_DC_IstStrom 0;
BA_ "Fehlerwert" SG_ 2463978776 HVLE_OBG_DC_IstStrom 2047;
BA_ "GenSigSendType" SG_ 2463978776 HVLE_OBG_DC_MaxStrom 0;
BA_ "GenSigStartValue" SG_ 2463978776 HVLE_OBG_DC_MaxStrom 2046;
BA_ "GenSigSwitchedByIgnition" SG_ 2463978776 HVLE_OBG_DC_MaxStrom 0;
BA_ "Fehlerwert" SG_ 2463978776 HVLE_OBG_DC_MaxStrom 2047;
BA_ "GenSigSendType" SG_ 2463978776 HVLE_OBG_Fehlerstatus 0;
BA_ "GenSigSwitchedByIgnition" SG_ 2463978776 HVLE_OBG_Fehlerstatus 0;
BA_ "GenSigSendType" SG_ 2463978776 HVLE_OBG_Fehlerstrom 0;
BA_ "GenSigSwitchedByIgnition" SG_ 2463978776 HVLE_OBG_Fehlerstrom 0;
BA_ "GenSigSendType" SG_ 2463978776 HVLE_OBG_IstModus 0;
BA_ "GenSigStartValue" SG_ 2463978776 HVLE_OBG_IstModus 6;
BA_ "GenSigSwitchedByIgnition" SG_ 2463978776 HVLE_OBG_IstModus 0;
BA_ "Fehlerwert" SG_ 2463978776 HVLE_OBG_IstModus 7;
BA_ "GenSigSendType" SG_ 2463978776 HVLE_OBG_Kuehltemperatur 0;
BA_ "GenSigStartValue" SG_ 2463978776 HVLE_OBG_Kuehltemperatur 254;
BA_ "GenSigSwitchedByIgnition" SG_ 2463978776 HVLE_OBG_Kuehltemperatur 0;
BA_ "Fehlerwert" SG_ 2463978776 HVLE_OBG_Kuehltemperatur 255;
BA_ "GenSigSendType" SG_ 2463978776 HVLE_OBG_Status_EoHVL 0;
BA_ "GenSigSwitchedByIgnition" SG_ 2463978776 HVLE_OBG_Status_EoHVL 0;
BA_ "Fehlerwert" SG_ 2463978776 HVLE_OBG_Status_EoHVL 3;
BA_ "GenSigSendType" SG_ 2463978776 HVLE_OBG_Status_Spgfreiheit 0;
BA_ "GenSigSwitchedByIgnition" SG_ 2463978776 HVLE_OBG_Status_Spgfreiheit 0;
BA_ "Fehlerwert" SG_ 2463978776 HVLE_OBG_Status_Spgfreiheit 3;
BA_ "GenSigSendType" SG_ 2463978776 HVLE_OBG_Typ_verbaut 0;
BA_ "GenSigStartValue" SG_ 2463978776 HVLE_OBG_Typ_verbaut 7;
BA_ "GenSigSwitchedByIgnition" SG_ 2463978776 HVLE_OBG_Typ_verbaut 0;
BA_ "GenSigSendType" SG_ 2463978776 HVLE_OBG_Warnzustand 0;
BA_ "GenSigSwitchedByIgnition" SG_ 2463978776 HVLE_OBG_Warnzustand 0;
BA_ "GenSigSendType" SG_ 2463978776 HVLE_PE_Monitor 0;
BA_ "GenSigSwitchedByIgnition" SG_ 2463978776 HVLE_PE_Monitor 0;
BA_ "Fehlerwert" SG_ 2463978776 HVLE_PE_Monitor 7;
BA_ "GenSigSendType" SG_ 2463978776 HVLE_U_istAC_Netz_L1 0;
BA_ "GenSigStartValue" SG_ 2463978776 HVLE_U_istAC_Netz_L1 510;
BA_ "GenSigSwitchedByIgnition" SG_ 2463978776 HVLE_U_istAC_Netz_L1 0;
BA_ "Fehlerwert" SG_ 2463978776 HVLE_U_istAC_Netz_L1 511;
BA_ "GenSigSendType" SG_ 2463978776 HVLE_U_istAC_Netz_L2 0;
BA_ "GenSigStartValue" SG_ 2463978776 HVLE_U_istAC_Netz_L2 510;
BA_ "GenSigSwitchedByIgnition" SG_ 2463978776 HVLE_U_istAC_Netz_L2 0;
BA_ "Fehlerwert" SG_ 2463978776 HVLE_U_istAC_Netz_L2 511;
BA_ "GenSigSendType" SG_ 2463978776 HVLE_U_istAC_Netz_L3 0;
BA_ "GenSigStartValue" SG_ 2463978776 HVLE_U_istAC_Netz_L3 510;
BA_ "GenSigSwitchedByIgnition" SG_ 2463978776 HVLE_U_istAC_Netz_L3 0;
BA_ "Fehlerwert" SG_ 2463978776 HVLE_U_istAC_Netz_L3 511;
BA_ "GenSigSendType" SG_ 2463978776 OBG_01_BZ 0;
BA_ "GenSigFuncType" SG_ 2463978776 OBG_01_BZ 1;
BA_ "GenSigSwitchedByIgnition" SG_ 2463978776 OBG_01_BZ 0;
BA_ "GenSigSendType" SG_ 2463978776 OBG_01_CRC 0;
BA_ "GenSigFuncType" SG_ 2463978776 OBG_01_CRC 2;
BA_ "GenSigSwitchedByIgnition" SG_ 2463978776 OBG_01_CRC 0;
BA_ "GenSigSendType" SG_ 2463978776 SOK_OBG_01_Signatur 0;
BA_ "GenSigFuncType" SG_ 2463978776 SOK_OBG_01_Signatur 15;
BA_ "GenSigSwitchedByIgnition" SG_ 2463978776 SOK_OBG_01_Signatur 0;
BA_ "GenSigSendType" SG_ 2589284143 OBMI_DDrvRngRem 0;
BA_ "GenSigStartValue" SG_ 2589284143 OBMI_DDrvRngRem 8190;
BA_ "GenSigSwitchedByIgnition" SG_ 2589284143 OBMI_DDrvRngRem 0;
BA_ "GenSigSendType" SG_ 2589284143 OBMI_FlgTrig 0;
BA_ "GenSigSwitchedByIgnition" SG_ 2589284143 OBMI_FlgTrig 0;
BA_ "GenSigSendType" SG_ 2589284143 OBMI_StAct 0;
BA_ "GenSigSwitchedByIgnition" SG_ 2589284143 OBMI_StAct 0;
BA_ "GenSigSendType" SG_ 2589284143 OBMI_StDrvRngUnit 0;
BA_ "GenSigSwitchedByIgnition" SG_ 2589284143 OBMI_StDrvRngUnit 0;
BA_ "GenSigSendType" SG_ 2589283656 ORU_Status 3;
BA_ "GenSigSwitchedByIgnition" SG_ 2589283656 ORU_Status 0;
BA_ "GenSigSendType" SG_ 2589283656 ORU_Warnung 3;
BA_ "GenSigSwitchedByIgnition" SG_ 2589283656 ORU_Warnung 0;
BA_ "GenSigSendType" SG_ 518 IPA_TPA_Abbruch 0;
BA_ "GenSigSwitchedByIgnition" SG_ 518 IPA_TPA_Abbruch 0;
BA_ "GenSigSendType" SG_ 518 IPA_TPA_ausgerichtetes_Parken 0;
BA_ "GenSigSwitchedByIgnition" SG_ 518 IPA_TPA_ausgerichtetes_Parken 0;
BA_ "GenSigSendType" SG_ 518 IPA_TPA_Fehler 0;
BA_ "GenSigSwitchedByIgnition" SG_ 518 IPA_TPA_Fehler 0;
BA_ "GenSigSendType" SG_ 518 IPA_TPA_Remote 0;
BA_ "GenSigSwitchedByIgnition" SG_ 518 IPA_TPA_Remote 0;
BA_ "GenSigSendType" SG_ 518 IPA_TPA_Remote_Anf 0;
BA_ "GenSigSwitchedByIgnition" SG_ 518 IPA_TPA_Remote_Anf 0;
BA_ "GenSigSendType" SG_ 518 IPA_TPA_Status 0;
BA_ "GenSigStartValue" SG_ 518 IPA_TPA_Status 1;
BA_ "GenSigSwitchedByIgnition" SG_ 518 IPA_TPA_Status 0;
BA_ "GenSigSendType" SG_ 518 Parken_01_BZ 0;
BA_ "GenSigFuncType" SG_ 518 Parken_01_BZ 1;
BA_ "GenSigSwitchedByIgnition" SG_ 518 Parken_01_BZ 0;
BA_ "GenSigSendType" SG_ 518 Parken_01_CRC 0;
BA_ "GenSigFuncType" SG_ 518 Parken_01_CRC 2;
BA_ "GenSigSwitchedByIgnition" SG_ 518 Parken_01_CRC 0;
BA_ "GenSigSendType" SG_ 518 Parken_aktives_System 0;
BA_ "GenSigSendType" SG_ 518 Parken_Anforderung_HMS 0;
BA_ "GenSigSwitchedByIgnition" SG_ 518 Parken_Anforderung_HMS 0;
BA_ "GenSigSendType" SG_ 518 Parken_Anhalteweg_Anf 0;
BA_ "GenSigStartValue" SG_ 518 Parken_Anhalteweg_Anf 1022;
BA_ "GenSigSwitchedByIgnition" SG_ 518 Parken_Anhalteweg_Anf 0;
BA_ "Fehlerwert" SG_ 518 Parken_Anhalteweg_Anf 1023;
BA_ "GenSigSendType" SG_ 518 Parken_beibehalten 0;
BA_ "GenSigStartValue" SG_ 518 Parken_beibehalten 2;
BA_ "GenSigSwitchedByIgnition" SG_ 518 Parken_beibehalten 0;
BA_ "Fehlerwert" SG_ 518 Parken_beibehalten 3;
BA_ "GenSigSendType" SG_ 518 Parken_BKD_Anf 0;
BA_ "GenSigStartValue" SG_ 518 Parken_BKD_Anf 14;
BA_ "GenSigSwitchedByIgnition" SG_ 518 Parken_BKD_Anf 0;
BA_ "Fehlerwert" SG_ 518 Parken_BKD_Anf 15;
BA_ "GenSigSendType" SG_ 518 Parken_Bordstein_Winkel 0;
BA_ "GenSigSwitchedByIgnition" SG_ 518 Parken_Bordstein_Winkel 0;
BA_ "GenSigSendType" SG_ 518 Parken_erhoehtes_Moment 0;
BA_ "GenSigSwitchedByIgnition" SG_ 518 Parken_erhoehtes_Moment 0;
BA_ "GenSigSendType" SG_ 518 Parken_Fahrbereitschaft_Anf 0;
BA_ "GenSigSendType" SG_ 518 Parken_Fahrstufenwunsch 0;
BA_ "GenSigSendType" SG_ 518 Parken_max_Beschleunigung 0;
BA_ "GenSigStartValue" SG_ 518 Parken_max_Beschleunigung 122;
BA_ "GenSigSwitchedByIgnition" SG_ 518 Parken_max_Beschleunigung 0;
BA_ "Fehlerwert" SG_ 518 Parken_max_Beschleunigung 127;
BA_ "GenSigSendType" SG_ 518 Parken_max_Geschwindigkeit 0;
BA_ "GenSigStartValue" SG_ 518 Parken_max_Geschwindigkeit 251;
BA_ "GenSigSwitchedByIgnition" SG_ 518 Parken_max_Geschwindigkeit 0;
BA_ "Fehlerwert" SG_ 518 Parken_max_Geschwindigkeit 255;
BA_ "GenSigSendType" SG_ 518 Parken_Motorlauf_Anf 0;
BA_ "GenSigSendType" SG_ 518 Parken_Notstopp_Anf 0;
BA_ "GenSigSwitchedByIgnition" SG_ 518 Parken_Notstopp_Anf 0;
BA_ "GenSigSendType" SG_ 518 Parken_Prefill_Anf 0;
BA_ "GenSigSwitchedByIgnition" SG_ 518 Parken_Prefill_Anf 0;
BA_ "GenSigSendType" SG_ 518 Parken_QFK_AnfStat 0;
BA_ "GenSigStartValue" SG_ 518 Parken_QFK_AnfStat 1;
BA_ "GenSigSendType" SG_ 518 Parken_QFK_Art1 0;
BA_ "GenSigSendType" SG_ 518 Parken_QFK_Art2 0;
BA_ "GenSigSendType" SG_ 518 Parken_QFK_KruemmSoll 0;
BA_ "GenSigSendType" SG_ 518 Parken_QFK_KruemmSoll_VZ 0;
BA_ "GenSigSendType" SG_ 518 Parken_QFK_Signal1 0;
BA_ "GenSigSendType" SG_ 518 Parken_QFK_Signal2 0;
BA_ "GenSigSendType" SG_ 518 Parken_QFK_Spuerb 0;
BA_ "GenSigSendType" SG_ 518 Parken_Schleichfahrt_Anf 0;
BA_ "GenSigSendType" SG_ 518 Parken_Soll_Anhalteweg_Anf 0;
BA_ "GenSigStartValue" SG_ 518 Parken_Soll_Anhalteweg_Anf 1022;
BA_ "GenSigSwitchedByIgnition" SG_ 518 Parken_Soll_Anhalteweg_Anf 0;
BA_ "Fehlerwert" SG_ 518 Parken_Soll_Anhalteweg_Anf 1023;
BA_ "GenSigSendType" SG_ 518 Parken_Sollbeschleunigung 0;
BA_ "GenSigSendType" SG_ 518 Parken_Status_IPA_TSK 0;
BA_ "GenSigStartValue" SG_ 518 Parken_Status_IPA_TSK 1;
BA_ "GenSigSwitchedByIgnition" SG_ 518 Parken_Status_IPA_TSK 0;
BA_ "GenSigSendType" SG_ 518 Parken_Verz_Anf 0;
BA_ "GenSigStartValue" SG_ 518 Parken_Verz_Anf 126;
BA_ "GenSigSwitchedByIgnition" SG_ 518 Parken_Verz_Anf 0;
BA_ "GenSigSendType" SG_ 518 Parken_Verz_Anf_ASIL 0;
BA_ "GenSigSwitchedByIgnition" SG_ 518 Parken_Verz_Anf_ASIL 0;
BA_ "GenSigSendType" SG_ 518 Parken_Warnruck_Anf 0;
BA_ "GenSigSwitchedByIgnition" SG_ 518 Parken_Warnruck_Anf 0;
BA_ "GenSigSendType" SG_ 518 Parken_Warnruckeln_Anf 0;
BA_ "GenSigSwitchedByIgnition" SG_ 518 Parken_Warnruckeln_Anf 0;
BA_ "GenSigSendType" SG_ 1175 PDC_Tonausgabe_Front 3;
BA_ "GenSigSendType" SG_ 1175 PDC_Tonausgabe_Heck 3;
BA_ "GenSigSendType" SG_ 1175 PH_Abschaltursache 3;
BA_ "GenSigSendType" SG_ 1175 PH_Anf_Audioabsenkung 3;
BA_ "GenSigSendType" SG_ 1175 PH_Anf_Verdeck 3;
BA_ "GenSigSendType" SG_ 1175 PH_defekt 3;
BA_ "GenSigSendType" SG_ 1175 PH_Display_Kundenwunsch 3;
BA_ "GenSigSendType" SG_ 1175 PH_Frequenz_hinten 3;
BA_ "GenSigSendType" SG_ 1175 PH_Frequenz_vorn 3;
BA_ "GenSigSendType" SG_ 1175 PH_gestoert 3;
BA_ "GenSigSendType" SG_ 1175 PH_Lautstaerke_hinten 3;
BA_ "GenSigSendType" SG_ 1175 PH_Lautstaerke_vorn 3;
BA_ "GenSigSendType" SG_ 1175 PH_nachtr_Stopp_Anf 3;
BA_ "GenSigSendType" SG_ 1175 PH_Opt_Anz_H_Hindernis 3;
BA_ "GenSigSendType" SG_ 1175 PH_Opt_Anz_V_Hindernis 3;
BA_ "GenSigSendType" SG_ 1175 PH_Opt_Anzeige_H_ein 3;
BA_ "GenSigSendType" SG_ 1175 PH_Opt_Anzeige_V_ein 3;
BA_ "GenSigSendType" SG_ 1175 PH_StartStopp_Info 3;
BA_ "GenSigSendType" SG_ 1175 PH_Stoermeldung 3;
BA_ "GenSigSendType" SG_ 1175 PH_Systemzustand 3;
BA_ "GenSigSendType" SG_ 1175 PH_Taster 3;
BA_ "Fehlerwert" SG_ 1175 PH_Taster 3;
BA_ "GenSigSendType" SG_ 1175 PH_Tongeber_H_aktiv 3;
BA_ "GenSigSendType" SG_ 1175 PH_Tongeber_H_verfuegbar 3;
BA_ "GenSigSendType" SG_ 1175 PH_Tongeber_mute 3;
BA_ "GenSigSendType" SG_ 1175 PH_Tongeber_V_aktiv 3;
BA_ "GenSigSendType" SG_ 1175 PH_Visualisierung 3;
BA_ "GenSigStartValue" SG_ 1175 PH_Visualisierung 6;
BA_ "Fehlerwert" SG_ 1175 PH_Visualisierung 7;
BA_ "GenSigSendType" SG_ 1175 PLA_Anf_Aufschaltung_RVC 3;
BA_ "GenSigSendType" SG_ 1122 PSD_Abzweigerichtung 0;
BA_ "GenSigSwitchedByIgnition" SG_ 1122 PSD_Abzweigerichtung 0;
BA_ "GenSigSendType" SG_ 1122 PSD_Abzweigewinkel 0;
BA_ "GenSigSwitchedByIgnition" SG_ 1122 PSD_Abzweigewinkel 0;
BA_ "GenSigSendType" SG_ 1122 PSD_ADAS_Qualitaet 0;
BA_ "GenSigSendType" SG_ 1122 PSD_Anfangskruemmung 0;
BA_ "GenSigSwitchedByIgnition" SG_ 1122 PSD_Anfangskruemmung 0;
BA_ "GenSigSendType" SG_ 1122 PSD_Anfangskruemmung_Vorz 0;
BA_ "GenSigSwitchedByIgnition" SG_ 1122 PSD_Anfangskruemmung_Vorz 0;
BA_ "GenSigSendType" SG_ 1122 PSD_Bebauung 0;
BA_ "GenSigSendType" SG_ 1122 PSD_Endkruemmung 0;
BA_ "GenSigSendType" SG_ 1122 PSD_Endkruemmung_Vorz 0;
BA_ "GenSigSendType" SG_ 1122 PSD_Fahrspuren_Anzahl 0;
BA_ "GenSigStartValue" SG_ 1122 PSD_Fahrspuren_Anzahl 1;
BA_ "GenSigSwitchedByIgnition" SG_ 1122 PSD_Fahrspuren_Anzahl 0;
BA_ "GenSigSendType" SG_ 1122 PSD_Geradester_Pfad 0;
BA_ "GenSigSendType" SG_ 1122 PSD_Idenditaets_ID 0;
BA_ "Fehlerwert" SG_ 1122 PSD_Idenditaets_ID 1;
BA_ "GenSigSendType" SG_ 1122 PSD_Rampe 0;
BA_ "GenSigSendType" SG_ 1122 PSD_Segment_ID 0;
BA_ "GenSigSendType" SG_ 1122 PSD_Segment_Komplett 0;
BA_ "GenSigSwitchedByIgnition" SG_ 1122 PSD_Segment_Komplett 0;
BA_ "GenSigSendType" SG_ 1122 PSD_Segmentlaenge 0;
BA_ "GenSigSendType" SG_ 1122 PSD_Strassenkategorie 0;
BA_ "GenSigStartValue" SG_ 1122 PSD_Strassenkategorie 7;
BA_ "GenSigSwitchedByIgnition" SG_ 1122 PSD_Strassenkategorie 0;
BA_ "GenSigSendType" SG_ 1122 PSD_Vorgaenger_Segment_ID 0;
BA_ "GenSigSendType" SG_ 1122 PSD_wahrscheinlichster_Pfad 0;
BA_ "GenSigSendType" SG_ 1123 PSD_Attribut_1_ID 0;
BA_ "GenSigSendType" SG_ 1123 PSD_Attribut_1_Offset 0;
BA_ "GenSigSendType" SG_ 1123 PSD_Attribut_1_Wert 0;
BA_ "GenSigSendType" SG_ 1123 PSD_Attribut_2_ID 0;
BA_ "GenSigSendType" SG_ 1123 PSD_Attribut_2_Offset 0;
BA_ "GenSigSendType" SG_ 1123 PSD_Attribut_2_Wert 0;
BA_ "GenSigSendType" SG_ 1123 PSD_Attribut_Segment_ID_05 0;
BA_ "Fehlerwert" SG_ 1123 PSD_Attribut_Segment_ID_05 1;
BA_ "GenSigSendType" SG_ 1123 PSD_Attribute_Komplett_05 0;
BA_ "GenSigSendType" SG_ 1123 PSD_Pos_Fahrspur 0;
BA_ "GenSigSendType" SG_ 1123 PSD_Pos_Fehler_Laengsrichtung 0;
BA_ "GenSigSendType" SG_ 1123 PSD_Pos_Inhibitzeit 0;
BA_ "GenSigSendType" SG_ 1123 PSD_Pos_Segment_ID 0;
BA_ "GenSigSendType" SG_ 1123 PSD_Pos_Segmentlaenge 0;
BA_ "GenSigSendType" SG_ 1123 PSD_Pos_Standort_Eindeutig 0;
BA_ "GenSigSwitchedByIgnition" SG_ 1123 PSD_Pos_Standort_Eindeutig 0;
BA_ "GenSigSendType" SG_ 1124 PSD_06_Mux 0;
BA_ "NWM-WakeupAllowed" SG_ 1124 PSD_06_Mux 1;
BA_ "GenSigSwitchedByIgnition" SG_ 1124 PSD_06_Mux 0;
BA_ "Fehlerwert" SG_ 1124 PSD_Attribut_Segment_ID 1;
BA_ "GenSigSwitchedByIgnition" SG_ 1124 PSD_Attribute_Komplett_06 0;
BA_ "GenSigStartValue" SG_ 1124 PSD_Ges_Typ 3;
BA_ "GenSigSwitchedByIgnition" SG_ 1124 PSD_Ges_Typ 0;
BA_ "GenSigSwitchedByIgnition" SG_ 1124 PSD_Steigung_1_Attribute_kompl 0;
BA_ "Fehlerwert" SG_ 1124 PSD_Steigung_1_Segment_ID 1;
BA_ "GenSigSwitchedByIgnition" SG_ 1124 PSD_Steigung_2_Attribute_kompl 0;
BA_ "Fehlerwert" SG_ 1124 PSD_Steigung_2_Segment_ID 1;
BA_ "GenSigSendType" SG_ 1125 PSD_LR_01_MUX 0;
BA_ "GenSigSendType" SG_ 1125 PSD_LR_Profil_Nummer 0;
BA_ "GenSigSwitchedByIgnition" SG_ 1125 PSD_LR_Steigung_3_Vorz 0;
BA_REL_ "GenSigTimeoutTime" BU_SG_REL_ Gateway_Max SG_ 339 MO_HVEM_Eskalation 2000;
BA_REL_ "GenSigTimeoutTime" BU_SG_REL_ Gateway_Max SG_ 339 MO_HVEM_MaxLeistung 2000;
BA_REL_ "GenSigTimeoutTime" BU_SG_REL_ Gateway_Max SG_ 339 MO_MVK_Bordnetz_Anf 2000;
BA_REL_ "GenSigTimeoutTime" BU_SG_REL_ Gateway_Max SG_ 339 MO_MVK_EmFehlerstatus 2000;
BA_REL_ "GenSigTimeoutTime" BU_SG_REL_ Gateway_Max SG_ 339 MO_MVK_EmIstzustand 2000;
BA_REL_ "GenSigTimeoutTime" BU_SG_REL_ Gateway_Max SG_ 2600468599 NM_Getriebe_01_CBV_AWB 2000;
BA_REL_ "GenSigTimeoutTime" BU_SG_REL_ Gateway_Max SG_ 2600468599 NM_Getriebe_01_CBV_CRI 2000;
BA_REL_ "GenSigTimeoutTime" BU_SG_REL_ Gateway_Max SG_ 2600468599 NM_Getriebe_01_Car_Wakeup 2000;
BA_REL_ "GenSigTimeoutTime" BU_SG_REL_ Gateway_Max SG_ 2600468599 NM_Getriebe_01_CAB_V14 2000;
BA_REL_ "GenSigTimeoutTime" BU_SG_REL_ Gateway_Max SG_ 2600468598 NM_MO_01_CBV_AWB 2000;
BA_REL_ "GenSigTimeoutTime" BU_SG_REL_ Gateway_Max SG_ 2600468598 NM_MO_01_CBV_CRI 2000;
BA_REL_ "GenSigTimeoutTime" BU_SG_REL_ Gateway_Max SG_ 2600468598 NM_MO_01_Car_Wakeup 2000;
BA_REL_ "GenSigTimeoutTime" BU_SG_REL_ Gateway_Max SG_ 2600468598 NM_MO_01_CAB_V14 2000;
BA_REL_ "GenSigTimeoutTime" BU_SG_REL_ Gateway_Max SG_ 2600469458 NM_Parksperre_CBV_AWB 2000;
BA_REL_ "GenSigTimeoutTime" BU_SG_REL_ Gateway_Max SG_ 2600469458 NM_Parksperre_CBV_CRI 2000;
BA_REL_ "GenSigTimeoutTime" BU_SG_REL_ Gateway_Max SG_ 2600469458 NM_Parksperre_Car_Wakeup 2000;
BA_REL_ "GenSigTimeoutTime" BU_SG_REL_ Gateway_Max SG_ 2600469458 NM_Parksperre_CAB_V14 2000;
BA_REL_ "GenSigTimeoutTime" BU_SG_REL_ Gateway_Max SG_ 2600468733 NM_Waehlhebel_CBV_AWB 2000;
BA_REL_ "GenSigTimeoutTime" BU_SG_REL_ Gateway_Max SG_ 2600468733 NM_Waehlhebel_CBV_CRI 2000;
BA_REL_ "GenSigTimeoutTime" BU_SG_REL_ Gateway_Max SG_ 2600468733 NM_Waehlhebel_Car_Wakeup 2000;
BA_REL_ "GenSigTimeoutTime" BU_SG_REL_ Gateway_Max SG_ 2600468733 NM_Waehlhebel_CAB_V14 2000;
BA_REL_ "GenSigTimeoutTime" BU_SG_REL_ Getriebe_DQ SG_ 2600468496 NM_Gateway_NM_State 2000;
BA_REL_ "GenSigTimeoutTime" BU_SG_REL_ Getriebe_DQ SG_ 2600468598 NM_MO_01_NM_State 2000;
BA_REL_ "GenSigTimeoutTime" BU_SG_REL_ Getriebe_DQ SG_ 2600469458 NM_Parksperre_NM_State 2000;
BA_REL_ "GenSigTimeoutTime" BU_SG_REL_ Getriebe_DQ SG_ 2600468733 NM_Waehlhebel_NM_State 2000;
BA_REL_ "GenSigTimeoutTime" BU_SG_REL_ Getriebe_DQ SG_ 518 Parken_Status_IPA_TSK 500;
BA_REL_ "GenSigTimeoutTime" BU_SG_REL_ Motor_konv SG_ 931 MVEM_IstStrom_MVVerbraucher 1000;
BA_REL_ "GenSigTimeoutTime" BU_SG_REL_ Motor_konv SG_ 2589283456 MVEM_MO_USoll_Notbetrieb 5000;
BA_REL_ "GenSigTimeoutTime" BU_SG_REL_ Motor_konv SG_ 2463978719 MVEM_03_CRC 1000;
BA_REL_ "GenSigTimeoutTime" BU_SG_REL_ Motor_konv SG_ 2463978719 MVEM_03_BZ 1000;
BA_REL_ "GenSigTimeoutTime" BU_SG_REL_ Motor_konv SG_ 2463978719 MVEM_IstLeistung_MVVerbraucher 1000;
BA_REL_ "GenSigTimeoutTime" BU_SG_REL_ Motor_konv SG_ 2463978719 MVEM_Eskalation_Energieversorgun 1000;
BA_REL_ "GenSigTimeoutTime" BU_SG_REL_ Motor_konv SG_ 1284 MVK_MO_EmSollzustand 1000;
BA_REL_ "GenSigTimeoutTime" BU_SG_REL_ Motor_konv SG_ 2600468496 NM_Gateway_NM_State 2000;
BA_REL_ "GenSigTimeoutTime" BU_SG_REL_ Motor_konv SG_ 2600468599 NM_Getriebe_01_NM_State 2000;
BA_REL_ "GenSigTimeoutTime" BU_SG_REL_ Motor_konv SG_ 2600469458 NM_Parksperre_NM_State 2000;
BA_REL_ "GenSigTimeoutTime" BU_SG_REL_ Motor_konv SG_ 2600468733 NM_Waehlhebel_NM_State 2000;
BA_REL_ "GenSigTimeoutTime" BU_SG_REL_ Motor_konv SG_ 1630 OBD_TG_F_Status_1 5000;
BA_REL_ "GenSigTimeoutTime" BU_SG_REL_ Motor_konv SG_ 1630 OBD_TG_F_Status_2 5000;
BA_REL_ "GenSigTimeoutTime" BU_SG_REL_ Motor_konv SG_ 1630 OBD_TG_F_Status_3 5000;
BA_REL_ "GenSigTimeoutTime" BU_SG_REL_ Motor_konv SG_ 1630 OBD_TG_F_Status_4 5000;
BA_REL_ "GenSigTimeoutTime" BU_SG_REL_ Motor_konv SG_ 1630 OBD_TG_Sens_Rohwert_1 5000;
BA_REL_ "GenSigTimeoutTime" BU_SG_REL_ Motor_konv SG_ 1630 OBD_TG_Sens_Rohwert_2 5000;
BA_REL_ "GenSigTimeoutTime" BU_SG_REL_ Motor_konv SG_ 1630 OBD_TG_Sens_Rohwert_3 5000;
BA_REL_ "GenSigTimeoutTime" BU_SG_REL_ Motor_konv SG_ 1630 OBD_TG_Sens_Rohwert_4 5000;
BA_REL_ "GenSigTimeoutTime" BU_SG_REL_ Motor_konv SG_ 2589283656 ORU_Status 5000;
BA_REL_ "GenSigTimeoutTime" BU_SG_REL_ Motor_konv SG_ 518 Parken_01_CRC 500;
BA_REL_ "GenSigTimeoutTime" BU_SG_REL_ Motor_konv SG_ 518 Parken_01_BZ 500;
BA_REL_ "GenSigTimeoutTime" BU_SG_REL_ Motor_konv SG_ 518 Parken_Fahrbereitschaft_Anf 500;
BA_REL_ "GenSigTimeoutTime" BU_SG_REL_ Motor_konv SG_ 518 Parken_Motorlauf_Anf 500;
BA_REL_ "GenSigTimeoutTime" BU_SG_REL_ Motor_konv SG_ 518 Parken_aktives_System 500;
BA_REL_ "GenSigTimeoutTime" BU_SG_REL_ Motor_konv SG_ 518 Parken_max_Beschleunigung 500;
BA_REL_ "GenSigTimeoutTime" BU_SG_REL_ Motor_konv SG_ 518 Parken_Sollbeschleunigung 500;
BA_REL_ "GenSigTimeoutTime" BU_SG_REL_ Motor_konv SG_ 518 Parken_Status_IPA_TSK 500;
BA_REL_ "GenSigTimeoutTime" BU_SG_REL_ Motor_konv SG_ 518 Parken_erhoehtes_Moment 500;
BA_REL_ "GenSigTimeoutTime" BU_SG_REL_ Motor_konv SG_ 518 Parken_max_Geschwindigkeit 500;
BA_REL_ "GenSigTimeoutTime" BU_SG_REL_ Motor_konv SG_ 518 Parken_Bordstein_Winkel 500;
BA_REL_ "GenSigTimeoutTime" BU_SG_REL_ Motor_konv SG_ 1175 PH_nachtr_Stopp_Anf 1000;
BA_REL_ "GenSigTimeoutTime" BU_SG_REL_ Motor_konv SG_ 1175 PH_StartStopp_Info 1000;
BA_REL_ "GenSigTimeoutTime" BU_SG_REL_ Motor_konv SG_ 1122 PSD_Segment_ID 1500;
BA_REL_ "GenSigTimeoutTime" BU_SG_REL_ Motor_konv SG_ 1122 PSD_Vorgaenger_Segment_ID 1500;
BA_REL_ "GenSigTimeoutTime" BU_SG_REL_ Motor_konv SG_ 1122 PSD_Segmentlaenge 1500;
BA_REL_ "GenSigTimeoutTime" BU_SG_REL_ Motor_konv SG_ 1122 PSD_Strassenkategorie 1500;
BA_REL_ "GenSigTimeoutTime" BU_SG_REL_ Motor_konv SG_ 1122 PSD_Endkruemmung 1500;
BA_REL_ "GenSigTimeoutTime" BU_SG_REL_ Motor_konv SG_ 1122 PSD_Endkruemmung_Vorz 1500;
BA_REL_ "GenSigTimeoutTime" BU_SG_REL_ Motor_konv SG_ 1122 PSD_Idenditaets_ID 1500;
BA_REL_ "GenSigTimeoutTime" BU_SG_REL_ Motor_konv SG_ 1122 PSD_ADAS_Qualitaet 1500;
BA_REL_ "GenSigTimeoutTime" BU_SG_REL_ Motor_konv SG_ 1122 PSD_wahrscheinlichster_Pfad 1500;
BA_REL_ "GenSigTimeoutTime" BU_SG_REL_ Motor_konv SG_ 1122 PSD_Geradester_Pfad 1500;
BA_REL_ "GenSigTimeoutTime" BU_SG_REL_ Motor_konv SG_ 1122 PSD_Fahrspuren_Anzahl 1500;
BA_REL_ "GenSigTimeoutTime" BU_SG_REL_ Motor_konv SG_ 1122 PSD_Bebauung 1500;
BA_REL_ "GenSigTimeoutTime" BU_SG_REL_ Motor_konv SG_ 1122 PSD_Segment_Komplett 1500;
BA_REL_ "GenSigTimeoutTime" BU_SG_REL_ Motor_konv SG_ 1122 PSD_Rampe 1500;
BA_REL_ "GenSigTimeoutTime" BU_SG_REL_ Motor_konv SG_ 1122 PSD_Anfangskruemmung 1500;
BA_REL_ "GenSigTimeoutTime" BU_SG_REL_ Motor_konv SG_ 1122 PSD_Anfangskruemmung_Vorz 1500;
BA_REL_ "GenSigTimeoutTime" BU_SG_REL_ Motor_konv SG_ 1122 PSD_Abzweigerichtung 1500;
BA_REL_ "GenSigTimeoutTime" BU_SG_REL_ Motor_konv SG_ 1122 PSD_Abzweigewinkel 1500;
BA_REL_ "GenSigTimeoutTime" BU_SG_REL_ Motor_konv SG_ 1123 PSD_Pos_Segment_ID 1500;
BA_REL_ "GenSigTimeoutTime" BU_SG_REL_ Motor_konv SG_ 1123 PSD_Pos_Segmentlaenge 1500;
BA_REL_ "GenSigTimeoutTime" BU_SG_REL_ Motor_konv SG_ 1123 PSD_Pos_Inhibitzeit 1500;
BA_REL_ "GenSigTimeoutTime" BU_SG_REL_ Motor_konv SG_ 1123 PSD_Pos_Standort_Eindeutig 1500;
BA_REL_ "GenSigTimeoutTime" BU_SG_REL_ Motor_konv SG_ 1123 PSD_Pos_Fehler_Laengsrichtung 1500;
BA_REL_ "GenSigTimeoutTime" BU_SG_REL_ Motor_konv SG_ 1123 PSD_Pos_Fahrspur 1500;
BA_REL_ "GenSigTimeoutTime" BU_SG_REL_ Motor_konv SG_ 1123 PSD_Attribut_Segment_ID_05 1500;
BA_REL_ "GenSigTimeoutTime" BU_SG_REL_ Motor_konv SG_ 1123 PSD_Attribut_1_ID 1500;
BA_REL_ "GenSigTimeoutTime" BU_SG_REL_ Motor_konv SG_ 1123 PSD_Attribut_1_Wert 1500;
BA_REL_ "GenSigTimeoutTime" BU_SG_REL_ Motor_konv SG_ 1123 PSD_Attribut_1_Offset 1500;
BA_REL_ "GenSigTimeoutTime" BU_SG_REL_ Motor_konv SG_ 1123 PSD_Attribut_2_ID 1500;
BA_REL_ "GenSigTimeoutTime" BU_SG_REL_ Motor_konv SG_ 1123 PSD_Attribut_2_Wert 1500;
BA_REL_ "GenSigTimeoutTime" BU_SG_REL_ Motor_konv SG_ 1123 PSD_Attribut_2_Offset 1500;
BA_REL_ "GenSigTimeoutTime" BU_SG_REL_ Motor_konv SG_ 1123 PSD_Attribute_Komplett_05 1500;
BA_REL_ "GenSigTimeoutTime" BU_SG_REL_ Motor_konv SG_ 1124 PSD_06_Mux 1500;
BA_REL_ "GenSigTimeoutTime" BU_SG_REL_ Motor_konv SG_ 1124 PSD_Sys_Segment_ID 1500;
BA_REL_ "GenSigTimeoutTime" BU_SG_REL_ Motor_konv SG_ 1124 PSD_Attribut_Segment_ID 1500;
BA_REL_ "GenSigTimeoutTime" BU_SG_REL_ Motor_konv SG_ 1124 PSD_Ges_Segment_ID 1500;
BA_REL_ "GenSigTimeoutTime" BU_SG_REL_ Motor_konv SG_ 1124 PSD_Baum_Laenge_VZ 1500;
BA_REL_ "GenSigTimeoutTime" BU_SG_REL_ Motor_konv SG_ 1124 PSD_Steigung_1_Segment_ID 1500;
BA_REL_ "GenSigTimeoutTime" BU_SG_REL_ Motor_konv SG_ 1124 PSD_Baum_Laenge 1500;
BA_REL_ "GenSigTimeoutTime" BU_SG_REL_ Motor_konv SG_ 1124 PSD_Sys_Laendercode 1500;
BA_REL_ "GenSigTimeoutTime" BU_SG_REL_ Motor_konv SG_ 1124 PSD_Attribut_3_ID 1500;
BA_REL_ "GenSigTimeoutTime" BU_SG_REL_ Motor_konv SG_ 1124 PSD_Ges_Offset 1500;
BA_REL_ "GenSigTimeoutTime" BU_SG_REL_ Motor_konv SG_ 1124 PSD_Steigung_1_A_Steigung 1500;
BA_REL_ "GenSigTimeoutTime" BU_SG_REL_ Motor_konv SG_ 1124 PSD_Attribut_3_Offset 1500;
BA_REL_ "GenSigTimeoutTime" BU_SG_REL_ Motor_konv SG_ 1124 PSD_Ges_Geschwindigkeit 1500;
BA_REL_ "GenSigTimeoutTime" BU_SG_REL_ Motor_konv SG_ 1124 PSD_Steigung_1_A_Vorz 1500;
BA_REL_ "GenSigTimeoutTime" BU_SG_REL_ Motor_konv SG_ 1124 PSD_Sys_Geschwindigkeit_Einheit 1500;
BA_REL_ "GenSigTimeoutTime" BU_SG_REL_ Motor_konv SG_ 1124 PSD_Steigung_1_A_Offset 1500;
BA_REL_ "GenSigTimeoutTime" BU_SG_REL_ Motor_konv SG_ 1124 PSD_Sys_Verkehrsrichtung 1500;
BA_REL_ "GenSigTimeoutTime" BU_SG_REL_ Motor_konv SG_ 1124 PSD_Sys_Geometrieguete 1500;
BA_REL_ "GenSigTimeoutTime" BU_SG_REL_ Motor_konv SG_ 1124 PSD_Sys_Mapmatchingguete 1500;
BA_REL_ "GenSigTimeoutTime" BU_SG_REL_ Motor_konv SG_ 1124 PSD_Attribut_3_Wert 1500;
BA_REL_ "GenSigTimeoutTime" BU_SG_REL_ Motor_konv SG_ 1124 PSD_Ges_Typ 1500;
BA_REL_ "GenSigTimeoutTime" BU_SG_REL_ Motor_konv SG_ 1124 PSD_Sys_Alter_Karte 1500;
BA_REL_ "GenSigTimeoutTime" BU_SG_REL_ Motor_konv SG_ 1124 PSD_Ges_Spur_Geschw_Begrenzung 1500;
BA_REL_ "GenSigTimeoutTime" BU_SG_REL_ Motor_konv SG_ 1124 PSD_Steigung_1_B_Steigung 1500;
BA_REL_ "GenSigTimeoutTime" BU_SG_REL_ Motor_konv SG_ 1124 PSD_Attribut_4_ID 1500;
BA_REL_ "GenSigTimeoutTime" BU_SG_REL_ Motor_konv SG_ 1124 PSD_Sys_Zielfuehrung 1500;
BA_REL_ "GenSigTimeoutTime" BU_SG_REL_ Motor_konv SG_ 1124 PSD_Sys_US_State 1500;
BA_REL_ "GenSigTimeoutTime" BU_SG_REL_ Motor_konv SG_ 1124 PSD_Ges_Geschwindigkeit_Gespann 1500;
BA_REL_ "GenSigTimeoutTime" BU_SG_REL_ Motor_konv SG_ 1124 PSD_Baum_Breite_VZ 1500;
BA_REL_ "GenSigTimeoutTime" BU_SG_REL_ Motor_konv SG_ 1124 PSD_Attribut_4_Wert 1500;
BA_REL_ "GenSigTimeoutTime" BU_SG_REL_ Motor_konv SG_ 1124 PSD_Baum_Breite 1500;
BA_REL_ "GenSigTimeoutTime" BU_SG_REL_ Motor_konv SG_ 1124 PSD_Ges_Geschwindigkeit_Witter 1500;
BA_REL_ "GenSigTimeoutTime" BU_SG_REL_ Motor_konv SG_ 1124 PSD_Steigung_1_B_Vorz 1500;
BA_REL_ "GenSigTimeoutTime" BU_SG_REL_ Motor_konv SG_ 1124 PSD_Steigung_1_B_Offset 1500;
BA_REL_ "GenSigTimeoutTime" BU_SG_REL_ Motor_konv SG_ 1124 PSD_Sys_Quali_Geometrien 1500;
BA_REL_ "GenSigTimeoutTime" BU_SG_REL_ Motor_konv SG_ 1124 PSD_Ges_Geschwindigkeit_Tag_Anf 1500;
BA_REL_ "GenSigTimeoutTime" BU_SG_REL_ Motor_konv SG_ 1124 PSD_Attribut_4_Offset 1500;
BA_REL_ "GenSigTimeoutTime" BU_SG_REL_ Motor_konv SG_ 1124 PSD_Sys_Quali_Ortsinfo 1500;
BA_REL_ "GenSigTimeoutTime" BU_SG_REL_ Motor_konv SG_ 1124 PSD_Ges_Geschwindigkeit_Tag_Ende 1500;
BA_REL_ "GenSigTimeoutTime" BU_SG_REL_ Motor_konv SG_ 1124 PSD_Sys_Quali_verfuegbar 1500;
BA_REL_ "GenSigTimeoutTime" BU_SG_REL_ Motor_konv SG_ 1124 PSD_Sys_Zielfuehrung_geaendert 1500;
BA_REL_ "GenSigTimeoutTime" BU_SG_REL_ Motor_konv SG_ 1124 PSD_Ges_Geschwindigkeit_Std_Anf 1500;
BA_REL_ "GenSigTimeoutTime" BU_SG_REL_ Motor_konv SG_ 1124 PSD_Steigung_1_Attribute_kompl 1500;
BA_REL_ "GenSigTimeoutTime" BU_SG_REL_ Motor_konv SG_ 1124 PSD_Sys_Geometrieguete_erweitert 1500;
BA_REL_ "GenSigTimeoutTime" BU_SG_REL_ Motor_konv SG_ 1124 PSD_Steigung_2_Segment_ID 1500;
BA_REL_ "GenSigTimeoutTime" BU_SG_REL_ Motor_konv SG_ 1124 PSD_Attribut_5_ID 1500;
BA_REL_ "GenSigTimeoutTime" BU_SG_REL_ Motor_konv SG_ 1124 PSD_Ges_Geschwindigkeit_Std_Ende 1500;
BA_REL_ "GenSigTimeoutTime" BU_SG_REL_ Motor_konv SG_ 1124 PSD_Attribut_5_Offset 1500;
BA_REL_ "GenSigTimeoutTime" BU_SG_REL_ Motor_konv SG_ 1124 PSD_Steigung_2_Steigung 1500;
BA_REL_ "GenSigTimeoutTime" BU_SG_REL_ Motor_konv SG_ 1124 PSD_Sys_Quali_sonstige_Attribute 1500;
BA_REL_ "GenSigTimeoutTime" BU_SG_REL_ Motor_konv SG_ 1124 PSD_Ges_Ueberholverbot 1500;
BA_REL_ "GenSigTimeoutTime" BU_SG_REL_ Motor_konv SG_ 1124 PSD_Sys_Quali_Steigungen 1500;
BA_REL_ "GenSigTimeoutTime" BU_SG_REL_ Motor_konv SG_ 1124 PSD_Ges_Wechselverkehrszeichen 1500;
BA_REL_ "GenSigTimeoutTime" BU_SG_REL_ Motor_konv SG_ 1124 PSD_Attribut_5_Wert 1500;
BA_REL_ "GenSigTimeoutTime" BU_SG_REL_ Motor_konv SG_ 1124 PSD_Steigung_2_Vorz 1500;
BA_REL_ "GenSigTimeoutTime" BU_SG_REL_ Motor_konv SG_ 1124 PSD_Sys_Quali_Strassenkennz 1500;
BA_REL_ "GenSigTimeoutTime" BU_SG_REL_ Motor_konv SG_ 1124 PSD_Wechselverkehrszeichen_Typ 1500;
BA_REL_ "GenSigTimeoutTime" BU_SG_REL_ Motor_konv SG_ 1124 PSD_Baum_Ausrichtung 1500;
BA_REL_ "GenSigTimeoutTime" BU_SG_REL_ Motor_konv SG_ 1124 PSD_Steigung_2_Offset 1500;
BA_REL_ "GenSigTimeoutTime" BU_SG_REL_ Motor_konv SG_ 1124 PSD_Ges_Gesetzlich_Kategorie 1500;
BA_REL_ "GenSigTimeoutTime" BU_SG_REL_ Motor_konv SG_ 1124 PSD_Sys_Quali_Tempolimits 1500;
BA_REL_ "GenSigTimeoutTime" BU_SG_REL_ Motor_konv SG_ 1124 PSD_Attribute_Komplett_06 1500;
BA_REL_ "GenSigTimeoutTime" BU_SG_REL_ Motor_konv SG_ 1124 PSD_Ges_Gesetzlich_Zusatz 1500;
BA_REL_ "GenSigTimeoutTime" BU_SG_REL_ Motor_konv SG_ 1124 PSD_Sys_Quali_Vorfahrtsregelung 1500;
BA_REL_ "GenSigTimeoutTime" BU_SG_REL_ Motor_konv SG_ 1124 PSD_Ges_Verkehrszeichen_Quelle 1500;
BA_REL_ "GenSigTimeoutTime" BU_SG_REL_ Motor_konv SG_ 1124 PSD_Steigung_2_Attribute_kompl 1500;
BA_REL_ "GenSigTimeoutTime" BU_SG_REL_ Motor_konv SG_ 1124 PSD_Ges_Attribute_Komplett 1500;
BA_REL_ "GenSigTimeoutTime" BU_SG_REL_ Motor_konv SG_ 1125 PSD_LR_Profil_Nummer 4500;
BA_REL_ "GenSigTimeoutTime" BU_SG_REL_ Motor_konv SG_ 1125 PSD_LR_01_MUX 4500;
BA_REL_ "GenSigTimeoutTime" BU_SG_REL_ Motor_konv SG_ 1125 PSD_LR_Profil_Laenge 4500;
BA_REL_ "GenSigTimeoutTime" BU_SG_REL_ Motor_konv SG_ 1125 PSD_LR_Koeffizientensatz_Nr 4500;
BA_REL_ "GenSigTimeoutTime" BU_SG_REL_ Motor_konv SG_ 1125 PSD_LR_Attribut_1_Offset 4500;
BA_REL_ "GenSigTimeoutTime" BU_SG_REL_ Motor_konv SG_ 1125 PSD_LR_Steigung_1_Offset 4500;
BA_REL_ "GenSigTimeoutTime" BU_SG_REL_ Motor_konv SG_ 1125 PSD_LR_Attribut_1_Wert 4500;
BA_REL_ "GenSigTimeoutTime" BU_SG_REL_ Motor_konv SG_ 1125 PSD_LR_Steigung_1_Vorz 4500;
BA_REL_ "GenSigTimeoutTime" BU_SG_REL_ Motor_konv SG_ 1125 PSD_LR_Steigung_1_Wert 4500;
BA_REL_ "GenSigTimeoutTime" BU_SG_REL_ Motor_konv SG_ 1125 PSD_LR_Fahrzeug_Pos 4500;
BA_REL_ "GenSigTimeoutTime" BU_SG_REL_ Motor_konv SG_ 1125 PSD_LR_Attribut_2_Offset 4500;
BA_REL_ "GenSigTimeoutTime" BU_SG_REL_ Motor_konv SG_ 1125 PSD_LR_Steigung_2_Offset 4500;
BA_REL_ "GenSigTimeoutTime" BU_SG_REL_ Motor_konv SG_ 1125 PSD_LR_Globale_Steigung_Vorz 4500;
BA_REL_ "GenSigTimeoutTime" BU_SG_REL_ Motor_konv SG_ 1125 PSD_LR_Globale_Steigung 4500;
BA_REL_ "GenSigTimeoutTime" BU_SG_REL_ Motor_konv SG_ 1125 PSD_LR_Attribut_2_Wert 4500;
BA_REL_ "GenSigTimeoutTime" BU_SG_REL_ Motor_konv SG_ 1125 PSD_LR_Steigung_2_Vorz 4500;
BA_REL_ "GenSigTimeoutTime" BU_SG_REL_ Motor_konv SG_ 1125 PSD_LR_Steigung_2_Wert 4500;
BA_REL_ "GenSigTimeoutTime" BU_SG_REL_ Motor_konv SG_ 1125 PSD_LR_Attribut_3_Offset 4500;
BA_REL_ "GenSigTimeoutTime" BU_SG_REL_ Motor_konv SG_ 1125 PSD_LR_Steigung_3_Offset 4500;
BA_REL_ "GenSigTimeoutTime" BU_SG_REL_ Motor_konv SG_ 1125 PSD_LR_Max_Koeff_Amp 4500;
BA_REL_ "GenSigTimeoutTime" BU_SG_REL_ Motor_konv SG_ 1125 PSD_LR_Attribut_3_Wert 4500;
BA_REL_ "GenSigTimeoutTime" BU_SG_REL_ Motor_konv SG_ 1125 PSD_LR_Steigung_3_Vorz 4500;
BA_REL_ "GenSigTimeoutTime" BU_SG_REL_ Motor_konv SG_ 1125 PSD_LR_Steigung_3_Wert 4500;
BA_REL_ "GenSigTimeoutTime" BU_SG_REL_ Motor_konv SG_ 1125 PSD_LR_Reset 4500;
BA_REL_ "GenSigTimeoutTime" BU_SG_REL_ Parksperre SG_ 2600468496 NM_Gateway_NM_State 2000;
BA_REL_ "GenSigTimeoutTime" BU_SG_REL_ Parksperre SG_ 2600468599 NM_Getriebe_01_NM_State 2000;
BA_REL_ "GenSigTimeoutTime" BU_SG_REL_ Parksperre SG_ 2600468598 NM_MO_01_NM_State 2000;
BA_REL_ "GenSigTimeoutTime" BU_SG_REL_ Parksperre SG_ 2600468733 NM_Waehlhebel_NM_State 2000;
BA_REL_ "GenSigTimeoutTime" BU_SG_REL_ Schaltbetaetigung SG_ 2600468496 NM_Gateway_NM_State 2000;
BA_REL_ "GenSigTimeoutTime" BU_SG_REL_ Schaltbetaetigung SG_ 2600468599 NM_Getriebe_01_NM_State 2000;
BA_REL_ "GenSigTimeoutTime" BU_SG_REL_ Schaltbetaetigung SG_ 2600468598 NM_MO_01_NM_State 2000;
BA_REL_ "GenSigTimeoutTime" BU_SG_REL_ Schaltbetaetigung SG_ 2600469458 NM_Parksperre_NM_State 2000;
VAL_ 339 MO_HVEM_Eskalation 0 "keine_Eskalation_HVEM" 1 "Eskalation_HVEM" ;
VAL_ 339 MO_ErwGrenzen_Anf 0 "normal" 1 "erweitert" ;
VAL_ 339 MO_Fehler_Notentladung_Anf 0 "Init" ;
VAL_ 339 MO_HVEM_MaxLeistung 510 "Init" ;
VAL_ 339 MO_HVK_EmIstzustand 0 "HvOff" 1 "HvStbyReq" 2 "HvStbyOk" 3 "HvBattOnReq" 4 "HvBattOnOk" 10 "HvOnIdle" 18 "HvOnDrvReq" 19 "HvOnDrvOk" 20 "HvOnDrvRdy" 28 "HvStepUpReq" 29 "HvStepUpOk" 30 "HvStepUp" 38 "HvStepDownReq" 39 "HvStepDownOk" 40 "HvStepDown" 46 "HvAcChPreReq" 47 "HvAcChPreOk" 48 "HvAcChReq" 49 "HvAcChOk" 50 "HvAcCh" 56 "HvDcChPreReq" 57 "HvDcChPreOk" 58 "HvDcChReq" 59 "HvDcChOk" 60 "HvDcCh" 67 "HvChOffReq" 68 "HvChOffOk" 69 "HvOnIdleReq" 70 "HvOnIdleOk" 96 "HvCpntOffReq" 97 "HvCpntOffOk" 98 "HvBattOffReq" 99 "HvBattOffOk" 109 "HvDcDcFailOffReq" 110 "HvDcDcFail" 119 "HvElmOffReq" 120 "HvElmOff" 126 "HvFailCpntOffReq" 127 "HvFailCpntOffOk" 128 "HvFailBattOffReq" 129 "HvFailBattOffOk" 130 "HvFailBattOff" 138 "HvFailUCtlReq" 139 "HvFailUCtlOk" 140 "HvFailUCtl" 150 "HvEmgcyOff" 255 "Init" ;
VAL_ 339 MO_HVK_AntriebFehlerstatus 0 "Komponente_IO" 6 "Keine_Komponentenfunktion" 7 "Init" ;
VAL_ 339 MO_MVK_Bordnetz_Anf 0 "keine_Anforderung" 1 "Bordnetzaktivitaet_gefordert" ;
VAL_ 339 MO_HVK_AntriebZustand 0 "Antrieb_AUS" 1 "Antrieb_Startphase" 2 "E_Fahren" 3 "Hybrid_Fahren" 7 "Init" ;
VAL_ 339 MO_HVK_EmFehlerstatus 0 "Komponente_IO" 1 "Eingeschr_KompFkt_Teilbetrieb" 3 "Eingeschr_KompFkt_Interlock" 6 "Keine_Komponentenfunktion" 7 "Init" ;
VAL_ 339 MO_MVK_AntriebFehlerstatus 0 "Komponente_IO" 6 "Keine_Komponentenfunktion" 7 "Init" ;
VAL_ 339 MO_MVK_AntriebZustand 0 "Antrieb_AUS" 1 "Antrieb_Startphase" 2 "FreilaufMotorAus" 7 "Init" ;
VAL_ 339 MO_MVK_EmFehlerstatus 0 "Komponente_IO" 1 "Eingeschr_KompFkt_Teilbetrieb" 6 "Keine_Komponentenfunktion" 7 "Init" ;
VAL_ 339 MO_MVK_EmIstzustand 0 "MvOff" 1 "MvStbyReq" 2 "MvStbyOk" 3 "MvBattOnReq" 4 "MvBattOnOk" 10 "MvOnIdle" 18 "MvOnDrvReq" 19 "MvOnDrvOk" 20 "MvOnDrv" 28 "MvStepUpReq" 29 "MvStepUpOk" 30 "MvStepUp" 38 "MvStepDownReq" 39 "MvStepDownOk" 40 "MvStepDown" 96 "MvCpntOffReq" 97 "MvCpntOffOk" 98 "MvBattOffReq" 99 "MvBattOffOk" 109 "MvDcDcFailOffReq" 110 "MvDcDcFail" 119 "MvElmFailOffReq" 120 "MvElmFail" 126 "MvFailCpntOffReq" 127 "MvFailCpntOffOk" 128 "MvFailBattOffReq" 129 "MvFailBattOffOk" 130 "MvFailBattOff" 138 "MvFailUCtlReq" 139 "MvFailUCtlOk" 140 "MvFailUCtl" 150 "MvEmgcyOff" 255 "Init" ;
VAL_ 931 MVEM_IstStrom_MVVerbraucher 1022 "Init" 1023 "Fehler" ;
VAL_ 931 MVEM_DC_SollSpannung_MV 254 "Init" 255 "Fehler" ;
VAL_ 931 MVEM_DC_SollLeistung_MV 254 "Init" 255 "Fehler" ;
VAL_ 931 MVEM_EMG_MaxGenStrom 254 "Init" 255 "Fehler" ;
VAL_ 931 MVEM_EMG_MaxGenSpannung 254 "Init" 255 "Fehler" ;
VAL_ 2589283456 MVEM_MO_USoll_Notbetrieb 1022 "Init" 1023 "Fehler" ;
VAL_ 2589283456 MVEM_Kaltstart_StuetzLeistung 254 "Init" 255 "Fehler" ;
VAL_ 2589283456 MVEM_Umax_Rueckspeisung 254 "Init" 255 "Fehler" ;
VAL_ 2589283456 MVEM_Umin_Funktionsgruppe_C 254 "Init" 255 "Fehler" ;
VAL_ 2589283456 MVEM_Umin_Funktionsgruppe_B 254 "Init" 255 "Fehler" ;
VAL_ 2589283456 MVEM_Umin_Funktionsgruppe_A 254 "Init" 255 "Fehler" ;
VAL_ 2463978719 MVEM_IstLeistung_MVVerbraucher 1022 "Init" 1023 "Fehler" ;
VAL_ 2463978719 MVEM_Eskalation_Energieversorgun 0 "Init" 1 "keine_Eskalation" 2 "Energieaufnahme_verboten" ;
VAL_ 2463978719 MVEM_MO_anbietLeist_MVVerbrauch 1022 "Init" 1023 "Fehler" ;
VAL_ 2463978719 MVEM_MO_MinLeistung_MVVerbrauch 1022 "Init" 1023 "Fehler" ;
VAL_ 2463978719 MVEM_MO_WunschLeist_MVVerbrauch 1022 "Init" 1023 "Fehler" ;
VAL_ 1284 MVK_DCDC_Sollmodus_02 0 "Standby" 1 "MV_On" 2 "Tiefsetzen" 3 "Hochsetzen" 4 "Startunterstuetzung_48V" 6 "Startunterstuetzung_12V" 7 "Init" 9 "MV_On_Notbetrieb" 10 "Tiefsetzen_Notbetrieb" 11 "Pruefpuls_12V" 13 "Reaktivierung_BMS" ;
VAL_ 1284 MVK_MV_Batteriewarnung 0 "Keine_Warnung" 1 "Warnung_Temperatur_Level1" 2 "Warnung_Temperatur_Level2" ;
VAL_ 1284 MV_Bordnetz_belastbar 0 "nicht_belastbar" 1 "belastbar" ;
VAL_ 1284 MV_Bordnetz_aktiv 0 "inaktiv" 1 "aktiv" ;
VAL_ 1284 MVK_BOOST_Sollmodus 0 "Keine_Freigabe" 1 "Freigabe" 7 "Init" ;
VAL_ 1284 MVK_eABC_Sollmodus 0 "Keine_Freigabe" 1 "Freigabe" 7 "Init" ;
VAL_ 1284 MVK_eAWS_Sollmodus 0 "Keine_Freigabe" 1 "Freigabe" 7 "Init" ;
VAL_ 1284 MV_Bordnetz_Fehler 0 "kein_Fehler" 1 "Fehler" ;
VAL_ 1284 MVK_MVPTC_Sollmodus 0 "Keine_Freigabe" 1 "Freigabe" 7 "Init" ;
VAL_ 1284 MVK_Istmodus_Anf 0 "nicht_angefordert" 1 "angefordert" ;
VAL_ 1284 MVK_MO_EmSollzustand 0 "MvOff" 1 "MvStbyReq" 2 "MvStbyWait" 3 "MvBattOnReq" 4 "MvBattOnWait" 10 "MvOnIdle" 18 "MvOnDrvReq" 19 "MvOnDrvWait" 20 "MvOnDrv" 28 "MvStepUpReq" 29 "MvStepUpWait" 30 "MvStepUp" 38 "MvStepDownReq" 39 "MvStepDownWait" 40 "MvStepDown" 96 "MvCpntOffReq" 97 "MvCpntOffWait" 98 "MvBattOffReq" 99 "MvBattOffWait" 109 "MvDcDcFailOffReq" 110 "MvDcDcFail" 119 "MvElmFailOffReq" 120 "MvElmFail" 126 "MvFailCpntOffReq" 127 "MvFailCpntOffWait" 128 "MvFailBattOffReq" 129 "MvFailBattOffWait" 130 "MvFailBattOff" 138 "MvFailUCtlReq" 139 "MvFailUCtlWait" 140 "MvFailUCtl" 150 "MvEmgcyOff" 255 "Init" ;
VAL_ 1284 MVK_BMS_Sollmodus 0 "MV_Off" 1 "MV_On" 7 "Init" ;
VAL_ 1284 MVK_DCDC_Sollmodus 0 "Standby" 1 "MV_On" 2 "Tiefsetzen" 3 "Hochsetzen" 4 "Startunterstuetzung_48V" 6 "Startunterstuetzung_12V" 7 "Init" ;
VAL_ 1284 MVK_MV_Netz_Warnungen 0 "Keine_Warnung" 1 "Warntext_MV_Netz_Anf" 2 "Fehlertext_MV_Netz_Anf" 3 "Warnung_Kein_Wiederstart_moeglic" ;
VAL_ 2600468496 NM_Gateway_CBV_AWB 0 "Passiver_WakeUp" 1 "Aktiver_WakeUp" ;
VAL_ 2600468496 NM_Gateway_CBV_CRI 0 "NM_ohne_Clusteranforderungen" 1 "NM_mit_Clusteranforderungen" ;
VAL_ 2600468496 NM_Gateway_NM_State 0 "Init" 1 "NM_RM_aus_BSM" 2 "NM_RM_aus_PBSM" 4 "NM_NO_aus_RM" 8 "NM_NO_aus_RS" 16 "reserved" 32 "reserved" ;
VAL_ 2600468496 NM_Gateway_Car_Wakeup 0 "Inaktiv" 1 "Car_Wakeup" ;
VAL_ 2600468496 NM_Gateway_UDS_CC 0 "Inaktiv" 1 "CC_aktiv" ;
VAL_ 2600468496 NM_Gateway_NM_aktiv_KL15 0 "Inaktiv" 1 "KL15_EIN" ;
VAL_ 2600468496 NM_Gateway_NM_aktiv_Diagnose 0 "Init" 1 "Diagnose_aktiv" ;
VAL_ 2600468496 NM_Gateway_NM_aktiv_Tmin 0 "Inaktiv" 1 "Mindestaktivzeit" ;
VAL_ 2600468496 NM_Gateway_NM_aktiv_CWU 0 "kein_CWU_gesetzt" 1 "CWU_gesetzt" ;
VAL_ 2600468496 NM_Gateway_NM_aktiv_FC 0 "kein_FC_gesetzt" 1 "FC_gesetzt" ;
VAL_ 2600468496 NM_Gateway_NM_aktiv_EM 0 "inaktiv" 1 "Nachlauf_aufgrund_Energiemanagement" ;
VAL_ 2600468496 NM_Gateway_NM_aktiv_Buskopplung 0 "inaktiv" 1 "Nachlauf_aufgrund_Buskopplung" ;
VAL_ 2600468496 NM_Gateway_CAB_V14 0 "Init" 1 "CAB_01_Antrieb" 2 "CAB_02_Hybrid_Laden" 4 "CAB_03_Fahrwerk" 8 "CAB_04_Fahrerassistenz" 16 "CAB_05_Komfort" 32 "CAB_06_Anzeige" 64 "CAB_07_Connect" 128 "CAB_08_MIB" 256 "CAB_09_Standheizung" 1024 "CAB_11_VLAN_Fahrerassistenz" 2048 "CAB_12_VLAN_Komfort" 4096 "CAB_13_VLAN_Connect" 8192 "CAB_14_VLAN_Infotainment" 16384 "CAB_15_Laden" 32768 "CAB_16_Licht" ;
VAL_ 2600468599 NM_Getriebe_01_CBV_AWB 0 "Passiver_WakeUp" 1 "Aktiver_WakeUp" ;
VAL_ 2600468599 NM_Getriebe_01_CBV_CRI 0 "NM_ohne_Clusteranforderungen" 1 "NM_mit_Clusteranforderungen" ;
VAL_ 2600468599 NM_Getriebe_01_NM_State 0 "Init" 1 "NM_RM_aus_BSM" 2 "NM_RM_aus_PBSM" 4 "NM_NO_aus_RM" 8 "NM_NO_aus_RS" 16 "reserved" 32 "reserved" ;
VAL_ 2600468599 NM_Getriebe_01_Car_Wakeup 0 "Inaktiv" 1 "Car_Wakeup" ;
VAL_ 2600468599 NM_Getriebe_01_UDS_CC 0 "Inaktiv" 1 "CC_aktiv" ;
VAL_ 2600468599 NM_Getriebe_01_NM_aktiv_KL15 0 "Inaktiv" 1 "KL15_EIN" ;
VAL_ 2600468599 NM_Getriebe_01_NM_aktiv_Diagnose 0 "Init" 1 "Diagnose_aktiv" ;
VAL_ 2600468599 NM_Getriebe_01_NM_aktiv_Tmin 0 "Inaktiv" 1 "Mindestaktivzeit" ;
VAL_ 2600468599 NM_Getriebe_01_NM_aktiv_v_gr_0 1 "v_groesser_0" ;
VAL_ 2600468599 NM_Getriebe_01_NM_aktiv_N_Halte 1 "Anzeige_Ende_N_Haltephase" ;
VAL_ 2600468599 NM_Getriebe_01_NM_aktiv_PosAnz 1 "Positionsanzeige_aktiv" ;
VAL_ 2600468599 NM_Getriebe_01_NM_aktiv_Waehlheb 0 "kein_Nachlauf" 1 "Kommunikation_Waehlhebel" ;
VAL_ 2600468599 NM_Getriebe_01_CAB_V14 0 "Init" 1 "CAB_01_Antrieb" 2 "CAB_02_Hybrid_Laden" 4 "CAB_03_Fahrwerk" 8 "CAB_04_Fahrerassistenz" 16 "CAB_05_Komfort" 32 "CAB_06_Anzeige" 64 "CAB_07_Connect" 128 "CAB_08_MIB" 256 "CAB_09_Standheizung" 1024 "CAB_11_VLAN_Fahrerassistenz" 2048 "CAB_12_VLAN_Komfort" 4096 "CAB_13_VLAN_Connect" 8192 "CAB_14_VLAN_Infotainment" 16384 "CAB_15_Laden" 32768 "CAB_16_Licht" ;
VAL_ 2600468598 NM_MO_01_CBV_AWB 0 "Passiver_WakeUp" 1 "Aktiver_WakeUp" ;
VAL_ 2600468598 NM_MO_01_CBV_CRI 0 "NM_ohne_Clusteranforderungen" 1 "NM_mit_Clusteranforderungen" ;
VAL_ 2600468598 NM_MO_01_NM_State 0 "Init" 1 "NM_RM_aus_BSM" 2 "NM_RM_aus_PBSM" 4 "NM_NO_aus_RM" 8 "NM_NO_aus_RS" 16 "reserved" 32 "reserved" ;
VAL_ 2600468598 NM_MO_01_Car_Wakeup 0 "Inaktiv" 1 "Car_Wakeup" ;
VAL_ 2600468598 NM_MO_01_UDS_CC 0 "Inaktiv" 1 "CC_aktiv" ;
VAL_ 2600468598 NM_MO_01_NM_aktiv_KL15 0 "Inaktiv" 1 "KL15_EIN" ;
VAL_ 2600468598 NM_MO_01_NM_aktiv_Diagnose 0 "Init" 1 "Diagnose_aktiv" ;
VAL_ 2600468598 NM_MO_01_NM_aktiv_Tmin 0 "Inaktiv" 1 "Mindestaktivzeit" ;
VAL_ 2600468598 NM_MO_01_NM_aktiv_Betankung 0 "kein_Nachlauf" 1 "Betankung_Drucktank" ;
VAL_ 2600468598 NM_MO_01_NM_aktiv_Oelstandsmes 0 "Oelstandsmessung_nicht_aktiv" 1 "Oelstandsmesseung_aktiv" ;
VAL_ 2600468598 NM_MO_01_NM_aktiv_Waehlhebel 0 "kein_Nachlauf" 1 "Kommunikation_Waehlhebel" ;
VAL_ 2600468598 NM_MO_01_NM_aktiv_NOx_PM_SensDia 0 "inaktiv" 1 "NOX_PM_Diagnose_aktiv" ;
VAL_ 2600468598 NM_MO_01_NM_aktiv_Anf_RSG 0 "kein_Nachlauf" 1 "Komm_zu_RSG" ;
VAL_ 2600468598 NM_MO_01_NM_aktiv_HV_Abschaltung 0 "kein_Nachlauf" 1 "Abschaltung_aktiv" ;
VAL_ 2600468598 NM_MO_01_NM_aktiv_EKP_Vorlauf 0 "kein_Nachlauf" 1 "EKP_Vorlauf" ;
VAL_ 2600468598 NM_MO_01_NM_aktiv_STH_Betrieb 0 "kein_Nachlauf" 1 "Standheizungsbetrieb" ;
VAL_ 2600468598 NM_MO_01_NM_aktiv_Hochvolt 0 "kein_Nachlauf" 1 "Hochvolt_aktiv" ;
VAL_ 2600468598 NM_MO_01_NM_aktiv_AnzKLuefter 0 "Inaktiv" 1 "aktiv" ;
VAL_ 2600468598 NM_MO_01_CAB_V14 0 "Init" 1 "CAB_01_Antrieb" 2 "CAB_02_Hybrid_Laden" 4 "CAB_03_Fahrwerk" 8 "CAB_04_Fahrerassistenz" 16 "CAB_05_Komfort" 32 "CAB_06_Anzeige" 64 "CAB_07_Connect" 128 "CAB_08_MIB" 256 "CAB_09_Standheizung" 1024 "CAB_11_VLAN_Fahrerassistenz" 2048 "CAB_12_VLAN_Komfort" 4096 "CAB_13_VLAN_Connect" 8192 "CAB_14_VLAN_Infotainment" 16384 "CAB_15_Laden" 32768 "CAB_16_Licht" ;
VAL_ 2600469458 NM_Parksperre_CBV_AWB 0 "Passiver_WakeUp" 1 "Aktiver_WakeUp" ;
VAL_ 2600469458 NM_Parksperre_CBV_CRI 0 "Standard_Layout" 1 "TNB_Layout" ;
VAL_ 2600469458 NM_Parksperre_NM_State 0 "Inaktiv" 1 "NM_RM_aus_BSM" 2 "NM_RM_aus_PBSM" 4 "NM_NO_aus_RM" 8 "NM_NO_aus_RS" ;
VAL_ 2600469458 NM_Parksperre_Car_Wakeup 0 "Inaktiv" 1 "Car_Wakeup" ;
VAL_ 2600469458 NM_Parksperre_UDS_CC 0 "Inaktiv" 1 "CC_aktiv" ;
VAL_ 2600469458 NM_Parksperre_NM_aktiv_KL15 0 "Inaktiv" 1 "KL15_EIN" ;
VAL_ 2600469458 NM_Parksperre_NM_aktiv_Diagnose 0 "Inaktiv" 1 "Diagnose_aktiv" ;
VAL_ 2600469458 NM_Parksperre_NM_aktiv_Tmin 0 "Inaktiv" 1 "Mindestaktivzeit" ;
VAL_ 2600469458 NM_Parksperre_aktiv_Feder_n_entl 0 "Inaktiv" 1 "Feder_noch_nicht_entladen" ;
VAL_ 2600469458 NM_Parksperre_CAB_V14 0 "Init" 1 "CAB_01_Antrieb" 2 "CAB_02_Hybrid_Laden" 4 "CAB_03_Fahrwerk" 8 "CAB_04_Fahrerassistenz" 16 "CAB_05_Komfort" 32 "CAB_06_Anzeige" 64 "CAB_07_Connect" 128 "CAB_08_MIB" 256 "CAB_09_Standheizung" 1024 "CAB_11_VLAN_Fahrerassistenz" 2048 "CAB_12_VLAN_Komfort" 4096 "CAB_13_VLAN_Connect" 8192 "CAB_14_VLAN_Infotainment" 16384 "CAB_15_Laden" 32768 "CAB_16_Licht" ;
VAL_ 2600468733 NM_Waehlhebel_CBV_AWB 0 "Passiver_WakeUp" 1 "Aktiver_WakeUp" ;
VAL_ 2600468733 NM_Waehlhebel_CBV_CRI 0 "NM_ohne_Clusteranforderungen" 1 "NM_mit_Clusteranforderungen" ;
VAL_ 2600468733 NM_Waehlhebel_NM_State 0 "Init" 1 "NM_RM_aus_BSM" 2 "NM_RM_aus_PBSM" 4 "NM_NO_aus_RM" 8 "NM_NO_aus_RS" 16 "reserved" 32 "reserved" ;
VAL_ 2600468733 NM_Waehlhebel_Car_Wakeup 0 "Inaktiv" 1 "Car_Wakeup" ;
VAL_ 2600468733 NM_Waehlhebel_UDS_CC 0 "Inaktiv" 1 "CC_aktiv" ;
VAL_ 2600468733 NM_Waehlhebel_NM_aktiv_KL15 0 "Inaktiv" 1 "KL15_EIN" ;
VAL_ 2600468733 NM_Waehlhebel_NM_aktiv_Diagnose 0 "Init" 1 "Diagnose_aktiv" ;
VAL_ 2600468733 NM_Waehlhebel_NM_aktiv_Tmin 0 "Inaktiv" 1 "Mindestaktivzeit" ;
VAL_ 2600468733 NM_Waehlhebel_CAB_V14 0 "Init" 1 "CAB_01_Antrieb" 2 "CAB_02_Hybrid_Laden" 4 "CAB_03_Fahrwerk" 8 "CAB_04_Fahrerassistenz" 16 "CAB_05_Komfort" 32 "CAB_06_Anzeige" 64 "CAB_07_Connect" 128 "CAB_08_MIB" 256 "CAB_09_Standheizung" 1024 "CAB_11_VLAN_Fahrerassistenz" 2048 "CAB_12_VLAN_Komfort" 4096 "CAB_13_VLAN_Connect" 8192 "CAB_14_VLAN_Infotainment" 16384 "CAB_15_Laden" 32768 "CAB_16_Licht" ;
VAL_ 1630 OBD_TG_F_Status_1 0 "kein Fehler / Init / nicht verbaut" 1 "KS- (Kurzschluss nach minus)" 2 "KS+ (Kurzschluss nach plus)" 3 "OC (Leitungsunterbrechung)" 4 "OOR+ (Signal zu gross)" 5 "OOR- (Signal zu klein)" 6 "RC+ (Signal unplausibel zu gross)" 7 "RC- (Signal unplausibel zu klein)" 8 "KS+/OC (Kurzschluss nach plus/Unterbrechung)" 9 "KS-/OC  (Kurzschluss nach minus/Unterbrechung)" 10 "KS-/KS+  (Kurzschluss nach minus/plus)" 11 "KS-/KS+/OC (Kurzschluss nach minus/plus/Unterbrechung)" 12 "frei" 13 "frei" 14 "frei" 15 "frei" ;
VAL_ 1630 OBD_TG_F_Status_2 0 "kein Fehler / Init / nicht verbaut" 1 "KS- (Kurzschluss nach minus)" 2 "KS+ (Kurzschluss nach plus)" 3 "OC (Leitungsunterbrechung)" 4 "OOR+ (Signal zu gross)" 5 "OOR- (Signal zu klein)" 6 "RC+ (Signal unplausibel zu gross)" 7 "RC- (Signal unplausibel zu klein)" 8 "KS+/OC (Kurzschluss nach plus/Unterbrechung)" 9 "KS-/OC  (Kurzschluss nach minus/Unterbrechung)" 10 "KS-/KS+  (Kurzschluss nach minus/plus)" 11 "KS-/KS+/OC (Kurzschluss nach minus/plus/Unterbrechung)" 12 "frei" 13 "frei" 14 "frei" 15 "frei" ;
VAL_ 1630 OBD_TG_F_Status_3 0 "kein Fehler / Init / nicht verbaut" 1 "KS- (Kurzschluss nach minus)" 2 "KS+ (Kurzschluss nach plus)" 3 "OC (Leitungsunterbrechung)" 4 "OOR+ (Signal zu gross)" 5 "OOR- (Signal zu klein)" 6 "RC+ (Signal unplausibel zu gross)" 7 "RC- (Signal unplausibel zu klein)" 8 "KS+/OC (Kurzschluss nach plus/Unterbrechung)" 9 "KS-/OC  (Kurzschluss nach minus/Unterbrechung)" 10 "KS-/KS+  (Kurzschluss nach minus/plus)" 11 "KS-/KS+/OC (Kurzschluss nach minus/plus/Unterbrechung)" 12 "frei" 13 "frei" 14 "frei" 15 "frei" ;
VAL_ 1630 OBD_TG_F_Status_4 0 "kein Fehler / Init / nicht verbaut" 1 "KS- (Kurzschluss nach minus)" 2 "KS+ (Kurzschluss nach plus)" 3 "OC (Leitungsunterbrechung)" 4 "OOR+ (Signal zu gross)" 5 "OOR- (Signal zu klein)" 6 "RC+ (Signal unplausibel zu gross)" 7 "RC- (Signal unplausibel zu klein)" 8 "KS+/OC (Kurzschluss nach plus/Unterbrechung)" 9 "KS-/OC  (Kurzschluss nach minus/Unterbrechung)" 10 "KS-/KS+  (Kurzschluss nach minus/plus)" 11 "KS-/KS+/OC (Kurzschluss nach minus/plus/Unterbrechung)" 12 "frei" 13 "frei" 14 "frei" 15 "frei" ;
VAL_ 2463978776 HVLE_IstSpannung_HV 1022 "Init" 1023 "Fehler" ;
VAL_ 2463978776 HVLE_Ist_Wirkungsgrad 126 "Init" 127 "Fehler" ;
VAL_ 2463978776 HVLE_Netzfrequenz_EVU 509 "kein_Frequenz_erkannt" 510 "Init" 511 "Fehler" ;
VAL_ 2463978776 HVLE_I_istAC_Netz_L1 509 "nicht_vorhanden" 510 "Init" 511 "Fehler" ;
VAL_ 2463978776 HVLE_I_istAC_Netz_L2 509 "nicht_vorhanden" 510 "Init" 511 "Fehler" ;
VAL_ 2463978776 HVLE_I_istAC_Netz_L3 509 "nicht_vorhanden" 510 "Init" 511 "Fehler" ;
VAL_ 2463978776 HVLE_U_istAC_Netz_L1 509 "nicht_vorhanden" 510 "Init" 511 "Fehler" ;
VAL_ 2463978776 HVLE_U_istAC_Netz_L2 509 "nicht_vorhanden" 510 "Init" 511 "Fehler" ;
VAL_ 2463978776 HVLE_U_istAC_Netz_L3 509 "nicht_vorhanden" 510 "Init" 511 "Fehler" ;
VAL_ 2463978776 HVLE_OBG_DC_MaxStrom 2046 "Init" 2047 "Fehler" ;
VAL_ 2463978776 HVLE_OBG_DC_IstStrom 2046 "Init" 2047 "Fehler" ;
VAL_ 2463978776 HVLE_Netzmodus 0 "Init" 1 "no_grid" 2 "one_phase_L1" 3 "one_phase_not_L1" 4 "two_phase" 5 "three_phase" 6 "delta_grid" 7 "parallel_phases" 15 "Fehler" ;
VAL_ 2463978776 HVLE_Derating_Temperatur 0 "kein_Derating_aktiv" 1 "Derating_aktiv" ;
VAL_ 2463978776 HVLE_OBG_IstModus 0 "Standby" 1 "Netzladung_aktiv" 2 "Rueckspeisung_aktiv" 3 "Vorladen_aktiv" 4 "Vorladespannung_erreicht_und_halten" 5 "reserve" 6 "Init" 7 "Fehler" ;
VAL_ 2463978776 HVLE_OBG_Warnzustand 0 "keine_Warnung_aktiv" 1 "Leistungsbegrenzung_maxDCAusgangsstrom" 2 "Leistungsbegrenzung_maxDCAusgangsspannung" 3 "Leistungsbegrenzung_Spanungsnetz" 4 "Ueberspannung" 5 "minStromLimit" 6 "Ueberstrom_aktuell" 7 "Ueberstrom_Ladegeraet" 8 "Netzausfall" 9 "Komponentenschutz_aktiv" ;
VAL_ 2463978776 HVLE_OBG_Fehlerstatus 0 "kein_Fehler_aktiv" 1 "Fehler_aktiv_Laden_beendet" ;
VAL_ 2463978776 HVLE_OBG_Status_EoHVL 0 "Init" 1 "Keine_offene_HV_Leitung_erkannt" 2 "offene_HV_Leitung_erkannt" 3 "Fehler" ;
VAL_ 2463978776 HVLE_OBG_Fehlerstrom 0 "Kein_Fehlerstrom" 1 "Fehlerstrom" ;
VAL_ 2463978776 HVLE_OBG_ACDC_IstLeistung 2046 "Init" 2047 "Fehler" ;
VAL_ 2463978776 HVLE_OBG_ACDC_MaxLeistung 2046 "Init" 2047 "Fehler" ;
VAL_ 2463978776 HVLE_OBG_AC_maxStrom 1022 "Init" 1023 "Fehler" ;
VAL_ 2463978776 HVLE_OBG_AC_maxSpannung 1022 "Init" 1023 "Fehler" ;
VAL_ 2463978776 HVLE_AnzahlVerwendeterPhasen 0 "eine_phase_verwendet" 1 "zwei_phasen_verwendet" 2 "drei_phasen_verwendet" 3 "Fehler" ;
VAL_ 2463978776 HVLE_AsymmetrischLadenMoeglich 0 "moeglich" 1 "nicht_moeglich" ;
VAL_ 2463978776 HVLE_OBG_Typ_verbaut 0 "IPB_galvanisch_nichtGetrennt" 1 "SAC" 2 "OCC" 3 "IPB_galvanisch_getrennt" 4 "SAC_galvanisch_getrennt" 5 "Reserve" 6 "Reserve" 7 "Init" ;
VAL_ 2463978776 HVLE_PE_Monitor 0 "keine_PE_Messung_aktiv" 1 "PE_erkannt" 2 "IT-Netz_erkannt" 3 "PE_nicht_erkannt" 7 "Fehler" ;
VAL_ 2463978776 HVLE_OBG_Status_Spgfreiheit 0 "Init__ohne_Funktion" 1 "HV_Komponente_Spannungsfrei" 2 "HV_Komponente_nichtSpannungsfrei" 3 "Fehler" ;
VAL_ 2463978776 HVLE_OBG_Kuehltemperatur 254 "Init" 255 "Fehler" ;
VAL_ 2589284143 OBMI_StAct 0 "Warnung_nicht_aktiv" 1 "Warnstufe_1_aktiv" 2 "Warnstufe_2_aktiv" 3 "Warnstufe_3_aktiv" ;
VAL_ 2589284143 OBMI_FlgTrig 0 "Warnung_Retrigger_nicht_aktiv" 1 "Warnung_Retrigger_aktiv" ;
VAL_ 2589284143 OBMI_StDrvRngUnit 0 "Restreichweite_Kilometer" 1 "Restreichweite_Meilen" ;
VAL_ 2589284143 OBMI_DDrvRngRem 8190 "Init" ;
VAL_ 2589283656 ORU_Warnung 0 "keine_Anzeige" 1 "Update_unvollstaendig_Prio1" 2 "Update_fehlgeschlagen_Prio1" 3 "reserviert" ;
VAL_ 2589283656 ORU_Status 0 "IDLE" 1 "PENDING" 2 "PREPARATION" 3 "PREPARATION_HV" 4 "RUNNING" 5 "RUNNING_HV" 6 "PENDING_NOTREADY" 7 "FAILURE_POWERTRAIN_DISABLED" ;
VAL_ 518 Parken_BKD_Anf 14 "Neutralwert" 15 "Fehler" ;
VAL_ 518 Parken_Verz_Anf 126 "Neutralwert" 127 "reserved" ;
VAL_ 518 Parken_Prefill_Anf 0 "keine_Anforderung" 1 "Prefill_Anforderung" ;
VAL_ 518 Parken_Warnruck_Anf 0 "Keine_Anforderung" 1 "schwacher_Warnruck" 2 "mittlerer_Warnruck" 3 "starker_Warnruck" ;
VAL_ 518 Parken_Verz_Anf_ASIL 0 "ASIL_QM" 1 "ASIL_A" 2 "ASIL_B" 3 "ASIL_C" ;
VAL_ 518 Parken_Warnruckeln_Anf 0 "keine_Anforderung" 1 "schwaches_Warnruckeln" 2 "mittleres_Warnruckeln" 3 "starkes_Warnruckeln" ;
VAL_ 518 Parken_beibehalten 0 "Parken_nicht_beibehalten" 1 "Parken_beibehalten" 2 "Init" 3 "Fehler" ;
VAL_ 518 Parken_Anforderung_HMS 0 "keine_Anforderung" 1 "Halten" 2 "Parken" 3 "Halten_standby" 4 "Anfahren" 5 "Loesen_ueber_Rampe" 6 "Parken_mit_P" 7 "HMS_uebernehmen" ;
VAL_ 518 Parken_Fahrbereitschaft_Anf 0 "keine_Anforderung" 1 "Anforderung_Fahrbereitschaft" ;
VAL_ 518 Parken_Motorlauf_Anf 0 "Keine_Anforderung" 1 "Motor_aus" 2 "Motor_an" 3 "Weiterlauf_Fahreruebernahme" ;
VAL_ 518 IPA_TPA_ausgerichtetes_Parken 0 "nicht_aktiv" 1 "aktiv" ;
VAL_ 518 Parken_Notstopp_Anf 0 "Ueberwachung_aus" 1 "Ueberwachung_ein" 2 "Notstopp_ausloesen" ;
VAL_ 518 Parken_Anhalteweg_Anf 1022 "Neutralwert" 1023 "Fehler" ;
VAL_ 518 Parken_aktives_System 0 "kein_aktives_System" 1 "Manoevrierassistent_Ueberwachung" 2 "IPA" 3 "fernbedientes_Parken" 4 "Manoevrierassistent" 5 "Manoevrierassistent_quer" 6 "Anhaengerrangierassistent" 7 "fernbedienter_Anhaengerrangierassistent" ;
VAL_ 518 Parken_max_Beschleunigung 0 "Inaktiv" 122 "Init" 127 "Fehler" ;
VAL_ 518 Parken_QFK_KruemmSoll_VZ 0 "positiv" 1 "negativ" ;
VAL_ 518 Parken_QFK_AnfStat 1 "Init" 2 "Bereit" 4 "Eingriff" ;
VAL_ 518 Parken_Sollbeschleunigung 0 "Neutralwert" ;
VAL_ 518 Parken_Status_IPA_TSK 1 "IPA_TSK_Init" 2 "IPA_TSK_Fehler" 4 "IPA_TSK_aktivierbar" 5 "IPA_TSK_pausiert" 6 "IPA_TSK_aktiv" 8 "IPA_TSK_funktionsbereit" ;
VAL_ 518 Parken_erhoehtes_Moment 0 "keine_Anforderung" 1 "Anforderung_Rampe1" 2 "Anforderung_Rampe2" 3 "Anforderung_Rampe3" 4 "Anforderung_Rampe4" 5 "Anforderung_Rampe5" 6 "Anforderung_Rampe6" 7 "Anforderung_Rampe7" 8 "Anforderung_Rampe8" 9 "Anforderung_Rampe9" 10 "Anforderung_Rampe10" 11 "Anforderung_Rampe11" 12 "Anforderung_Rampe12" 13 "Anforderung_Rampe13" 14 "Anforderung_Rampe14" 15 "Anforderung_Rampe15" ;
VAL_ 518 Parken_max_Geschwindigkeit 0 "Inaktiv" 251 "Init" 255 "Fehler" ;
VAL_ 518 Parken_Soll_Anhalteweg_Anf 1022 "Neutralwert" 1023 "Fehler" ;
VAL_ 518 Parken_Fahrstufenwunsch 0 "Init" 1 "Fahrstufe_beibehalten" 2 "Position_R" 3 "Position_D" 4 "Position_N" ;
VAL_ 518 Parken_Schleichfahrt_Anf 0 "keine_Anforderung" 1 "Schleichfahrt_angefordert" ;
VAL_ 518 Parken_Bordstein_Winkel 0 "Neutralwert" ;
VAL_ 518 IPA_TPA_Remote 0 "nicht_aktiv" 1 "aktiv" 2 "Uebergabe" 3 "Uebernahme" ;
VAL_ 518 IPA_TPA_Remote_Anf 0 "keine_Anforderung" 1 "Remote_Anforderung" 2 "Remote_Zug_rueckgaengig" ;
VAL_ 518 IPA_TPA_Fehler 0 "Init_kein_Fehler" 1 "IPA_Systemfehler" 2 "RPA_Systemfehler" 3 "temporaerer_Fehler" 4 "sonstiger_Fehler" ;
VAL_ 518 IPA_TPA_Abbruch 0 "Init_kein_Abbruch" 1 "Hindernis" 2 "Manoever_nicht_fahrbar" 3 "Abbruch_mit_Wiederaufnahme" 4 "Abbruch_ohne_Wiederaufnahme" 5 "temporaerer_Fehler" 6 "sonstiger_Fehler" ;
VAL_ 518 IPA_TPA_Status 0 "deaktiv" 1 "Init" 4 "startbereit" 6 "Regelung_aktiv" 7 "Parkvorgang_abgeschlossen" 8 "funktionsbereit" 9 "Unterbrechung" 10 "Abbruch" 15 "Error" ;
VAL_ 1175 PH_Visualisierung 0 "Aus" 1 "Angefragt" 2 "InAnzeige" 3 "Abgefordert" 6 "Init" 7 "Fehler" ;
VAL_ 1175 PDC_Tonausgabe_Front 0 "kein_Ton" 1 "Intervallton_1" 2 "Intervallton_2" 3 "Intervallton_3" 4 "Intervallton_4" 5 "Intervallton_5" 6 "Dauerton" 7 "Fehlerton" 8 "RCTATon" ;
VAL_ 1175 PDC_Tonausgabe_Heck 0 "kein_Ton" 1 "Intervallton_1" 2 "Intervallton_2" 3 "Intervallton_3" 4 "Intervallton_4" 5 "Intervallton_5" 6 "Dauerton" 7 "Fehlerton" 8 "Erstwarnton_hinten" 9 "RCTATon" ;
VAL_ 1175 PH_nachtr_Stopp_Anf 0 "nicht_angefordert" 1 "angefordert" ;
VAL_ 1175 PH_Abschaltursache 0 "keine, bzw. System aktiv" 1 "Abschaltung durch Herausnahme R-Gang" 2 "Abschaltung ueber Geschwindigkeit" 3 "Abschaltung ueber PDC-Taster" 4 "Abschaltung wegen PLA" 5 "Abschaltung durch KL 15 Bit = 0" 6 "tbd." 7 "Fehler-/gestört Zustand, System noch aktiv" ;
VAL_ 1175 PH_Opt_Anzeige_V_ein 0 "optische Anzeige vorne nicht aktiv" 1 "optische Anzeige vorne aktiviert" ;
VAL_ 1175 PH_Opt_Anzeige_H_ein 0 "Optische Anzeige aus" 1 "optische Anzeige hinten aktiviert" ;
VAL_ 1175 PH_Opt_Anz_V_Hindernis 0 "optische Anzeige vorne meldet kein Hindernis" 1 "optische Anzeige vorne meldet Hindernis im Warnbereich" ;
VAL_ 1175 PH_Opt_Anz_H_Hindernis 0 "optische Anzeige hinten meldet kein Hindernis" 1 "optische Anzeige hinten meldet Hindernis im Warnbereich" ;
VAL_ 1175 PH_Tongeber_V_aktiv 0 "Tongeber vorne nicht aktiv" 1 "Tongeber vorne  aktiv" ;
VAL_ 1175 PH_Tongeber_H_aktiv 0 "Tongeber hinten nicht aktiv" 1 "Tongeber hinten aktiv" ;
VAL_ 1175 PH_Tongeber_mute 0 "Tongeber nicht stummgeschaltet" 1 "Tongeber stummgeschaltet" ;
VAL_ 1175 PH_Anf_Audioabsenkung 0 "Keine_Audioabsenkung" 1 "Anforderung_Audioabsenkung" ;
VAL_ 1175 PH_Tongeber_H_verfuegbar 0 "nicht verfügbar" 1 "verfügbar" ;
VAL_ 1175 PLA_Anf_Aufschaltung_RVC 0 "Keine_RVC_Aufschalteanf" 1 "RVC_Aufschalteanforderung" ;
VAL_ 1175 PH_Taster 0 "Taster_nicht_gedrueckt" 1 "Taster_gedrueckt" 2 "reserviert" 3 "Fehler" ;
VAL_ 1175 PH_Anf_Verdeck 0 "Verdeckbetrieb_freigegeben" 1 "Verdeckbetrieb_sperren" 2 "reserviert" 3 "reserviert" ;
VAL_ 1175 PH_StartStopp_Info 0 "Motorlauf_nicht_notwendig_(Stoppfreigabe)" 1 "Motoranlauf_nicht_zwingend_notwendig_(Stoppverbot,keine_Startanforderung)" 2 "Motoranlauf_zwingend_notwendig_(Startanforderung)" 3 "Systemfehler" ;
VAL_ 1175 PH_Stoermeldung 0 "keine_Anzeige_kein_Gong" 1 "Textmeldung_PDC_hinten_gestoert_mit_Gong" 2 "Textmeldung_PDC_hinten_gestoert_ohne_Gong" 3 "Textmeldung_PDC_vorn_gestoert_mit_Gong" 4 "Textmeldung_PDC_vorn_gestoert_ohne_Gong" 5 "Textmeldung_PDC_gestoert_mit_Gong" 6 "Textmeldung_PDC_gestoert_ohne_Gong" 7 "Textmeldung_PDC_seitlich_gestoert_mit_Gong" 8 "Textmeldung_PDC_seitlich_gestoert_ohne_Gong" ;
VAL_ 1175 PH_defekt 0 "PH aktiv" 1 "PH wurde aufgrund eines Defektes deaktiviert" ;
VAL_ 1175 PH_gestoert 0 "PH aktiv" 1 "PH wurde auf Grund einer Stoerung tempraer deaktiviert" ;
VAL_ 1175 PH_Systemzustand 0 "Anlage aus" 1 "Anlage durch einlegen R-Gang aktiviert" 2 "Anlage manuell durch Taster aktiviert" 3 "Anlage automatisch aktiviert" 4 "Anlage durch ARA aktiviert" 6 "Init - Initialisierungsphase nach Kl. 15 ein / Reset" 7 "Fehler-/gestört Zustand, System noch aktiv" ;
VAL_ 1175 PH_Display_Kundenwunsch 0 "Anzeige aus" 1 "Grafik" 2 "Rear View" 3 "automatisch" ;
VAL_ 1122 PSD_Segment_ID 0 "keine Segmentinformationen vorhanden" 1 "Fehlerwert" ;
VAL_ 1122 PSD_Vorgaenger_Segment_ID 0 "keine Segmentinformation vorhanden" 1 "Fehlerwert" ;
VAL_ 1122 PSD_Strassenkategorie 0 "Rest_Feldweg_Schotterweg_Privatweg" 1 "Ortsstraße" 2 "Kreisstraße" 3 "Landstraße" 4 "Bundesstraße" 5 "Autobahn" 7 "Init" ;
VAL_ 1122 PSD_Endkruemmung 255 "Gerade" ;
VAL_ 1122 PSD_Endkruemmung_Vorz 0 "Kruemmung_positiv" 1 "Kruemmung_negativ" ;
VAL_ 1122 PSD_Idenditaets_ID 0 "keine_Segment_Informationen_vorhanden" 1 "Fehler" ;
VAL_ 1122 PSD_ADAS_Qualitaet 0 "keine_ADAS_Qualitaet" 1 "ADAS_Qualitaet" ;
VAL_ 1122 PSD_wahrscheinlichster_Pfad 0 "Pfad_mit_geringer_Wahrscheinlichkeit" 1 "wahrscheinlichster_Pfad" ;
VAL_ 1122 PSD_Geradester_Pfad 0 "nicht_geradester_PFad" 1 "geradester_Pfad" ;
VAL_ 1122 PSD_Fahrspuren_Anzahl 0 "Einbahnstrasse_in_falsche_Richtung" 1 "eine_Fahrspur" 2 "zwei_Fahrspuren" 3 "drei_Fahrspuren" 4 "vier_Fahrspuren" 5 "fuenf_Fahrspuren" 6 "sechs_Fahrspuren" 7 "mehr_als_sechs_Fahrspuren" ;
VAL_ 1122 PSD_Bebauung 0 "ausserhalb_bebauten_Gebietes" 1 "innerhalb_bebauten_Gebietes" ;
VAL_ 1122 PSD_Segment_Komplett 0 "Segment_Attribute_nicht_komplett" 1 "Segment_Attribute_komplett" ;
VAL_ 1122 PSD_Rampe 0 "Strasse_mit_Gegenverkehr" 1 "Auffahrt_Einbahnstr" 2 "Abfahrt_Einbahnstr" 3 "Einbahnstrasse" ;
VAL_ 1122 PSD_Anfangskruemmung 255 "Gerade" ;
VAL_ 1122 PSD_Anfangskruemmung_Vorz 0 "positiv" 1 "negativ" ;
VAL_ 1122 PSD_Abzweigerichtung 0 "rects_abzweigende_Strasse" 1 "links_abzweigende_Strasse" ;
VAL_ 1123 PSD_Pos_Segment_ID 0 "keine Position gegeben" 1 "Fehlerwert" ;
VAL_ 1123 PSD_Pos_Standort_Eindeutig 0 "mehrdeutiger_Standort" 1 "eindeutiger_Standort" ;
VAL_ 1123 PSD_Pos_Fehler_Laengsrichtung 0 "Init" 1 "< 2m" 2 "< 5m" 3 "< 10m" 4 "< 20m" 5 "< 50m" 6 "> 50m" 7 "Off-Road" ;
VAL_ 1123 PSD_Pos_Fahrspur 0 "unbekannt" 1 "Erste_Spur_von_rechts" 2 "Zweite_Spur_von_rechts" 3 "Dritte_Spur_von_rechts" 4 "Vierte_Spur_von_rechts" 5 "Fuenfte_Spur_von_rechts" 6 "Sechte_Spur_von_rechts" 7 "Siebte_oder_weitere_Spur_von_rechts" ;
VAL_ 1123 PSD_Attribut_Segment_ID_05 0 "keine_Segment_Information" 1 "Fehler" ;
VAL_ 1123 PSD_Attribut_1_ID 0 "keine_Information" ;
VAL_ 1123 PSD_Attribut_2_ID 0 "keine_Information" ;
VAL_ 1123 PSD_Attribute_Komplett_05 0 "Attribute_nicht_komplett" 1 "Attribute_komplett" ;
VAL_ 1124 PSD_06_Mux 0 "Init" ;
VAL_ 1124 PSD_Sys_Segment_ID 0 "keine Segmentinformationen vorhanden" 1 "nicht zulaessig" ;
VAL_ 1124 PSD_Attribut_Segment_ID 0 "keine_Segment_Information_vorhanden" 1 "Fehler" ;
VAL_ 1124 PSD_Ges_Segment_ID 0 "keine Segmentinformationen vorhanden" 1 "nicht zulaessig" ;
VAL_ 1124 PSD_Baum_Laenge_VZ 0 "Ost" 1 "West" ;
VAL_ 1124 PSD_Steigung_1_Segment_ID 0 "keine_Segment_Information_vorhanden" 1 "Fehler" ;
VAL_ 1124 PSD_Baum_Laenge 33554431 "keine_GPS_Information" ;
VAL_ 1124 PSD_Attribut_3_ID 0 "keine_Information" ;
VAL_ 1124 PSD_Steigung_1_A_Steigung 126 "mehr_als_15_Prozent" 127 "Steigung_unbekannt" ;
VAL_ 1124 PSD_Ges_Geschwindigkeit 0 "Kein Geschwindigkeitsgebot" 1 "0 km/h < v_max <  5 km/h" 2 "5 km/h < v_max < 10km/h" 3 "10 km/h < v_max < 15 km/h" 4 "15 km/h < v_max < 20 km/h" 5 "20 km/h < v_max < 25 km/h" 6 "25 km/h < v_max < 30 km/h" 7 "30 km/h < v_max < 35 km/h" 8 "35 km/h < v_max < 40 km/h" 9 "40 km/h < v_max < 45 km/h" 10 "45 km/h < v_max < 50 km/h" 11 "50 km/h < v_max < 60 km/h" 12 "60 km/h < v_max < 70 km/h" 13 "70 km/h < v_max < 80 km/h" 14 "80 km/h < v_max < 90 km/h" 15 "90 km/h < v_max < 100 km/h" 16 "100 km/h < v_max < 110 km/h" 17 "110 km/h < v_max < 120 km/h" 18 " 120 km/h < v_max < 130 km/h" 19 "130 km/h < v_max < 140 km/h" 20 "140 km/h < v_max < 150 km/h" 21 "150 km/h < v_max < 160 km/h" 22 "160 km/h < v_max" 23 "Geschwindigkeitsgebot aufgehoben" 24 "..0x1F ungültig" ;
VAL_ 1124 PSD_Steigung_1_A_Vorz 0 "Gefaelle" 1 "Steigung" ;
VAL_ 1124 PSD_Sys_Geschwindigkeit_Einheit 0 "km/h" 1 "mph" ;
VAL_ 1124 PSD_Sys_Verkehrsrichtung 0 "Rechtsverkehr" 1 "Linksverkehr" ;
VAL_ 1124 PSD_Sys_Geometrieguete 0 "Geringe_Guete" 1 "tbd" 2 "tbd" 3 "Hohe_Guete" ;
VAL_ 1124 PSD_Sys_Mapmatchingguete 0 "geringe_Guete" 1 "res" 2 "res" 3 "hohe_Guete" ;
VAL_ 1124 PSD_Ges_Typ 0 "Geschw_Klasse_des_Kartendatensuppliers" 1 "Explizit_abgeleiteten_Begrenzung" 2 "Durch_Gesetzg_vorgeg_allgem_Gebot_fuer_uebertr_Rahmenbed" 3 "Init" ;
VAL_ 1124 PSD_Sys_Alter_Karte 0 "kleiner_1_Jahr" 1 "1_Jahr" 2 "2_Jahre" 3 "3_Jahre" 4 "4_Jahre" 5 "5_Jahre" 6 "6_Jahre" 7 "groesser_7_Jahre" ;
VAL_ 1124 PSD_Ges_Spur_Geschw_Begrenzung 0 "Gebot_fuer_alle_spuren_gueltig" ;
VAL_ 1124 PSD_Steigung_1_B_Steigung 126 "mehr_als_15_Prozent" 127 "Steigung_unbekannt" ;
VAL_ 1124 PSD_Attribut_4_ID 0 "keine_Information" ;
VAL_ 1124 PSD_Sys_Zielfuehrung 0 "Zielfuehrung nicht aktiv" 1 "Zielfuehrung aktiv" ;
VAL_ 1124 PSD_Sys_US_State 0 "kein_US_State" 1 "Alabama" 2 "Alaska" 3 "Arkansas" 4 "Arizona" 5 "California" 6 "Colorado" 7 "Conneticut" 8 "District_of_Columbia" 9 "Delaware" 10 "Florida" 11 "Georgia" 12 "Hawaii" 13 "Idaho" 14 "Illinois" 15 "Iowa" 16 "Indiana" 17 "Kansas" 18 "Kentucky" 19 "Louisiana" 20 "Massachusetts" 21 "Maryland" 22 "Maine" 23 "Michigan" 24 "Minnesota" 25 "Missouri" 26 "Mississippi" 27 "Montana" 28 "North_Carolina" 29 "North_Dakota" 30 "Nebraska" 31 "Nevada" 32 "New_Hampshire" 33 "New_Jersey" 34 "New_Mexico" 35 "New_York" 36 "Ohio" 37 "Oklahoma" 38 "Oregon" 39 "Pennsylvania" 40 "Puerto_Rico" 41 "Rhode_Island" 42 "South_Carolina" 43 "South_Dakota" 44 "Tennessee" 45 "Texas" 46 "Utah" 47 "Virginia" 48 "Virgin_Islands" 49 "Vermont" 50 "Washington" 51 "Wisconsin" 52 "West_Virginia" 53 "Wyoming" ;
VAL_ 1124 PSD_Ges_Geschwindigkeit_Gespann 0 "alle Fahrzeuge" 1 "PKW mit Gespann" 2 "LKW, Busse, etc." ;
VAL_ 1124 PSD_Baum_Breite_VZ 0 "Nord" 1 "Sued" ;
VAL_ 1124 PSD_Ges_Geschwindigkeit_Witter 0 "Witterungsunabhängig" 1 "Nässe, Regen, Niederschlag" 2 "Glätte" 3 "Nebel" ;
VAL_ 1124 PSD_Steigung_1_B_Vorz 0 "Gefaelle" 1 "Steigung" ;
VAL_ 1124 PSD_Ges_Geschwindigkeit_Tag_Anf 0 "kein Beginn definiert" 1 "Montag" 2 "Dienstag" 3 "Mittwoch" 4 "Donnerstag" 5 "Freitag" 6 "Samstag" 7 "Sonntag" ;
VAL_ 1124 PSD_Ges_Geschwindigkeit_Tag_Ende 0 "kein Ende definiert" 1 "Montag" 2 "Dienstag" 3 "Mittwoch" 4 "Donnerstag" 5 "Freitag" 6 "Samstag" 7 "Sonntag" ;
VAL_ 1124 PSD_Sys_Quali_verfuegbar 0 "Qualitaetskriterien_nicht_verfuegbar" 1 "Qualitaetskriterien_verfuegbar" ;
VAL_ 1124 PSD_Sys_Zielfuehrung_geaendert 0 "Zielfuehrung_nicht_geaendert" 1 "Zielfuehrung_geaendert" ;
VAL_ 1124 PSD_Ges_Geschwindigkeit_Std_Anf 25 "kein Beginn für stundenweise Einschränkungen" ;
VAL_ 1124 PSD_Steigung_1_Attribute_kompl 0 "Steigungen_nicht_komplett" 1 "Steigungen_komplett" ;
VAL_ 1124 PSD_Sys_Geometrieguete_erweitert 0 "Init" ;
VAL_ 1124 PSD_Steigung_2_Segment_ID 0 "keine_Segment_Information_vorhanden" 1 "Fehler" ;
VAL_ 1124 PSD_Attribut_5_ID 0 "keine_Information" ;
VAL_ 1124 PSD_Ges_Geschwindigkeit_Std_Ende 25 "kein Ende für stundenweise Einschränkungen" ;
VAL_ 1124 PSD_Steigung_2_Steigung 126 "mehr_als_15_Prozent" 127 "Steigung_unbekannt" ;
VAL_ 1124 PSD_Ges_Ueberholverbot 0 "kein Überholverbot" 1 "alle Fahrzeuge" 2 "Überholverbot für PKW mit Gespann" 3 "Überholverbot für LKW, Busse, etc." ;
VAL_ 1124 PSD_Ges_Wechselverkehrszeichen 0 "Kein Wechselverkehrszeichen" 1 "Wechselverkehrszeichen links" 2 "Wechselverkehrszeichen rechts" 3 "Wechselverkehrszeichen links und rechts" 4 "Wechselverkerhszeichen über der Fahrbahn" ;
VAL_ 1124 PSD_Steigung_2_Vorz 0 "Gefaelle" 1 "Steigung" ;
VAL_ 1124 PSD_Wechselverkehrszeichen_Typ 0 "kein_Wechselverkehrszeichen" 1 "LED_Wechselverkehrszeichen" 2 "nicht_LED_Wechselverkehrszeichen" ;
VAL_ 1124 PSD_Ges_Gesetzlich_Kategorie 0 "kein_legales_Verbot" 1 "innerorts" 2 "ausserorts" 3 "Autobahn" ;
VAL_ 1124 PSD_Attribute_Komplett_06 0 "Attribute_nicht_komplett" 1 "Attribute_komplett" ;
VAL_ 1124 PSD_Ges_Gesetzlich_Zusatz 0 "kein_Zusatz_zu_legalem_Gebot" 1 "Anhaenger_Klasse_1" 2 "Anhaenger_Klasse_2" ;
VAL_ 1124 PSD_Ges_Verkehrszeichen_Quelle 0 "VZA_kein_Onlinedienst" 1 "nur_VZA" 2 "nur_VZO" 3 "VZA_und_VZO" ;
VAL_ 1124 PSD_Steigung_2_Attribute_kompl 0 "Steigungen_nicht_komplett" 1 "Steigungen_komplett" ;
VAL_ 1124 PSD_Ges_Attribute_Komplett 0 "Attribute_nicht_komplett" 1 "Attribute_komplett" ;
VAL_ 1125 PSD_LR_01_MUX 0 "Init" ;
VAL_ 1125 PSD_LR_Attribut_1_Wert 0 "Init" ;
VAL_ 1125 PSD_LR_Steigung_1_Vorz 0 "Gefaelle" 1 "Steigung" ;
VAL_ 1125 PSD_LR_Globale_Steigung_Vorz 0 "Gefaelle" 1 "Steigung" ;
VAL_ 1125 PSD_LR_Attribut_2_Wert 0 "Init" ;
VAL_ 1125 PSD_LR_Steigung_2_Vorz 0 "Gefaelle" 1 "Steigung" ;
VAL_ 1125 PSD_LR_Attribut_3_Wert 0 "Init" ;
VAL_ 1125 PSD_LR_Steigung_3_Vorz 0 "Gefaelle" 1 "Steigung" ;
VAL_ 1125 PSD_LR_Reset 0 "kein Reset" 1 "Reset" ;
